AUTOSAR XML (schema 4-2-2)
package /STELLANTIS/EPT/ASWCs
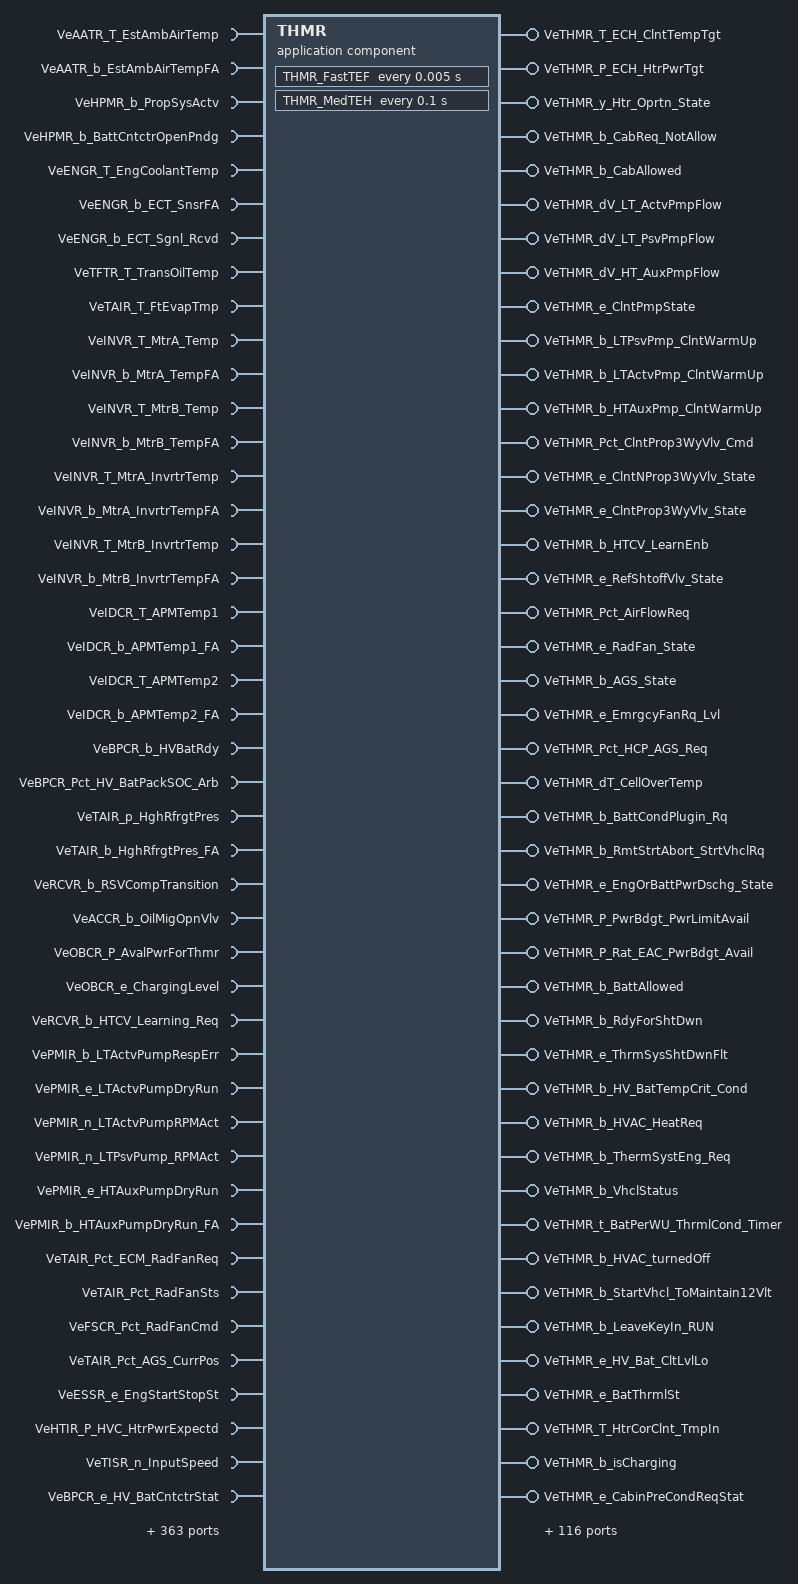
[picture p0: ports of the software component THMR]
  application sw component type THMR
    404 x require port:
      VeAATR_T_EstAmbAirTemp: nonqueued-receiver-com-spec{data-element=Value, init-value=0}, required-interface=VeAATR_T_EstAmbAirTemp
      VeAATR_b_EstAmbAirTempFA: nonqueued-receiver-com-spec{data-element=Value, init-value=0}, required-interface=VeAATR_b_EstAmbAirTempFA
      VeHPMR_b_PropSysActv: nonqueued-receiver-com-spec{data-element=Value, init-value=0}, required-interface=VeHPMR_b_PropSysActv
      VeHPMR_b_BattCntctrOpenPndg: nonqueued-receiver-com-spec{data-element=Value, init-value=0}, required-interface=VeHPMR_b_BattCntctrOpenPndg
      VeENGR_T_EngCoolantTemp: nonqueued-receiver-com-spec{data-element=Value, init-value=0}, required-interface=VeENGR_T_EngCoolantTemp
      VeENGR_b_ECT_SnsrFA: nonqueued-receiver-com-spec{data-element=Value, init-value=0}, required-interface=VeENGR_b_ECT_SnsrFA
      VeENGR_b_ECT_Sgnl_Rcvd: nonqueued-receiver-com-spec{data-element=Value, init-value=0}, required-interface=VeENGR_b_ECT_Sgnl_Rcvd
      VeTFTR_T_TransOilTemp: nonqueued-receiver-com-spec{data-element=Value, init-value=0}, required-interface=VeTFTR_T_TransOilTemp
      VeTAIR_T_FtEvapTmp: nonqueued-receiver-com-spec{data-element=Value, init-value=0}, required-interface=VeTAIR_T_FtEvapTmp
      VeINVR_T_MtrA_Temp: nonqueued-receiver-com-spec{data-element=Value, init-value=0}, required-interface=VeINVR_T_MtrA_Temp
      VeINVR_b_MtrA_TempFA: nonqueued-receiver-com-spec{data-element=Value, init-value=0}, required-interface=VeINVR_b_MtrA_TempFA
      VeINVR_T_MtrB_Temp: nonqueued-receiver-com-spec{data-element=Value, init-value=0}, required-interface=VeINVR_T_MtrB_Temp
      VeINVR_b_MtrB_TempFA: nonqueued-receiver-com-spec{data-element=Value, init-value=0}, required-interface=VeINVR_b_MtrB_TempFA
      VeINVR_T_MtrA_InvrtrTemp: nonqueued-receiver-com-spec{data-element=Value, init-value=0}, required-interface=VeINVR_T_MtrA_InvrtrTemp
      VeINVR_b_MtrA_InvrtrTempFA: nonqueued-receiver-com-spec{data-element=Value, init-value=0}, required-interface=VeINVR_b_MtrA_InvrtrTempFA
      VeINVR_T_MtrB_InvrtrTemp: nonqueued-receiver-com-spec{data-element=Value, init-value=0}, required-interface=VeINVR_T_MtrB_InvrtrTemp
      VeINVR_b_MtrB_InvrtrTempFA: nonqueued-receiver-com-spec{data-element=Value, init-value=0}, required-interface=VeINVR_b_MtrB_InvrtrTempFA
      VeIDCR_T_APMTemp1: nonqueued-receiver-com-spec{data-element=Value, init-value=0}, required-interface=VeIDCR_T_APMTemp1
      VeIDCR_b_APMTemp1_FA: nonqueued-receiver-com-spec{data-element=Value, init-value=0}, required-interface=VeIDCR_b_APMTemp1_FA
      VeIDCR_T_APMTemp2: nonqueued-receiver-com-spec{data-element=Value, init-value=0}, required-interface=VeIDCR_T_APMTemp2
      VeIDCR_b_APMTemp2_FA: nonqueued-receiver-com-spec{data-element=Value, init-value=0}, required-interface=VeIDCR_b_APMTemp2_FA
      VeBPCR_b_HVBatRdy: nonqueued-receiver-com-spec{data-element=Value, init-value=0}, required-interface=VeBPCR_b_HVBatRdy
      VeBPCR_Pct_HV_BatPackSOC_Arb: nonqueued-receiver-com-spec{data-element=Value, init-value=0}, required-interface=VeBPCR_Pct_HV_BatPackSOC_Arb
      VeTAIR_p_HghRfrgtPres: nonqueued-receiver-com-spec{data-element=Value, init-value=0}, required-interface=VeTAIR_p_HghRfrgtPres
      VeTAIR_b_HghRfrgtPres_FA: nonqueued-receiver-com-spec{data-element=Value, init-value=0}, required-interface=VeTAIR_b_HghRfrgtPres_FA
      VeRCVR_b_RSVCompTransition: nonqueued-receiver-com-spec{data-element=Value, init-value=0}, required-interface=VeRCVR_b_RSVCompTransition
      VeACCR_b_OilMigOpnVlv: nonqueued-receiver-com-spec{data-element=Value, init-value=0}, required-interface=VeACCR_b_OilMigOpnVlv
      VeOBCR_P_AvalPwrForThmr: nonqueued-receiver-com-spec{data-element=Value, init-value=0}, required-interface=VeOBCR_P_AvalPwrForThmr
      VeOBCR_e_ChargingLevel: nonqueued-receiver-com-spec{data-element=Value, init-value=CeOBCR_e_ChargingLvlDefault}, required-interface=VeOBCR_e_ChargingLevel
      VeRCVR_b_HTCV_Learning_Req: nonqueued-receiver-com-spec{data-element=Value, init-value=0}, required-interface=VeRCVR_b_HTCV_Learning_Req
      VePMIR_b_LTActvPumpRespErr: nonqueued-receiver-com-spec{data-element=Value, init-value=0}, required-interface=VePMIR_b_LTActvPumpRespErr
      VePMIR_e_LTActvPumpDryRun: nonqueued-receiver-com-spec{data-element=Value, init-value=CePMPR_e_FTSNA_False}, required-interface=VePMIR_e_LTActvPumpDryRun
      VePMIR_n_LTActvPumpRPMAct: nonqueued-receiver-com-spec{data-element=Value, init-value=0}, required-interface=VePMIR_n_LTActvPumpRPMAct
      VePMIR_n_LTPsvPump_RPMAct: nonqueued-receiver-com-spec{data-element=Value, init-value=0}, required-interface=VePMIR_n_LTPsvPump_RPMAct
      VePMIR_e_HTAuxPumpDryRun: nonqueued-receiver-com-spec{data-element=Value, init-value=CePMPR_e_FTSNA_False}, required-interface=VePMIR_e_HTAuxPumpDryRun
      VePMIR_b_HTAuxPumpDryRun_FA: nonqueued-receiver-com-spec{data-element=Value, init-value=0}, required-interface=VePMIR_b_HTAuxPumpDryRun_FA
      VeTAIR_Pct_ECM_RadFanReq: nonqueued-receiver-com-spec{data-element=Value, init-value=0}, required-interface=VeTAIR_Pct_ECM_RadFanReq
      VeTAIR_Pct_RadFanSts: nonqueued-receiver-com-spec{data-element=Value, init-value=0}, required-interface=VeTAIR_Pct_RadFanSts
      VeFSCR_Pct_RadFanCmd: nonqueued-receiver-com-spec{data-element=Value, init-value=0}, required-interface=VeFSCR_Pct_RadFanCmd
      VeTAIR_Pct_AGS_CurrPos: nonqueued-receiver-com-spec{data-element=Value, init-value=0}, required-interface=VeTAIR_Pct_AGS_CurrPos
      VeESSR_e_EngStartStopSt: nonqueued-receiver-com-spec{data-element=Value, init-value=CeESSR_e_EngOff}, required-interface=VeESSR_e_EngStartStopSt
      VeHTIR_P_HVC_HtrPwrExpectd: nonqueued-receiver-com-spec{data-element=Value, init-value=0}, required-interface=VeHTIR_P_HVC_HtrPwrExpectd
      VeTISR_n_InputSpeed: nonqueued-receiver-com-spec{data-element=Value, init-value=0}, required-interface=VeTISR_n_InputSpeed
      VeBPCR_e_HV_BatCntctrStat: nonqueued-receiver-com-spec{data-element=Value, init-value=CeHVTR_e_Open}, required-interface=VeBPCR_e_HV_BatCntctrStat
      VeTRGR_e_TransDirctnSt: nonqueued-receiver-com-spec{data-element=Value, init-value=CeTRGR_e_NoSelectionAvailable}, required-interface=VeTRGR_e_TransDirctnSt
      VeCSVR_v_VehSpd: nonqueued-receiver-com-spec{data-element=Value, init-value=0}, required-interface=VeCSVR_v_VehSpd
      VePLTR_b_DrvDrAjar: nonqueued-receiver-com-spec{data-element=Value, init-value=0}, required-interface=VePLTR_b_DrvDrAjar
      VeSSDR_e_KeySts: nonqueued-receiver-com-spec{data-element=Value, init-value=CeSSDR_e_KeyOff}, required-interface=VeSSDR_e_KeySts
      VeACCR_b_OverTempImminent: nonqueued-receiver-com-spec{data-element=Value, init-value=0}, required-interface=VeACCR_b_OverTempImminent
      VeTAIR_b_ACCompReq: nonqueued-receiver-com-spec{data-element=Value, init-value=0}, required-interface=VeTAIR_b_ACCompReq
      VeIMPR_b_HighVoltageRapidShtdwnCmnd: nonqueued-receiver-com-spec{data-element=Value, init-value=0}, required-interface=VeIMPR_b_HighVoltageRapidShtdwnCmnd
      VeENGR_b_EngSysLowFuel: nonqueued-receiver-com-spec{data-element=Value, init-value=0}, required-interface=VeENGR_b_EngSysLowFuel
      VeMSPR_n_MtrA_Spd: nonqueued-receiver-com-spec{data-element=Value, init-value=0}, required-interface=VeMSPR_n_MtrA_Spd
      VeMSPR_n_MtrB_Spd: nonqueued-receiver-com-spec{data-element=Value, init-value=0}, required-interface=VeMSPR_n_MtrB_Spd
      VeHTDR_M_MtrA_TorqCmnd: nonqueued-receiver-com-spec{data-element=Value, init-value=0}, required-interface=VeHTDR_M_MtrA_TorqCmnd
      VeMTIR_M_MtrA_TorqAchieved: nonqueued-receiver-com-spec{data-element=Value, init-value=0}, required-interface=VeMTIR_M_MtrA_TorqAchieved
      VeHTDR_M_MtrB_TorqCmnd: nonqueued-receiver-com-spec{data-element=Value, init-value=0}, required-interface=VeHTDR_M_MtrB_TorqCmnd
      VeMTIR_M_MtrB_TorqAchieved: nonqueued-receiver-com-spec{data-element=Value, init-value=0}, required-interface=VeMTIR_M_MtrB_TorqAchieved
      VeHTDR_P_MtrAElecPwrCalcTot: nonqueued-receiver-com-spec{data-element=Value, init-value=0}, required-interface=VeHTDR_P_MtrAElecPwrCalcTot
      VeHTDR_P_MtrBElecPwrCalcTot: nonqueued-receiver-com-spec{data-element=Value, init-value=0}, required-interface=VeHTDR_P_MtrBElecPwrCalcTot
      VeHTDR_r_AHH_StressFactor: nonqueued-receiver-com-spec{data-element=Value, init-value=0}, required-interface=VeHTDR_r_AHH_StressFactor
      VeBRKR_e_AHH_Ready_Status: nonqueued-receiver-com-spec{data-element=Value, init-value=CeBRKR_e_AHH_NotReady}, required-interface=VeBRKR_e_AHH_Ready_Status
      VeHTIR_T_HVC_HtrClntIn_Temp: nonqueued-receiver-com-spec{data-element=Value, init-value=0}, required-interface=VeHTIR_T_HVC_HtrClntIn_Temp
      VeTAIR_b_HT_CabVlvSts_FA: nonqueued-receiver-com-spec{data-element=Value, init-value=0}, required-interface=VeTAIR_b_HT_CabVlvSts_FA
      VeCPDR_b_HTAP_FunPer_FltDtct: nonqueued-receiver-com-spec{data-element=Value, init-value=0}, required-interface=VeCPDR_b_HTAP_FunPer_FltDtct
      VePMIR_b_LTPsvPumpTemp_FA: nonqueued-receiver-com-spec{data-element=Value, init-value=0}, required-interface=VePMIR_b_LTPsvPumpTemp_FA
      VeHTIR_e_HV_ElecClntHtr_Sts: nonqueued-receiver-com-spec{data-element=Value, init-value=CeHTIR_e_HtrSts_Off}, required-interface=VeHTIR_e_HV_ElecClntHtr_Sts
      VeINVR_T_MtrA_RotrTemp: nonqueued-receiver-com-spec{data-element=Value, init-value=0}, required-interface=VeINVR_T_MtrA_RotrTemp
      VeINVR_b_MtrA_RotrTemp_FA: nonqueued-receiver-com-spec{data-element=Value, init-value=0}, required-interface=VeINVR_b_MtrA_RotrTemp_FA
      VeINVR_T_MtrA_CtrlBoard_Temp: nonqueued-receiver-com-spec{data-element=Value, init-value=0}, required-interface=VeINVR_T_MtrA_CtrlBoard_Temp
      VeINVR_b_MtrA_CtrlBoard_Temp_FA: nonqueued-receiver-com-spec{data-element=Value, init-value=0}, required-interface=VeINVR_b_MtrA_CtrlBoard_Temp_FA
      VeINVR_T_MtrA_ClntIn_Temp: nonqueued-receiver-com-spec{data-element=Value, init-value=0}, required-interface=VeINVR_T_MtrA_ClntIn_Temp
      VeINVR_b_MtrA_ClntIn_Temp_FA: nonqueued-receiver-com-spec{data-element=Value, init-value=0}, required-interface=VeINVR_b_MtrA_ClntIn_Temp_FA
      VeINVR_T_MtrA_ClntOut_Temp: nonqueued-receiver-com-spec{data-element=Value, init-value=0}, required-interface=VeINVR_T_MtrA_ClntOut_Temp
      VeINVR_b_MtrA_ClntOut_Temp_FA: nonqueued-receiver-com-spec{data-element=Value, init-value=0}, required-interface=VeINVR_b_MtrA_ClntOut_Temp_FA
      VeINVR_T_MtrA_CapctrTemp: nonqueued-receiver-com-spec{data-element=Value, init-value=0}, required-interface=VeINVR_T_MtrA_CapctrTemp
      VeINVR_b_MtrA_CapctrTemp_FA: nonqueued-receiver-com-spec{data-element=Value, init-value=0}, required-interface=VeINVR_b_MtrA_CapctrTemp_FA
      VePMIR_Pct_ECM_LTPsvPumpRq: nonqueued-receiver-com-spec{data-element=Value, init-value=0}, required-interface=VePMIR_Pct_ECM_LTPsvPumpRq
      VePMIR_b_ECM_LTPsvPumpRq_FA: nonqueued-receiver-com-spec{data-element=Value, init-value=0}, required-interface=VePMIR_b_ECM_LTPsvPumpRq_FA
      VeENGR_T_InductionAirTemp: nonqueued-receiver-com-spec{data-element=Value, init-value=0}, required-interface=VeENGR_T_InductionAirTemp
      VeTPCR_t_BatPerWU_ThrmlCond_Timer: nonqueued-receiver-com-spec{data-element=Value, init-value=0}, required-interface=VeTPCR_t_BatPerWU_ThrmlCond_Timer
      VeTPCR_b_PeriodWup_Msg2: variation-point={short-label=vpVeTPCR_b_PeriodWup_Msg2, sw-syscond=1}, nonqueued-receiver-com-spec{data-element=Value, init-value=0}, required-interface=VeTPCR_b_PeriodWup_Msg2
      VeTPCR_e_ThrmPerWup_State: nonqueued-receiver-com-spec{data-element=Value, init-value=CeTPCR_e_NoWup_Set_ShortTim_RS_Denied}, required-interface=VeTPCR_e_ThrmPerWup_State
      VeTPCR_e_PerWup_BattEngCond_State: nonqueued-receiver-com-spec{data-element=Value, init-value=CeTPCR_e_NoneOfEngBatt_Cond}, required-interface=VeTPCR_e_PerWup_BattEngCond_State
      VeTPCR_dT_PerWpCond_EngTmpErr: nonqueued-receiver-com-spec{data-element=Value, init-value=0}, required-interface=VeTPCR_dT_PerWpCond_EngTmpErr
      VeTPCR_dT_PerWpCond_BatTmpErr: nonqueued-receiver-com-spec{data-element=Value, init-value=0}, required-interface=VeTPCR_dT_PerWpCond_BatTmpErr
      VeTPCR_e_CabinPreCondReqStat: nonqueued-receiver-com-spec{data-element=Value, init-value=CeTPCR_e_CabinPrec_Dflt}, required-interface=VeTPCR_e_CabinPreCondReqStat
      VeTPCR_b_RSA_BatCrit_Msg3: variation-point={short-label=vpVeTPCR_b_RSA_BatCrit_Msg3, sw-syscond=1}, nonqueued-receiver-com-spec{data-element=Value, init-value=0}, required-interface=VeTPCR_b_RSA_BatCrit_Msg3
      VeTPCR_b_HtrOrEAC_FltRawPrst: nonqueued-receiver-com-spec{data-element=Value, init-value=0}, required-interface=VeTPCR_b_HtrOrEAC_FltRawPrst
      VeTPCR_b_RdyForShtDwn: nonqueued-receiver-com-spec{data-element=Value, init-value=0}, required-interface=VeTPCR_b_RdyForShtDwn
      VeTRIR_T_HtrCorClnt_TmpIn: nonqueued-receiver-com-spec{data-element=Value, init-value=0}, required-interface=VeTRIR_T_HtrCorClnt_TmpIn
      VeTRIR_b_HtrCorClnt_TmpIn_FA: nonqueued-receiver-com-spec{data-element=Value, init-value=0}, required-interface=VeTRIR_b_HtrCorClnt_TmpIn_FA
      VeCTRR_b_HVAC_HeatReq: nonqueued-receiver-com-spec{data-element=Value, init-value=0}, required-interface=VeCTRR_b_HVAC_HeatReq
      VeCTRR_b_HardCabHeat_Req: nonqueued-receiver-com-spec{data-element=Value, init-value=0}, required-interface=VeCTRR_b_HardCabHeat_Req
      VeCTRR_b_CabPriorityHigh: nonqueued-receiver-com-spec{data-element=Value, init-value=0}, required-interface=VeCTRR_b_CabPriorityHigh
      VeBTRR_T_CellTempMaxUsed: nonqueued-receiver-com-spec{data-element=Value, init-value=0}, required-interface=VeBTRR_T_CellTempMaxUsed
      VeBTRR_T_CellTempMinUsed: nonqueued-receiver-com-spec{data-element=Value, init-value=0}, required-interface=VeBTRR_T_CellTempMinUsed
      VeBTRR_dT_CellTempDelta: nonqueued-receiver-com-spec{data-element=Value, init-value=0}, required-interface=VeBTRR_dT_CellTempDelta
      VeBTRR_b_HVBR_OvrdReq: variation-point={short-label=vpVeBTRR_b_HVBR_OvrdReq, sw-syscond=1}, nonqueued-receiver-com-spec{data-element=Value, init-value=0}, required-interface=VeBTRR_b_HVBR_OvrdReq
      VeBTRR_dT_CellOverTemp: nonqueued-receiver-com-spec{data-element=Value, init-value=0}, required-interface=VeBTRR_dT_CellOverTemp
      VeBTRR_dV_LT_ActPmpFlw: nonqueued-receiver-com-spec{data-element=Value, init-value=0}, required-interface=VeBTRR_dV_LT_ActPmpFlw
      VeBTRR_b_PerWup_BatToCond: nonqueued-receiver-com-spec{data-element=Value, init-value=0}, required-interface=VeBTRR_b_PerWup_BatToCond
      VeBTRR_b_HV_BatTempCrit_Cond: nonqueued-receiver-com-spec{data-element=Value, init-value=0}, required-interface=VeBTRR_b_HV_BatTempCrit_Cond
      VeBTRR_e_HV_BatTempCrit_CondState_New: nonqueued-receiver-com-spec{data-element=Value, init-value=CeBTRR_e_BatNotCrit}, required-interface=VeBTRR_e_HV_BatTempCrit_CondState_New
      VeBTRR_b_BattHeatReq: nonqueued-receiver-com-spec{data-element=Value, init-value=0}, required-interface=VeBTRR_b_BattHeatReq
      VeBTRR_b_isCharging: nonqueued-receiver-com-spec{data-element=Value, init-value=0}, required-interface=VeBTRR_b_isCharging
      VeBTRR_b_BattCondPlugin_Rq: variation-point={short-label=vpVeBTRR_b_BattCondPlugin_Rq, sw-syscond=1}, nonqueued-receiver-com-spec{data-element=Value, init-value=0}, required-interface=VeBTRR_b_BattCondPlugin_Rq
      VeBTRR_b_PlugdIn_Or_Chrg: nonqueued-receiver-com-spec{data-element=Value, init-value=0}, required-interface=VeBTRR_b_PlugdIn_Or_Chrg
      VeBTRR_b_BattCellBalancing: nonqueued-receiver-com-spec{data-element=Value, init-value=0}, required-interface=VeBTRR_b_BattCellBalancing
      VeBTRR_e_HV_BatTmpRng: nonqueued-receiver-com-spec{data-element=Value, init-value=CeBTRR_e_BatTmpDfltRng}, required-interface=VeBTRR_e_HV_BatTmpRng
      VeBTRR_b_Batt_CritOrMarg: nonqueued-receiver-com-spec{data-element=Value, init-value=0}, required-interface=VeBTRR_b_Batt_CritOrMarg
      VeBTRR_e_BatCondPriority: nonqueued-receiver-com-spec{data-element=Value, init-value=CeBTRR_e_BatCond_NoPriority}, required-interface=VeBTRR_e_BatCondPriority
      VeBTRR_b_VhclPlgdIn: nonqueued-receiver-com-spec{data-element=Value, init-value=0}, required-interface=VeBTRR_b_VhclPlgdIn
      VeBTRR_P_BatHeatPwr_NeedLimtd: nonqueued-receiver-com-spec{data-element=Value, init-value=0}, required-interface=VeBTRR_P_BatHeatPwr_NeedLimtd
      VeBRDR_e_HV_Bat_CltLvlLo: nonqueued-receiver-com-spec{data-element=Value, init-value=CeBRDR_e_BatCltLvlNotLo}, required-interface=VeBRDR_e_HV_Bat_CltLvlLo
      VeBTRR_T_BTISBTIS2_Max: nonqueued-receiver-com-spec{data-element=Value, init-value=0}, required-interface=VeBTRR_T_BTISBTIS2_Max
      VePMDR_e_KeyStatus: nonqueued-receiver-com-spec{data-element=Value, init-value=CePMDR_e_KeySt_Off}, required-interface=VePMDR_e_KeyStatus
      VePMPR_e_LTPsvPump_PstRnSt: nonqueued-receiver-com-spec{data-element=Value, init-value=CeTMIR_e_No_AftRunRequest}, required-interface=VePMPR_e_LTPsvPump_PstRnSt
      VeCTRR_b_TurnOffEng_CabComfAchvd: nonqueued-receiver-com-spec{data-element=Value, init-value=0}, required-interface=VeCTRR_b_TurnOffEng_CabComfAchvd
      VeCTRR_dT_HtrCorTmp_Err: nonqueued-receiver-com-spec{data-element=Value, init-value=0}, required-interface=VeCTRR_dT_HtrCorTmp_Err
      VePMIR_n_LTPsvPump2RPMAct: nonqueued-receiver-com-spec{data-element=Value, init-value=0}, required-interface=VePMIR_n_LTPsvPump2RPMAct
      VePMIR_b_LTPsvPump2Temp_FA: nonqueued-receiver-com-spec{data-element=Value, init-value=0}, required-interface=VePMIR_b_LTPsvPump2Temp_FA
      VePMPR_e_LTPsvPump2_PstRnSt: nonqueued-receiver-com-spec{data-element=Value, init-value=CeTMIR_e_No_AftRunRequest}, required-interface=VePMPR_e_LTPsvPump2_PstRnSt
      VePDTR_b_KeyRun_OV_BattCrit: nonqueued-receiver-com-spec{data-element=Value, init-value=0}, required-interface=VePDTR_b_KeyRun_OV_BattCrit
      VePDTR_e_EngOrBattPwrDschg_State: nonqueued-receiver-com-spec{data-element=Value, init-value=CePDTR_e_No_Dischrg}, required-interface=VePDTR_e_EngOrBattPwrDschg_State
      VePDTR_b_KeyRunCrnk_BattOV: nonqueued-receiver-com-spec{data-element=Value, init-value=0}, required-interface=VePDTR_b_KeyRunCrnk_BattOV
      VeHCDR_b_HVC_Heater_FltDtct: nonqueued-receiver-com-spec{data-element=Value, init-value=0}, required-interface=VeHCDR_b_HVC_Heater_FltDtct
      VeHCDR_b_HV_Heater{2..4}_FltDtct: nonqueued-receiver-com-spec{data-element=Value, init-value=0}, required-interface=VeHCDR_b_HV_Heater{2..4}_FltDtct
      VePMIR_b_LTActvPumpDryRun_FA: nonqueued-receiver-com-spec{data-element=Value, init-value=0}, required-interface=VePMIR_b_LTActvPumpDryRun_FA
      VeCPDR_b_LTAP_FunPer_FltDtct: nonqueued-receiver-com-spec{data-element=Value, init-value=0}, required-interface=VeCPDR_b_LTAP_FunPer_FltDtct
      VeTRIR_b_AHP_EnblReq: nonqueued-receiver-com-spec{data-element=Value, init-value=0}, required-interface=VeTRIR_b_AHP_EnblReq
      VeFSCR_b_HoodAjarBatCrit: nonqueued-receiver-com-spec{data-element=Value, init-value=0}, required-interface=VeFSCR_b_HoodAjarBatCrit
      VeAVTR_b_SDS_CoolingReq: nonqueued-receiver-com-spec{data-element=Value, init-value=0}, required-interface=VeAVTR_b_SDS_CoolingReq
      VeAVTR_e_EVA_ThrmlState: nonqueued-receiver-com-spec{data-element=Value, init-value=CeAVTR_e_NoEVACond}, required-interface=VeAVTR_e_EVA_ThrmlState
      VeFSCR_b_RadFan_FltDtct: nonqueued-receiver-com-spec{data-element=Value, init-value=0}, required-interface=VeFSCR_b_RadFan_FltDtct
      VeFSCR_b_HVFuncRejHdAjar: nonqueued-receiver-com-spec{data-element=Value, init-value=0}, required-interface=VeFSCR_b_HVFuncRejHdAjar
      VePMPR_b_LTPsvPump_Flt_Dtctd: nonqueued-receiver-com-spec{data-element=Value, init-value=0}, required-interface=VePMPR_b_LTPsvPump_Flt_Dtctd
      VePMPR_b_LTPsvPump2_Flt_Dtctd: nonqueued-receiver-com-spec{data-element=Value, init-value=0}, required-interface=VePMPR_b_LTPsvPump2_Flt_Dtctd
      VePMPR_b_LTActPump_Flt_Dtctd: nonqueued-receiver-com-spec{data-element=Value, init-value=0}, required-interface=VePMPR_b_LTActPump_Flt_Dtctd
      VePMPR_b_HTAuxPump_Flt_Dtctd: nonqueued-receiver-com-spec{data-element=Value, init-value=0}, required-interface=VePMPR_b_HTAuxPump_Flt_Dtctd
      VePMPR_n_PECP_RPM_Op_St: nonqueued-receiver-com-spec{data-element=Value, init-value=0}, required-interface=VePMPR_n_PECP_RPM_Op_St
      VePMPR_n_PECP2_RPM_Op_St: nonqueued-receiver-com-spec{data-element=Value, init-value=0}, required-interface=VePMPR_n_PECP2_RPM_Op_St
      VeHCDR_e_BatteryThermalFault: nonqueued-receiver-com-spec{data-element=Value, init-value=CeHCDR_e_BattThermalNoFault}, required-interface=VeHCDR_e_BatteryThermalFault
      VeHPMR_e_HybSysSt: nonqueued-receiver-com-spec{data-element=Value, init-value=CeHPMR_e_POWERUP}, required-interface=VeHPMR_e_HybSysSt
      VeBTRR_b_ThrmlBatCoolingFlt: nonqueued-receiver-com-spec{data-element=Value, init-value=0}, required-interface=VeBTRR_b_ThrmlBatCoolingFlt
      VeTPCR_t_SC_PrecTimer: nonqueued-receiver-com-spec{data-element=Value, init-value=0}, required-interface=VeTPCR_t_SC_PrecTimer
      VeTPCR_e_SC_WakeUp: nonqueued-receiver-com-spec{data-element=Value, init-value=CeTPCR_e_SC_NotAwake}, required-interface=VeTPCR_e_SC_WakeUp
      VeSRAR_b_ThmlLoadShdActv: nonqueued-receiver-com-spec{data-element=Value, init-value=0}, required-interface=VeSRAR_b_ThmlLoadShdActv
      VePLTR_t_RTC_CurrentTime: nonqueued-receiver-com-spec{data-element=Value, init-value=0}, required-interface=VePLTR_t_RTC_CurrentTime
      VePLTR_b_RTC_CurrentTimeFA: nonqueued-receiver-com-spec{data-element=Value, init-value=0}, required-interface=VePLTR_b_RTC_CurrentTimeFA
      VePLTR_t_RTC_SleepTime: nonqueued-receiver-com-spec{data-element=Value, init-value=0}, required-interface=VePLTR_t_RTC_SleepTime
      VeBPCR_e_BPCM_LIN_BusOff: nonqueued-receiver-com-spec{data-element=Value, init-value=CeBPCR_e_LIN_BusOff_Disabled}, required-interface=VeBPCR_e_BPCM_LIN_BusOff
      VeBPCR_b_BPCM_LIN_BusOff_FA: nonqueued-receiver-com-spec{data-element=Value, init-value=0}, required-interface=VeBPCR_b_BPCM_LIN_BusOff_FA
      VeBPCR_b_BPCM_LIN_BusOff_SgnlRcvd: nonqueued-receiver-com-spec{data-element=Value, init-value=0}, required-interface=VeBPCR_b_BPCM_LIN_BusOff_SgnlRcvd
      VeBPCR_e_BPCM_LOC_BCP: nonqueued-receiver-com-spec{data-element=Value, init-value=CeBPCR_e_LOC_BCP_False}, required-interface=VeBPCR_e_BPCM_LOC_BCP
      VeBPCR_b_BPCM_LOC_BCP_FA: nonqueued-receiver-com-spec{data-element=Value, init-value=0}, required-interface=VeBPCR_b_BPCM_LOC_BCP_FA
      VeBPCR_b_BPCM_LOC_BCP_SgnlRcvd: nonqueued-receiver-com-spec{data-element=Value, init-value=0}, required-interface=VeBPCR_b_BPCM_LOC_BCP_SgnlRcvd
      VePMPR_n_LT_ActvPmpCmd: nonqueued-receiver-com-spec{data-element=Value, init-value=0}, required-interface=VePMPR_n_LT_ActvPmpCmd
      VeTRIR_T_HV_BatClntTmpOut: nonqueued-receiver-com-spec{data-element=Value, init-value=0}, required-interface=VeTRIR_T_HV_BatClntTmpOut
      VeTPCR_b_CabPrecDny_BattCond: nonqueued-receiver-com-spec{data-element=Value, init-value=0}, required-interface=VeTPCR_b_CabPrecDny_BattCond
      VeBTRR_dT_CellUnderTemp: nonqueued-receiver-com-spec{data-element=Value, init-value=0}, required-interface=VeBTRR_dT_CellUnderTemp
      VeBTRR_b_HVBattPriority: variation-point={short-label=vpVeBTRR_b_HVBattPriority, sw-syscond=1}, nonqueued-receiver-com-spec{data-element=Value, init-value=0}, required-interface=VeBTRR_b_HVBattPriority
      VeTAIR_b_WinshldDfrst: nonqueued-receiver-com-spec{data-element=Value, init-value=0}, required-interface=VeTAIR_b_WinshldDfrst
      VeDFIR_b_Flashing_InProgress: nonqueued-receiver-com-spec{data-element=Value, init-value=0}, required-interface=VeDFIR_b_Flashing_InProgress
      VeHTIR_e_HV_ElecClntHtr2_Sts: nonqueued-receiver-com-spec{data-element=Value, init-value=CeHTIR_e_HtrSts_Off}, required-interface=VeHTIR_e_HV_ElecClntHtr2_Sts
      VeCTRR_P_ErrBasedHeatPwr: nonqueued-receiver-com-spec{data-element=Value, init-value=0}, required-interface=VeCTRR_P_ErrBasedHeatPwr
      VeDMDR_e_TurtleMdSts: nonqueued-receiver-com-spec{data-element=Value, init-value=CeDMDR_e_No_Turtle_Mode}, required-interface=VeDMDR_e_TurtleMdSts
      VeUBTR_T_EstUndrhoodTemp: nonqueued-receiver-com-spec{data-element=Value, init-value=0}, required-interface=VeUBTR_T_EstUndrhoodTemp
      VeTPCR_e_CabReqSt_Msgs: nonqueued-receiver-com-spec{data-element=Value, init-value=CeTPCR_e_CabinPrec_Dflt}, required-interface=VeTPCR_e_CabReqSt_Msgs
      VeBTRR_b_BattCoolFlts: variation-point={short-label=vpVeBTRR_b_BattCoolFlts, sw-syscond=1}, nonqueued-receiver-com-spec{data-element=Value, init-value=0}, required-interface=VeBTRR_b_BattCoolFlts
      VeTMIR_T_PsvPmpClnt_TmpIn: nonqueued-receiver-com-spec{data-element=Value, init-value=0}, required-interface=VeTMIR_T_PsvPmpClnt_TmpIn
      VeTMIR_b_PsvPmpClnt_TmpIn_FA: nonqueued-receiver-com-spec{data-element=Value, init-value=0}, required-interface=VeTMIR_b_PsvPmpClnt_TmpIn_FA
      VeTMIR_T_OnBrdChrg_ClntTmpIn: nonqueued-receiver-com-spec{data-element=Value, init-value=0}, required-interface=VeTMIR_T_OnBrdChrg_ClntTmpIn
      VeTMIR_b_OnBrdChrg_ClntTmpIn_FA: nonqueued-receiver-com-spec{data-element=Value, init-value=0}, required-interface=VeTMIR_b_OnBrdChrg_ClntTmpIn_FA
      VeTMIR_T_OBCMTemp1: nonqueued-receiver-com-spec{data-element=Value, init-value=0}, required-interface=VeTMIR_T_OBCMTemp1
      VeTMIR_b_OBCMTemp1_FA: nonqueued-receiver-com-spec{data-element=Value, init-value=0}, required-interface=VeTMIR_b_OBCMTemp1_FA
      VeTMIR_T_OBCMTemp2: nonqueued-receiver-com-spec{data-element=Value, init-value=0}, required-interface=VeTMIR_T_OBCMTemp2
      VeTMIR_b_OBCMTemp2_FA: nonqueued-receiver-com-spec{data-element=Value, init-value=0}, required-interface=VeTMIR_b_OBCMTemp2_FA
      VeTMIR_T_ElecClntHtr_TmpIn: nonqueued-receiver-com-spec{data-element=Value, init-value=0}, required-interface=VeTMIR_T_ElecClntHtr_TmpIn
      VeTMIR_b_ElecClntHtr_TmpIn_FA: nonqueued-receiver-com-spec{data-element=Value, init-value=0}, required-interface=VeTMIR_b_ElecClntHtr_TmpIn_FA
      VeTMIR_Pct_BSG_ECM_RadFanRq: nonqueued-receiver-com-spec{data-element=Value, init-value=0}, required-interface=VeTMIR_Pct_BSG_ECM_RadFanRq
      VeTMIR_Pct_BSG_PPU_AirFlwRq: nonqueued-receiver-com-spec{data-element=Value, init-value=0}, required-interface=VeTMIR_Pct_BSG_PPU_AirFlwRq
      VeTMIR_Pct_BSG_LTR_PmpSpdAct: nonqueued-receiver-com-spec{data-element=Value, init-value=0}, required-interface=VeTMIR_Pct_BSG_LTR_PmpSpdAct
      VeTMIR_e_ECM_LTP_FanAftRunRq: nonqueued-receiver-com-spec{data-element=Value, init-value=CeTMIR_e_No_AftRunRequest}, required-interface=VeTMIR_e_ECM_LTP_FanAftRunRq
      VeTMIR_b_ECM_FanAftRunRq_FA: nonqueued-receiver-com-spec{data-element=Value, init-value=0}, required-interface=VeTMIR_b_ECM_FanAftRunRq_FA
      VeTMIR_T_CntrlBrdTmp_Snsr1_AD: nonqueued-receiver-com-spec{data-element=Value, init-value=0}, required-interface=VeTMIR_T_CntrlBrdTmp_Snsr1_AD
      VeTMIR_b_CntrlBrdTmp_Snsr1_FA_AD: nonqueued-receiver-com-spec{data-element=Value, init-value=0}, required-interface=VeTMIR_b_CntrlBrdTmp_Snsr1_FA_AD
      VeTMIR_T_CntrlBrdTmp_Snsr2_AD: nonqueued-receiver-com-spec{data-element=Value, init-value=0}, required-interface=VeTMIR_T_CntrlBrdTmp_Snsr2_AD
      VeTMIR_b_CntrlBrdTmp_Snsr2_FA_AD: nonqueued-receiver-com-spec{data-element=Value, init-value=0}, required-interface=VeTMIR_b_CntrlBrdTmp_Snsr2_FA_AD
      VeTMIR_b_ECMDrvDoorAjar: nonqueued-receiver-com-spec{data-element=Value, init-value=0}, required-interface=VeTMIR_b_ECMDrvDoorAjar
      VeTMIR_y_OBCMTemp1_Dbg: nonqueued-receiver-com-spec{data-element=Value, init-value=0}, required-interface=VeTMIR_y_OBCMTemp1_Dbg
      VeTMIR_y_OBCMTemp2_Dbg: nonqueued-receiver-com-spec{data-element=Value, init-value=0}, required-interface=VeTMIR_y_OBCMTemp2_Dbg
      VeTMIR_Pct_TCU_Load_Index: nonqueued-receiver-com-spec{data-element=Value, init-value=0}, required-interface=VeTMIR_Pct_TCU_Load_Index
      VeTMIR_b_TCU_Load_Index_FA: nonqueued-receiver-com-spec{data-element=Value, init-value=0}, required-interface=VeTMIR_b_TCU_Load_Index_FA
      VeTMIR_T_OBCMTemp3_AD: nonqueued-receiver-com-spec{data-element=Value, init-value=0}, required-interface=VeTMIR_T_OBCMTemp3_AD
      VeTMIR_b_OBCMTemp3_FA_AD: nonqueued-receiver-com-spec{data-element=Value, init-value=0}, required-interface=VeTMIR_b_OBCMTemp3_FA_AD
      VeTMIR_T_OBCMTemp4_AD: nonqueued-receiver-com-spec{data-element=Value, init-value=0}, required-interface=VeTMIR_T_OBCMTemp4_AD
      VeTMIR_b_OBCMTemp4_FA_AD: nonqueued-receiver-com-spec{data-element=Value, init-value=0}, required-interface=VeTMIR_b_OBCMTemp4_FA_AD
      VePMTR_b_ThrmlSystRly_EnblCmnd: nonqueued-receiver-com-spec{data-element=Value, init-value=0}, required-interface=VePMTR_b_ThrmlSystRly_EnblCmnd
      VePMTR_e_ThrmlDevEnbl: nonqueued-receiver-com-spec{data-element=Value, init-value=CePMTR_e_DISBL_All_Thrml}, required-interface=VePMTR_e_ThrmlDevEnbl
      VePMTR_b_REM_BattHeatAction: nonqueued-receiver-com-spec{data-element=Value, init-value=0}, required-interface=VePMTR_b_REM_BattHeatAction
      VePMTR_b_REM_CabHeatAction: nonqueued-receiver-com-spec{data-element=Value, init-value=0}, required-interface=VePMTR_b_REM_CabHeatAction
      VePMTR_b_REM_BattCoolAction: nonqueued-receiver-com-spec{data-element=Value, init-value=0}, required-interface=VePMTR_b_REM_BattCoolAction
      VePMTR_b_REM_CabCoolAction: nonqueued-receiver-com-spec{data-element=Value, init-value=0}, required-interface=VePMTR_b_REM_CabCoolAction
      VePLTR_b_REMDisabled: nonqueued-receiver-com-spec{data-element=Value, init-value=0}, required-interface=VePLTR_b_REMDisabled
      VePLTR_e_ShippingMode: nonqueued-receiver-com-spec{data-element=Value, init-value=CePLTR_e_ShipingMode_CUST_MD}, required-interface=VePLTR_e_ShippingMode
      VeTAIR_Pct_AGS2_CurrPos: nonqueued-receiver-com-spec{data-element=Value, init-value=0}, required-interface=VeTAIR_Pct_AGS2_CurrPos
      VeTHDR_b_PPCTIS_OT_FltDtct: nonqueued-receiver-com-spec{data-element=Value, init-value=0}, required-interface=VeTHDR_b_PPCTIS_OT_FltDtct
      VeINVR_T_MtrB_RotrTemp: nonqueued-receiver-com-spec{data-element=Value, init-value=0}, required-interface=VeINVR_T_MtrB_RotrTemp
      VeINVR_b_MtrB_RotrTemp_FA: nonqueued-receiver-com-spec{data-element=Value, init-value=0}, required-interface=VeINVR_b_MtrB_RotrTemp_FA
      VeINVR_T_MtrB_CtrlBoard_Temp: nonqueued-receiver-com-spec{data-element=Value, init-value=0}, required-interface=VeINVR_T_MtrB_CtrlBoard_Temp
      VeINVR_b_MtrB_CtrlBoard_Temp_FA: nonqueued-receiver-com-spec{data-element=Value, init-value=0}, required-interface=VeINVR_b_MtrB_CtrlBoard_Temp_FA
      VeINVR_T_MtrB_ClntIn_Temp: nonqueued-receiver-com-spec{data-element=Value, init-value=0}, required-interface=VeINVR_T_MtrB_ClntIn_Temp
      VeINVR_b_MtrB_ClntIn_Temp_FA: nonqueued-receiver-com-spec{data-element=Value, init-value=0}, required-interface=VeINVR_b_MtrB_ClntIn_Temp_FA
      VeINVR_T_MtrB_ClntOut_Temp: nonqueued-receiver-com-spec{data-element=Value, init-value=0}, required-interface=VeINVR_T_MtrB_ClntOut_Temp
      VeINVR_b_MtrB_ClntOut_Temp_FA: nonqueued-receiver-com-spec{data-element=Value, init-value=0}, required-interface=VeINVR_b_MtrB_ClntOut_Temp_FA
      VeINVR_T_MtrB_CapctrTemp: nonqueued-receiver-com-spec{data-element=Value, init-value=0}, required-interface=VeINVR_T_MtrB_CapctrTemp
      VeINVR_b_MtrB_CapctrTemp_FA: nonqueued-receiver-com-spec{data-element=Value, init-value=0}, required-interface=VeINVR_b_MtrB_CapctrTemp_FA
      VeDMIR_e_DrvMdRaw: nonqueued-receiver-com-spec{data-element=Value, init-value=CeDMDR_e_NoDrvMd}, required-interface=VeDMIR_e_DrvMdRaw
      VeBTRR_b_KeyRun_OV_BattCrit: nonqueued-receiver-com-spec{data-element=Value, init-value=0}, required-interface=VeBTRR_b_KeyRun_OV_BattCrit
      VeTPDR_P_Rat_EAC_PwrBdgt_Avail: nonqueued-receiver-com-spec{data-element=Value, init-value=0}, required-interface=VeTPDR_P_Rat_EAC_PwrBdgt_Avail
      VeTPDR_P_CabinHeater_PwrBdgt_Avail: nonqueued-receiver-com-spec{data-element=Value, init-value=0}, required-interface=VeTPDR_P_CabinHeater_PwrBdgt_Avail
      VeTPDR_P_BattHeater_PwrBdgt_Avail: nonqueued-receiver-com-spec{data-element=Value, init-value=0}, required-interface=VeTPDR_P_BattHeater_PwrBdgt_Avail
      VeTRIR_T_HtrCorClnt_TmpOut: nonqueued-receiver-com-spec{data-element=Value, init-value=0}, required-interface=VeTRIR_T_HtrCorClnt_TmpOut
      VeCTRR_T_HtrCoreTmp_Tgt_Arb: nonqueued-receiver-com-spec{data-element=Value, init-value=0}, required-interface=VeCTRR_T_HtrCoreTmp_Tgt_Arb
      VeBTRR_b_Psv_BattHeatReq: nonqueued-receiver-com-spec{data-element=Value, init-value=0}, required-interface=VeBTRR_b_Psv_BattHeatReq
      VeTAIR_Pct_HTL_BypsVlv_ActlPstn: nonqueued-receiver-com-spec{data-element=Value, init-value=0}, required-interface=VeTAIR_Pct_HTL_BypsVlv_ActlPstn
      VeTAIR_Pct_LTR_BypsVlv_ActlPstn: nonqueued-receiver-com-spec{data-element=Value, init-value=0}, required-interface=VeTAIR_Pct_LTR_BypsVlv_ActlPstn
      VeTMIR_T_LTR_ClntTmpOut: nonqueued-receiver-com-spec{data-element=Value, init-value=0}, required-interface=VeTMIR_T_LTR_ClntTmpOut
      VeTRIR_b_HtrCorClnt_TmpOut_FA: nonqueued-receiver-com-spec{data-element=Value, init-value=0}, required-interface=VeTRIR_b_HtrCorClnt_TmpOut_FA
      VePMPR_dV_BattFlw: nonqueued-receiver-com-spec{data-element=Value, init-value=0}, required-interface=VePMPR_dV_BattFlw
      VeTPCR_b_KeyOffCabCond: nonqueued-receiver-com-spec{data-element=Value, init-value=0}, required-interface=VeTPCR_b_KeyOffCabCond
      VeHTIR_e_HV_ElecClntHtr4_Sts: nonqueued-receiver-com-spec{data-element=Value, init-value=CeHTIR_e_HtrSts_Off}, required-interface=VeHTIR_e_HV_ElecClntHtr4_Sts
      VeHTIR_P_HVC_Htr4PwrExpectd: nonqueued-receiver-com-spec{data-element=Value, init-value=0}, required-interface=VeHTIR_P_HVC_Htr4PwrExpectd
      VePMPR_dV_HtrFlw: nonqueued-receiver-com-spec{data-element=Value, init-value=0}, required-interface=VePMPR_dV_HtrFlw
      VePMPR_dV_LTRFlw: nonqueued-receiver-com-spec{data-element=Value, init-value=0}, required-interface=VePMPR_dV_LTRFlw
      VePMIR_n_HTAuxPumpRPMAct: nonqueued-receiver-com-spec{data-element=Value, init-value=0}, required-interface=VePMIR_n_HTAuxPumpRPMAct
      VeHTIR_T_HVC_HtrClntOut_Temp: nonqueued-receiver-com-spec{data-element=Value, init-value=0}, required-interface=VeHTIR_T_HVC_HtrClntOut_Temp
      VePMIR_T_HTAuxPumpTemp: nonqueued-receiver-com-spec{data-element=Value, init-value=0}, required-interface=VePMIR_T_HTAuxPumpTemp
      VePMIR_T_LTPsvPump2Temp: nonqueued-receiver-com-spec{data-element=Value, init-value=0}, required-interface=VePMIR_T_LTPsvPump2Temp
      VeTMIR_b_LTR_ClntTmpOut_FA: nonqueued-receiver-com-spec{data-element=Value, init-value=0}, required-interface=VeTMIR_b_LTR_ClntTmpOut_FA
      VeRCVR_e_CPV_Valve_Stuck_State: nonqueued-receiver-com-spec{data-element=Value, init-value=CeRCVR_e_Closed}, required-interface=VeRCVR_e_CPV_Valve_Stuck_State
      VeRCVR_e_LTR_Valve_Stuck_State: nonqueued-receiver-com-spec{data-element=Value, init-value=CeRCVR_e_Closed}, required-interface=VeRCVR_e_LTR_Valve_Stuck_State
      VeRCVR_e_HTL_Valve_Stuck_State: nonqueued-receiver-com-spec{data-element=Value, init-value=CeRCVR_e_Closed}, required-interface=VeRCVR_e_HTL_Valve_Stuck_State
      VeTPCR_e_ProactiveCondStat: nonqueued-receiver-com-spec{data-element=Value, init-value=CeTPCR_e_ProactiveCondOff}, required-interface=VeTPCR_e_ProactiveCondStat
      VeTPCR_e_ProactiveCondMode: nonqueued-receiver-com-spec{data-element=Value, init-value=CeTPCR_e_NoProactiveCond}, required-interface=VeTPCR_e_ProactiveCondMode
      VeBTRR_b_BattCoolReq: nonqueued-receiver-com-spec{data-element=Value, init-value=0}, required-interface=VeBTRR_b_BattCoolReq
      VeBTRR_b_Batt_PsvCoolReq: nonqueued-receiver-com-spec{data-element=Value, init-value=0}, required-interface=VeBTRR_b_Batt_PsvCoolReq
      VePDTR_b_OV_EPD_BattCool_Req: nonqueued-receiver-com-spec{data-element=Value, init-value=0}, required-interface=VePDTR_b_OV_EPD_BattCool_Req
      VePDTR_b_OV_EPD_BattHeat_Req: nonqueued-receiver-com-spec{data-element=Value, init-value=0}, required-interface=VePDTR_b_OV_EPD_BattHeat_Req
      VeCTRR_b_TrueCab_HeatReq: nonqueued-receiver-com-spec{data-element=Value, init-value=0}, required-interface=VeCTRR_b_TrueCab_HeatReq
      VeBTRR_b_BattCoolReq_CPV_RA: nonqueued-receiver-com-spec{data-element=Value, init-value=0}, required-interface=VeBTRR_b_BattCoolReq_CPV_RA
      VeCITR_e_FOTA_Install_Type: nonqueued-receiver-com-spec{data-element=Value, init-value=CeCITR_e_NoFOTA}, required-interface=VeCITR_e_FOTA_Install_Type
      VePLTR_b_DriverDetected: nonqueued-receiver-com-spec{data-element=Value, init-value=0}, required-interface=VePLTR_b_DriverDetected
      VeINVR_T_MtrC_Temp: nonqueued-receiver-com-spec{data-element=Value, init-value=0}, required-interface=VeINVR_T_MtrC_Temp
      VeINVR_b_MtrC_TempFA: nonqueued-receiver-com-spec{data-element=Value, init-value=0}, required-interface=VeINVR_b_MtrC_TempFA
      VeINVR_T_MtrC_InvrtrTemp: nonqueued-receiver-com-spec{data-element=Value, init-value=0}, required-interface=VeINVR_T_MtrC_InvrtrTemp
      VeINVR_b_MtrC_InvrtrTempFA: nonqueued-receiver-com-spec{data-element=Value, init-value=0}, required-interface=VeINVR_b_MtrC_InvrtrTempFA
      VeINVR_T_MtrC_RotrTemp: nonqueued-receiver-com-spec{data-element=Value, init-value=0}, required-interface=VeINVR_T_MtrC_RotrTemp
      VeINVR_b_MtrC_RotrTemp_FA: nonqueued-receiver-com-spec{data-element=Value, init-value=0}, required-interface=VeINVR_b_MtrC_RotrTemp_FA
      VeINVR_T_MtrC_CtrlBoard_Temp: nonqueued-receiver-com-spec{data-element=Value, init-value=0}, required-interface=VeINVR_T_MtrC_CtrlBoard_Temp
      VeINVR_b_MtrC_CtrlBoard_Temp_FA: nonqueued-receiver-com-spec{data-element=Value, init-value=0}, required-interface=VeINVR_b_MtrC_CtrlBoard_Temp_FA
      VePMIR_T_TransAuxPumpOilTemp: nonqueued-receiver-com-spec{data-element=Value, init-value=0}, required-interface=VePMIR_T_TransAuxPumpOilTemp
      VePMIR_b_TransAuxPumpOilTemp_FA: nonqueued-receiver-com-spec{data-element=Value, init-value=0}, required-interface=VePMIR_b_TransAuxPumpOilTemp_FA
      VePMIR_T_TransAuxPump2OilTemp: nonqueued-receiver-com-spec{data-element=Value, init-value=0}, required-interface=VePMIR_T_TransAuxPump2OilTemp
      VePMIR_b_TransAuxPump2OilTemp_FA: nonqueued-receiver-com-spec{data-element=Value, init-value=0}, required-interface=VePMIR_b_TransAuxPump2OilTemp_FA
      VeOBCR_I_ChrgCrntReqDelta: nonqueued-receiver-com-spec{data-element=Value, init-value=0}, required-interface=VeOBCR_I_ChrgCrntReqDelta
      VeBPCR_U_HV_BatVolt: nonqueued-receiver-com-spec{data-element=Value, init-value=0}, required-interface=VeBPCR_U_HV_BatVolt
      VeOBCR_e_PwrLevSet: nonqueued-receiver-com-spec{data-element=Value, init-value=CeOBCR_e_PwrLimReq_SNA}, required-interface=VeOBCR_e_PwrLevSet
      VeTRIR_e_HVACECOModeSts: nonqueued-receiver-com-spec{data-element=Value, init-value=CeTRIR_e_HVAC_ECO_OFF}, required-interface=VeTRIR_e_HVACECOModeSts
      VeMTIR_M_MtrC_TorqAchieved: nonqueued-receiver-com-spec{data-element=Value, init-value=0}, required-interface=VeMTIR_M_MtrC_TorqAchieved
      VeCTRR_b_RearHeaterReq: nonqueued-receiver-com-spec{data-element=Value, init-value=0}, required-interface=VeCTRR_b_RearHeaterReq
      VeCTRR_P_RearHeaterPwrReq: nonqueued-receiver-com-spec{data-element=Value, init-value=0}, required-interface=VeCTRR_P_RearHeaterPwrReq
      VeTPDR_P_RearHtr_PwrBdgt_Avail: nonqueued-receiver-com-spec{data-element=Value, init-value=0}, required-interface=VeTPDR_P_RearHtr_PwrBdgt_Avail
      VeTAIR_T_OEXV_OutTempSens: nonqueued-receiver-com-spec{data-element=Value, init-value=0}, required-interface=VeTAIR_T_OEXV_OutTempSens
      VeTAIR_n_CompSpdFdb: nonqueued-receiver-com-spec{data-element=Value, init-value=0}, required-interface=VeTAIR_n_CompSpdFdb
      VeGENR_b_HVDspt_Enbl: nonqueued-receiver-com-spec{data-element=Value, init-value=0}, required-interface=VeGENR_b_HVDspt_Enbl
      VeRCVR_p_eACSuctionPressure: nonqueued-receiver-com-spec{data-element=Value, init-value=0}, required-interface=VeRCVR_p_eACSuctionPressure
      VeACCR_b_eAC4CabInhibtd: nonqueued-receiver-com-spec{data-element=Value, init-value=0}, required-interface=VeACCR_b_eAC4CabInhibtd
      VeTAIR_T_FtEvapTmp_Tgt: nonqueued-receiver-com-spec{data-element=Value, init-value=0}, required-interface=VeTAIR_T_FtEvapTmp_Tgt
      VeTAIR_Pct_FrtBlwrCmd: nonqueued-receiver-com-spec{data-element=Value, init-value=0}, required-interface=VeTAIR_Pct_FrtBlwrCmd
      VeTAIR_P_AC_CompElecPwr: nonqueued-receiver-com-spec{data-element=Value, init-value=0}, required-interface=VeTAIR_P_AC_CompElecPwr
      VeTAIR_b_AC_CompElecPwr_FA: nonqueued-receiver-com-spec{data-element=Value, init-value=0}, required-interface=VeTAIR_b_AC_CompElecPwr_FA
      VeVTLR_e_DschrgSysSts: nonqueued-receiver-com-spec{data-element=Value, init-value=CeVTLR_e_DschrgInactv}, required-interface=VeVTLR_e_DschrgSysSts
      VeTRIR_e_ClimateInfo: nonqueued-receiver-com-spec{data-element=Value, init-value=CeTRIR_e_SPST_ON}, required-interface=VeTRIR_e_ClimateInfo
      VeTRIR_b_ClimateInfo_FA: nonqueued-receiver-com-spec{data-element=Value, init-value=0}, required-interface=VeTRIR_b_ClimateInfo_FA
      VeFSCR_b_AGS_CalSuccess: nonqueued-receiver-com-spec{data-element=Value, init-value=0}, required-interface=VeFSCR_b_AGS_CalSuccess
      VeFSCR_b_AGS2_CalSuccess: nonqueued-receiver-com-spec{data-element=Value, init-value=0}, required-interface=VeFSCR_b_AGS2_CalSuccess
      VeFCRR_b_FcCoolReq: nonqueued-receiver-com-spec{data-element=Value, init-value=0}, required-interface=VeFCRR_b_FcCoolReq
      VeFCRR_b_FcHeatReq: nonqueued-receiver-com-spec{data-element=Value, init-value=0}, required-interface=VeFCRR_b_FcHeatReq
      VeFCPR_P_FCPS_ActPwr: nonqueued-receiver-com-spec{data-element=Value, init-value=0}, required-interface=VeFCPR_P_FCPS_ActPwr
      VeFCRR_e_FcTempRange: nonqueued-receiver-com-spec{data-element=Value, init-value=CeFCRR_e_Nominal}, required-interface=VeFCRR_e_FcTempRange
      VeTRIR_Pct_AirHtrPwrTgt: nonqueued-receiver-com-spec{data-element=Value, init-value=0}, required-interface=VeTRIR_Pct_AirHtrPwrTgt
      VeTRIR_b_AirHtrPwrTgt_FA: nonqueued-receiver-com-spec{data-element=Value, init-value=0}, required-interface=VeTRIR_b_AirHtrPwrTgt_FA
      VeCTRR_b_AmbientChillCond: nonqueued-receiver-com-spec{data-element=Value, init-value=0}, required-interface=VeCTRR_b_AmbientChillCond
      VeCTRR_b_MinFlowCabHeatReq: nonqueued-receiver-com-spec{data-element=Value, init-value=0}, required-interface=VeCTRR_b_MinFlowCabHeatReq
      VeHTIR_T_Htr2CoreTemp: nonqueued-receiver-com-spec{data-element=Value, init-value=0}, required-interface=VeHTIR_T_Htr2CoreTemp
      VeDMAB_y_StatusByte_CoolOutTempSnsCkt: nonqueued-receiver-com-spec{data-element=Value, init-value=0}, required-interface=VeDMAB_y_StatusByte_CoolOutTempSnsCkt
      VeDMAB_y_StatusByte_HB_CT_SnsrPerf: nonqueued-receiver-com-spec{data-element=Value, init-value=0}, required-interface=VeDMAB_y_StatusByte_HB_CT_SnsrPerf
      VeDMAB_y_StatusByte_BattCoolPmpATempSnsrPerf: nonqueued-receiver-com-spec{data-element=Value, init-value=0}, required-interface=VeDMAB_y_StatusByte_BattCoolPmpATempSnsrPerf
      VeDMAB_y_StatusByte_BattCoolPmpPerf: nonqueued-receiver-com-spec{data-element=Value, init-value=0}, required-interface=VeDMAB_y_StatusByte_BattCoolPmpPerf
      VeDMAB_y_StatusByte_CoolPmpACtrlCktPerf: nonqueued-receiver-com-spec{data-element=Value, init-value=0}, required-interface=VeDMAB_y_StatusByte_CoolPmpACtrlCktPerf
      VeDMAB_y_StatusByte_LostCommCoolPmpA: nonqueued-receiver-com-spec{data-element=Value, init-value=0}, required-interface=VeDMAB_y_StatusByte_LostCommCoolPmpA
      VeDMAB_y_StatusByte_ECH_TempIn: nonqueued-receiver-com-spec{data-element=Value, init-value=0}, required-interface=VeDMAB_y_StatusByte_ECH_TempIn
      VeDMAB_y_StatusByte_ECH_TempOut: nonqueued-receiver-com-spec{data-element=Value, init-value=0}, required-interface=VeDMAB_y_StatusByte_ECH_TempOut
      VeDMAB_y_StatusByte_InvData_EAH: nonqueued-receiver-com-spec{data-element=Value, init-value=0}, required-interface=VeDMAB_y_StatusByte_InvData_EAH
      VeDMAB_y_StatusByte_InvData_ECH: nonqueued-receiver-com-spec{data-element=Value, init-value=0}, required-interface=VeDMAB_y_StatusByte_InvData_ECH
      VeDMAB_y_StatusByte_LIN1_BusOff: nonqueued-receiver-com-spec{data-element=Value, init-value=0}, required-interface=VeDMAB_y_StatusByte_LIN1_BusOff
      VeDMAB_y_StatusByte_LIN2_BusOff: nonqueued-receiver-com-spec{data-element=Value, init-value=0}, required-interface=VeDMAB_y_StatusByte_LIN2_BusOff
      VeDMAB_y_StatusByte_LostCommCoolHtrA: nonqueued-receiver-com-spec{data-element=Value, init-value=0}, required-interface=VeDMAB_y_StatusByte_LostCommCoolHtrA
      VeDMAB_y_StatusByte_CT3_SnsrCktHi: nonqueued-receiver-com-spec{data-element=Value, init-value=0}, required-interface=VeDMAB_y_StatusByte_CT3_SnsrCktHi
      VeDMAB_y_StatusByte_CT3_SnsrCktLo: nonqueued-receiver-com-spec{data-element=Value, init-value=0}, required-interface=VeDMAB_y_StatusByte_CT3_SnsrCktLo
      VeDMAB_y_StatusByte_CT3_SnsrPerf: nonqueued-receiver-com-spec{data-element=Value, init-value=0}, required-interface=VeDMAB_y_StatusByte_CT3_SnsrPerf
      VeDMAB_y_StatusByte_ECT_Snsr4CktHi: nonqueued-receiver-com-spec{data-element=Value, init-value=0}, required-interface=VeDMAB_y_StatusByte_ECT_Snsr4CktHi
      VeDMAB_y_StatusByte_ECT_Snsr4CktLo: nonqueued-receiver-com-spec{data-element=Value, init-value=0}, required-interface=VeDMAB_y_StatusByte_ECT_Snsr4CktLo
      VeDMAB_y_StatusByte_ECT_Snsr4CktPerf: nonqueued-receiver-com-spec{data-element=Value, init-value=0}, required-interface=VeDMAB_y_StatusByte_ECT_Snsr4CktPerf
      VeDMAB_y_StatusByte_CoolantVlvA_CktHi: nonqueued-receiver-com-spec{data-element=Value, init-value=0}, required-interface=VeDMAB_y_StatusByte_CoolantVlvA_CktHi
      VeDMAB_y_StatusByte_CoolantVlvA_CktLo: nonqueued-receiver-com-spec{data-element=Value, init-value=0}, required-interface=VeDMAB_y_StatusByte_CoolantVlvA_CktLo
      VeDMAB_y_StatusByte_CoolantVlvA_Ckt: nonqueued-receiver-com-spec{data-element=Value, init-value=0}, required-interface=VeDMAB_y_StatusByte_CoolantVlvA_Ckt
      VeDMAB_y_StatusByte_CoolantVlvA_Perf: nonqueued-receiver-com-spec{data-element=Value, init-value=0}, required-interface=VeDMAB_y_StatusByte_CoolantVlvA_Perf
      VeDMAB_y_StatusByte_CoolantVlvA_StkOpn: nonqueued-receiver-com-spec{data-element=Value, init-value=0}, required-interface=VeDMAB_y_StatusByte_CoolantVlvA_StkOpn
      VeDMAB_y_StatusByte_LostCommMtrElectCoolPmpA: nonqueued-receiver-com-spec{data-element=Value, init-value=0}, required-interface=VeDMAB_y_StatusByte_LostCommMtrElectCoolPmpA
      VeDMAB_y_StatusByte_MtrElect_CoolPumAOvrSpd: nonqueued-receiver-com-spec{data-element=Value, init-value=0}, required-interface=VeDMAB_y_StatusByte_MtrElect_CoolPumAOvrSpd
      VeDMAB_y_StatusByte_PwrElecPmpPerf: nonqueued-receiver-com-spec{data-element=Value, init-value=0}, required-interface=VeDMAB_y_StatusByte_PwrElecPmpPerf
      VeDMAB_y_StatusByte_LostCommMtrElectCoolPmpB: nonqueued-receiver-com-spec{data-element=Value, init-value=0}, required-interface=VeDMAB_y_StatusByte_LostCommMtrElectCoolPmpB
      VeDMAB_y_StatusByte_MtrElect_CooPumBOvrSpd: nonqueued-receiver-com-spec{data-element=Value, init-value=0}, required-interface=VeDMAB_y_StatusByte_MtrElect_CooPumBOvrSpd
      VeDMAB_y_StatusByte_MtrElect_CT2_SnsrBCktHi: nonqueued-receiver-com-spec{data-element=Value, init-value=0}, required-interface=VeDMAB_y_StatusByte_MtrElect_CT2_SnsrBCktHi
      VeDMAB_y_StatusByte_MtrElect_CT2_SnsrBCktLo: nonqueued-receiver-com-spec{data-element=Value, init-value=0}, required-interface=VeDMAB_y_StatusByte_MtrElect_CT2_SnsrBCktLo
      VeDMAB_y_StatusByte_MtrElect_CT_SnsrBPerf: nonqueued-receiver-com-spec{data-element=Value, init-value=0}, required-interface=VeDMAB_y_StatusByte_MtrElect_CT_SnsrBPerf
      VeDMAB_y_StatusByte_MtrElect_CoolPumBCtrlPerf: nonqueued-receiver-com-spec{data-element=Value, init-value=0}, required-interface=VeDMAB_y_StatusByte_MtrElect_CoolPumBCtrlPerf
      VeDMAB_y_StatusByte_HybEvBatPacCoolCtrlVlv2CtrlCktLo: nonqueued-receiver-com-spec{data-element=Value, init-value=0}, required-interface=VeDMAB_y_StatusByte_HybEvBatPacCoolCtrlVlv2CtrlCktLo
      VeDMAB_y_StatusByte_HybEvBatPacCoolCtrlVlvBPerfStkOff: nonqueued-receiver-com-spec{data-element=Value, init-value=0}, required-interface=VeDMAB_y_StatusByte_HybEvBatPacCoolCtrlVlvBPerfStkOff
      VeDMAB_y_StatusByte_CT_SnsrPerf: nonqueued-receiver-com-spec{data-element=Value, init-value=0}, required-interface=VeDMAB_y_StatusByte_CT_SnsrPerf
      VeDMAB_y_StatusByte_MtrElect_CT_SnsrPerf: nonqueued-receiver-com-spec{data-element=Value, init-value=0}, required-interface=VeDMAB_y_StatusByte_MtrElect_CT_SnsrPerf
      VeDMAB_y_StatusByte_MtrElect_CoolPmpATempSnsrPerf: nonqueued-receiver-com-spec{data-element=Value, init-value=0}, required-interface=VeDMAB_y_StatusByte_MtrElect_CoolPmpATempSnsrPerf
      VeDMAB_y_StatusByte_MtrElect_CoolPmpBTempSnsrPerf: nonqueued-receiver-com-spec{data-element=Value, init-value=0}, required-interface=VeDMAB_y_StatusByte_MtrElect_CoolPmpBTempSnsrPerf
      VeDMAB_y_StatusByte_BattCoolPmpHtrBTempSnsrPerf: nonqueued-receiver-com-spec{data-element=Value, init-value=0}, required-interface=VeDMAB_y_StatusByte_BattCoolPmpHtrBTempSnsrPerf
      VeDMAB_y_StatusByte_CoolantHeaterBPerf: nonqueued-receiver-com-spec{data-element=Value, init-value=0}, required-interface=VeDMAB_y_StatusByte_CoolantHeaterBPerf
      VeDMAB_y_StatusByte_LostCommHB_CooltHtr4: nonqueued-receiver-com-spec{data-element=Value, init-value=0}, required-interface=VeDMAB_y_StatusByte_LostCommHB_CooltHtr4
      VeDMAB_y_StatusByte_BattCoolPmpOveSpd: nonqueued-receiver-com-spec{data-element=Value, init-value=0}, required-interface=VeDMAB_y_StatusByte_BattCoolPmpOveSpd
      VeDMAB_y_StatusByte_CommBusOff: nonqueued-receiver-com-spec{data-element=Value, init-value=0}, required-interface=VeDMAB_y_StatusByte_CommBusOff
      VeDMAB_y_StatusByte_CommBus_B_Off: nonqueued-receiver-com-spec{data-element=Value, init-value=0}, required-interface=VeDMAB_y_StatusByte_CommBus_B_Off
      VeDMAB_y_StatusByte_HiSpdCANCommBus: nonqueued-receiver-com-spec{data-element=Value, init-value=0}, required-interface=VeDMAB_y_StatusByte_HiSpdCANCommBus
      VeDMAB_y_StatusByte_ThrmlRlyCtrlCkt: nonqueued-receiver-com-spec{data-element=Value, init-value=0}, required-interface=VeDMAB_y_StatusByte_ThrmlRlyCtrlCkt
      VeDMAB_y_StatusByte_LostCommHB_CoolPmp: nonqueued-receiver-com-spec{data-element=Value, init-value=0}, required-interface=VeDMAB_y_StatusByte_LostCommHB_CoolPmp
      VeDMAB_y_StatusByte_AC_RefrigPresSnsrAHi: nonqueued-receiver-com-spec{data-element=Value, init-value=0}, required-interface=VeDMAB_y_StatusByte_AC_RefrigPresSnsrAHi
      VeDMAB_y_StatusByte_AC_RefrigPresSnsrALo: nonqueued-receiver-com-spec{data-element=Value, init-value=0}, required-interface=VeDMAB_y_StatusByte_AC_RefrigPresSnsrALo
      VeDMAB_y_StatusByte_AC_RefrigPresSnsrAPerf: nonqueued-receiver-com-spec{data-element=Value, init-value=0}, required-interface=VeDMAB_y_StatusByte_AC_RefrigPresSnsrAPerf
      VeDMAB_y_StatusByte_BattCool: nonqueued-receiver-com-spec{data-element=Value, init-value=0}, required-interface=VeDMAB_y_StatusByte_BattCool
      VeDMAB_y_StatusByte_CoolCtrlVlv1CktHi: nonqueued-receiver-com-spec{data-element=Value, init-value=0}, required-interface=VeDMAB_y_StatusByte_CoolCtrlVlv1CktHi
      VeDMAB_y_StatusByte_EACPerf: nonqueued-receiver-com-spec{data-element=Value, init-value=0}, required-interface=VeDMAB_y_StatusByte_EACPerf
      VeDMAB_y_StatusByte_LostCommEAC: nonqueued-receiver-com-spec{data-element=Value, init-value=0}, required-interface=VeDMAB_y_StatusByte_LostCommEAC
      VeDMAB_y_StatusByte_LosCommBECM_A_CANC11: nonqueued-receiver-com-spec{data-element=Value, init-value=0}, required-interface=VeDMAB_y_StatusByte_LosCommBECM_A_CANC11
      VeDMAB_y_StatusByte_LosCommBECM_A: nonqueued-receiver-com-spec{data-element=Value, init-value=0}, required-interface=VeDMAB_y_StatusByte_LosCommBECM_A
      VeDMAB_y_StatusByte_AGS_A_Perf: nonqueued-receiver-com-spec{data-element=Value, init-value=0}, required-interface=VeDMAB_y_StatusByte_AGS_A_Perf
      VeDMAB_y_StatusByte_AGS_B_Perf: nonqueued-receiver-com-spec{data-element=Value, init-value=0}, required-interface=VeDMAB_y_StatusByte_AGS_B_Perf
      VeDMAB_y_StatusByte_LostComm_AGS_A: nonqueued-receiver-com-spec{data-element=Value, init-value=0}, required-interface=VeDMAB_y_StatusByte_LostComm_AGS_A
      VeDMAB_y_StatusByte_LostComm_AGS_B: nonqueued-receiver-com-spec{data-element=Value, init-value=0}, required-interface=VeDMAB_y_StatusByte_LostComm_AGS_B
      VeMSPR_n_MtrC_Spd: nonqueued-receiver-com-spec{data-element=Value, init-value=0}, required-interface=VeMSPR_n_MtrC_Spd
      VeHTDR_M_MtrC_TorqCmnd: nonqueued-receiver-com-spec{data-element=Value, init-value=0}, required-interface=VeHTDR_M_MtrC_TorqCmnd
      VeHTDR_P_MtrCElecPwrCalcTot: nonqueued-receiver-com-spec{data-element=Value, init-value=0}, required-interface=VeHTDR_P_MtrCElecPwrCalcTot
      VeHCCR_dV_LubFlowPump1: variation-point={short-label=vpVeHCCR_dV_LubFlowPump1, sw-syscond=1}, nonqueued-receiver-com-spec{data-element=Value, init-value=0}, required-interface=VeHCCR_dV_LubFlowPump1
      VeHCCR_dV_FlowLimiterPump1: variation-point={short-label=vpVeHCCR_dV_FlowLimiterPump1, sw-syscond=1}, nonqueued-receiver-com-spec{data-element=Value, init-value=0}, required-interface=VeHCCR_dV_FlowLimiterPump1
      VeHCCR_dV_LubFlowPump2: variation-point={short-label=vpVeHCCR_dV_LubFlowPump2, sw-syscond=1}, nonqueued-receiver-com-spec{data-element=Value, init-value=0}, required-interface=VeHCCR_dV_LubFlowPump2
      VeHCCR_dV_FlowLimiterPump2: variation-point={short-label=vpVeHCCR_dV_FlowLimiterPump2, sw-syscond=1}, nonqueued-receiver-com-spec{data-element=Value, init-value=0}, required-interface=VeHCCR_dV_FlowLimiterPump2
      VeINVR_T_BstCnvtrLwrIGBT_TmpFltd: nonqueued-receiver-com-spec{data-element=Value, init-value=0}, required-interface=VeINVR_T_BstCnvtrLwrIGBT_TmpFltd
      VeINVR_b_BstCnvtrLwrIGBT_TmpFltdFA: nonqueued-receiver-com-spec{data-element=Value, init-value=0}, required-interface=VeINVR_b_BstCnvtrLwrIGBT_TmpFltdFA
      VeINVR_T_BstCnvtrReactorTmp: nonqueued-receiver-com-spec{data-element=Value, init-value=0}, required-interface=VeINVR_T_BstCnvtrReactorTmp
      VeINVR_b_BstCnvtrReactorTmpFA: nonqueued-receiver-com-spec{data-element=Value, init-value=0}, required-interface=VeINVR_b_BstCnvtrReactorTmpFA
      VeINVR_T_BstCnvtrUpprIGBT_TmpFltd: nonqueued-receiver-com-spec{data-element=Value, init-value=0}, required-interface=VeINVR_T_BstCnvtrUpprIGBT_TmpFltd
      VeINVR_b_BstCnvtrUpprIGBT_TmpFltdFA: nonqueued-receiver-com-spec{data-element=Value, init-value=0}, required-interface=VeINVR_b_BstCnvtrUpprIGBT_TmpFltdFA
      VeTPCR_e_RacePrepState: nonqueued-receiver-com-spec{data-element=Value, init-value=CeTPCR_e_NotRacePrep}, required-interface=VeTPCR_e_RacePrepState
      VeFSCR_Pct_AGS1_MinAchvblPos: nonqueued-receiver-com-spec{data-element=Value, init-value=0}, required-interface=VeFSCR_Pct_AGS1_MinAchvblPos
      VeFSCR_Pct_AGS2_MinAchvblPos: nonqueued-receiver-com-spec{data-element=Value, init-value=0}, required-interface=VeFSCR_Pct_AGS2_MinAchvblPos
      VeCSVR_n_WhlSpdLHF: variation-point={short-label=vpVeCSVR_n_WhlSpdLHF, sw-syscond=1}, nonqueued-receiver-com-spec{data-element=Value, init-value=0}, required-interface=VeCSVR_n_WhlSpdLHF
      VeCSVR_n_WhlSpdLHR: variation-point={short-label=vpVeCSVR_n_WhlSpdLHR, sw-syscond=1}, nonqueued-receiver-com-spec{data-element=Value, init-value=0}, required-interface=VeCSVR_n_WhlSpdLHR
      VeCSVR_n_WhlSpdRHF: variation-point={short-label=vpVeCSVR_n_WhlSpdRHF, sw-syscond=1}, nonqueued-receiver-com-spec{data-element=Value, init-value=0}, required-interface=VeCSVR_n_WhlSpdRHF
      VeCSVR_n_WhlSpdRHR: variation-point={short-label=vpVeCSVR_n_WhlSpdRHR, sw-syscond=1}, nonqueued-receiver-com-spec{data-element=Value, init-value=0}, required-interface=VeCSVR_n_WhlSpdRHR
      VeCSVR_b_WhlSpdLHF_FA: variation-point={short-label=vpVeCSVR_b_WhlSpdLHF_FA, sw-syscond=1}, nonqueued-receiver-com-spec{data-element=Value, init-value=0}, required-interface=VeCSVR_b_WhlSpdLHF_FA
      VeCSVR_b_WhlSpdLHR_FA: variation-point={short-label=vpVeCSVR_b_WhlSpdLHR_FA, sw-syscond=1}, nonqueued-receiver-com-spec{data-element=Value, init-value=0}, required-interface=VeCSVR_b_WhlSpdLHR_FA
      VeCSVR_b_WhlSpdRHF_FA: variation-point={short-label=vpVeCSVR_b_WhlSpdRHF_FA, sw-syscond=1}, nonqueued-receiver-com-spec{data-element=Value, init-value=0}, required-interface=VeCSVR_b_WhlSpdRHF_FA
      VeCSVR_b_WhlSpdRHR_FA: variation-point={short-label=vpVeCSVR_b_WhlSpdRHR_FA, sw-syscond=1}, nonqueued-receiver-com-spec{data-element=Value, init-value=0}, required-interface=VeCSVR_b_WhlSpdRHR_FA
      VeTPCR_I_RacePrepCurrentLim: variation-point={short-label=vpVeTPCR_I_RacePrepCurrentLim, sw-syscond=1}, nonqueued-receiver-com-spec{data-element=Value, init-value=0}, required-interface=VeTPCR_I_RacePrepCurrentLim
      VeTRIR_T_HeatExCool_TmpOut: nonqueued-receiver-com-spec{data-element=Value, init-value=0}, required-interface=VeTRIR_T_HeatExCool_TmpOut
      VeHTIR_P_HVC_HtrPwrAct: nonqueued-receiver-com-spec{data-element=Value, init-value=0}, required-interface=VeHTIR_P_HVC_HtrPwrAct
      VePRXR_y_NumOfAGSUnits: nonqueued-receiver-com-spec{data-element=Value, init-value=0}, required-interface=VePRXR_y_NumOfAGSUnits
      VeFCRR_T_FcOutTempSetPoint: nonqueued-receiver-com-spec{data-element=Value, init-value=0}, required-interface=VeFCRR_T_FcOutTempSetPoint
      VeFCPR_T_FCPS_HTCoolOutTemp: nonqueued-receiver-com-spec{data-element=Value, init-value=0}, required-interface=VeFCPR_T_FCPS_HTCoolOutTemp
      VeFCPR_b_FCPS_HV_AfterRunSts: nonqueued-receiver-com-spec{data-element=Value, init-value=0}, required-interface=VeFCPR_b_FCPS_HV_AfterRunSts
      VeDMAB_y_StatusByte_RadCooTempSnsr3CktLo: nonqueued-receiver-com-spec{data-element=Value, init-value=0}, required-interface=VeDMAB_y_StatusByte_RadCooTempSnsr3CktLo
      VeDMAB_y_StatusByte_RadCooTempSnsr3CktHi: nonqueued-receiver-com-spec{data-element=Value, init-value=0}, required-interface=VeDMAB_y_StatusByte_RadCooTempSnsr3CktHi
      VeDMAB_y_StatusByte_RadCooTempSnsr3CktPerf: nonqueued-receiver-com-spec{data-element=Value, init-value=0}, required-interface=VeDMAB_y_StatusByte_RadCooTempSnsr3CktPerf
      VeTAIR_p_OEXV_OutPressSens: nonqueued-receiver-com-spec{data-element=Value, init-value=0}, required-interface=VeTAIR_p_OEXV_OutPressSens
      VeTAIR_b_OEXV_OutPressSens_FA: nonqueued-receiver-com-spec{data-element=Value, init-value=0}, required-interface=VeTAIR_b_OEXV_OutPressSens_FA
      VeDMAB_y_StatusByte_AC_RefrigTempSnsr5CktShotoGro: nonqueued-receiver-com-spec{data-element=Value, init-value=0}, required-interface=VeDMAB_y_StatusByte_AC_RefrigTempSnsr5CktShotoGro
      VeDMAB_y_StatusByte_AC_RefrigTempSnsr5CktShotoBat: nonqueued-receiver-com-spec{data-element=Value, init-value=0}, required-interface=VeDMAB_y_StatusByte_AC_RefrigTempSnsr5CktShotoBat
      VeDMAB_y_StatusByte_AC_RefrigTempSnsrDCkt: nonqueued-receiver-com-spec{data-element=Value, init-value=0}, required-interface=VeDMAB_y_StatusByte_AC_RefrigTempSnsrDCkt
      VeDMAB_y_StatusByte_AC_RefrigPresSnsrDCkt: nonqueued-receiver-com-spec{data-element=Value, init-value=0}, required-interface=VeDMAB_y_StatusByte_AC_RefrigPresSnsrDCkt
      VeDMAB_y_StatusByte_AC_RefrigTempSnsr5CktPerf: nonqueued-receiver-com-spec{data-element=Value, init-value=0}, required-interface=VeDMAB_y_StatusByte_AC_RefrigTempSnsr5CktPerf
      VeDMAB_y_StatusByte_AC_RefrigPresSnsrDCktPerf: nonqueued-receiver-com-spec{data-element=Value, init-value=0}, required-interface=VeDMAB_y_StatusByte_AC_RefrigPresSnsrDCktPerf
      VeDMAB_y_StatusByte_AC_RefrigTempSnsr4CktPerf: nonqueued-receiver-com-spec{data-element=Value, init-value=0}, required-interface=VeDMAB_y_StatusByte_AC_RefrigTempSnsr4CktPerf
      VeRCVR_e_HtrCoreBypVlv_Stuck_State: nonqueued-receiver-com-spec{data-element=Value, init-value=CeRCVR_e_Closed}, required-interface=VeRCVR_e_HtrCoreBypVlv_Stuck_State
    159 x provide port:
      VeTHMR_T_ECH_ClntTempTgt: nonqueued-sender-com-spec{data-element=Value, init-value=0}, provided-interface=VeTHMR_T_ECH_ClntTempTgt
      VeTHMR_P_ECH_HtrPwrTgt: nonqueued-sender-com-spec{data-element=Value, init-value=0}, provided-interface=VeTHMR_P_ECH_HtrPwrTgt
      VeTHMR_y_Htr_Oprtn_State: nonqueued-sender-com-spec{data-element=Value, init-value=0}, provided-interface=VeTHMR_y_Htr_Oprtn_State
      VeTHMR_b_CabReq_NotAllow: nonqueued-sender-com-spec{data-element=Value, init-value=0}, provided-interface=VeTHMR_b_CabReq_NotAllow
      VeTHMR_b_CabAllowed: nonqueued-sender-com-spec{data-element=Value, init-value=0}, provided-interface=VeTHMR_b_CabAllowed
      VeTHMR_dV_LT_ActvPmpFlow: nonqueued-sender-com-spec{data-element=Value, init-value=0}, provided-interface=VeTHMR_dV_LT_ActvPmpFlow
      VeTHMR_dV_LT_PsvPmpFlow: nonqueued-sender-com-spec{data-element=Value, init-value=0}, provided-interface=VeTHMR_dV_LT_PsvPmpFlow
      VeTHMR_dV_HT_AuxPmpFlow: nonqueued-sender-com-spec{data-element=Value, init-value=0}, provided-interface=VeTHMR_dV_HT_AuxPmpFlow
      VeTHMR_e_ClntPmpState: nonqueued-sender-com-spec{data-element=Value, init-value=CeTHMR_e_NoPump_On}, provided-interface=VeTHMR_e_ClntPmpState
      VeTHMR_b_LTPsvPmp_ClntWarmUp: nonqueued-sender-com-spec{data-element=Value, init-value=0}, provided-interface=VeTHMR_b_LTPsvPmp_ClntWarmUp
      VeTHMR_b_LTActvPmp_ClntWarmUp: nonqueued-sender-com-spec{data-element=Value, init-value=0}, provided-interface=VeTHMR_b_LTActvPmp_ClntWarmUp
      VeTHMR_b_HTAuxPmp_ClntWarmUp: nonqueued-sender-com-spec{data-element=Value, init-value=0}, provided-interface=VeTHMR_b_HTAuxPmp_ClntWarmUp
      VeTHMR_Pct_ClntProp3WyVlv_Cmd: nonqueued-sender-com-spec{data-element=Value, init-value=0}, provided-interface=VeTHMR_Pct_ClntProp3WyVlv_Cmd
      VeTHMR_e_ClntNProp3WyVlv_State: nonqueued-sender-com-spec{data-element=Value, init-value=CeTHMR_e_NoVlvPwrd}, provided-interface=VeTHMR_e_ClntNProp3WyVlv_State
      VeTHMR_e_ClntProp3WyVlv_State: nonqueued-sender-com-spec{data-element=Value, init-value=CeTHMR_e_NoVlvPwrd}, provided-interface=VeTHMR_e_ClntProp3WyVlv_State
      VeTHMR_b_HTCV_LearnEnb: nonqueued-sender-com-spec{data-element=Value, init-value=0}, provided-interface=VeTHMR_b_HTCV_LearnEnb
      VeTHMR_e_RefShtoffVlv_State: nonqueued-sender-com-spec{data-element=Value, init-value=CeTHMR_e_AllOpen}, provided-interface=VeTHMR_e_RefShtoffVlv_State
      VeTHMR_Pct_AirFlowReq: nonqueued-sender-com-spec{data-element=Value, init-value=0}, provided-interface=VeTHMR_Pct_AirFlowReq
      VeTHMR_e_RadFan_State: nonqueued-sender-com-spec{data-element=Value, init-value=CeFSCR_e_RadFan_OFF}, provided-interface=VeTHMR_e_RadFan_State
      VeTHMR_b_AGS_State: nonqueued-sender-com-spec{data-element=Value, init-value=0}, provided-interface=VeTHMR_b_AGS_State
      VeTHMR_e_EmrgcyFanRq_Lvl: nonqueued-sender-com-spec{data-element=Value, init-value=CeTHMR_e_No_EmrgcyFanRq}, provided-interface=VeTHMR_e_EmrgcyFanRq_Lvl
      VeTHMR_Pct_HCP_AGS_Req: nonqueued-sender-com-spec{data-element=Value, init-value=0}, provided-interface=VeTHMR_Pct_HCP_AGS_Req
      VeTHMR_dT_CellOverTemp: nonqueued-sender-com-spec{data-element=Value, init-value=0}, provided-interface=VeTHMR_dT_CellOverTemp
      VeTHMR_b_BattCondPlugin_Rq: nonqueued-sender-com-spec{data-element=Value, init-value=0}, provided-interface=VeTHMR_b_BattCondPlugin_Rq
      VeTHMR_b_RmtStrtAbort_StrtVhclRq: nonqueued-sender-com-spec{data-element=Value, init-value=0}, provided-interface=VeTHMR_b_RmtStrtAbort_StrtVhclRq
      VeTHMR_e_EngOrBattPwrDschg_State: nonqueued-sender-com-spec{data-element=Value, init-value=CePDTR_e_No_Dischrg}, provided-interface=VeTHMR_e_EngOrBattPwrDschg_State
      VeTHMR_P_PwrBdgt_PwrLimitAvail: nonqueued-sender-com-spec{data-element=Value, init-value=0}, provided-interface=VeTHMR_P_PwrBdgt_PwrLimitAvail
      VeTHMR_P_Rat_EAC_PwrBdgt_Avail: nonqueued-sender-com-spec{data-element=Value, init-value=0}, provided-interface=VeTHMR_P_Rat_EAC_PwrBdgt_Avail
      VeTHMR_b_BattAllowed: nonqueued-sender-com-spec{data-element=Value, init-value=0}, provided-interface=VeTHMR_b_BattAllowed
      VeTHMR_b_RdyForShtDwn: nonqueued-sender-com-spec{data-element=Value, init-value=0}, provided-interface=VeTHMR_b_RdyForShtDwn
      VeTHMR_e_ThrmSysShtDwnFlt: nonqueued-sender-com-spec{data-element=Value, init-value=CeSRAR_e_NoFlt}, provided-interface=VeTHMR_e_ThrmSysShtDwnFlt
      VeTHMR_b_HV_BatTempCrit_Cond: nonqueued-sender-com-spec{data-element=Value, init-value=0}, provided-interface=VeTHMR_b_HV_BatTempCrit_Cond
      VeTHMR_b_HVAC_HeatReq: nonqueued-sender-com-spec{data-element=Value, init-value=0}, provided-interface=VeTHMR_b_HVAC_HeatReq
      VeTHMR_b_ThermSystEng_Req: nonqueued-sender-com-spec{data-element=Value, init-value=0}, provided-interface=VeTHMR_b_ThermSystEng_Req
      VeTHMR_b_VhclStatus: nonqueued-sender-com-spec{data-element=Value, init-value=0}, provided-interface=VeTHMR_b_VhclStatus
      VeTHMR_t_BatPerWU_ThrmlCond_Timer: nonqueued-sender-com-spec{data-element=Value, init-value=0}, provided-interface=VeTHMR_t_BatPerWU_ThrmlCond_Timer
      VeTHMR_b_HVAC_turnedOff: nonqueued-sender-com-spec{data-element=Value, init-value=0}, provided-interface=VeTHMR_b_HVAC_turnedOff
      VeTHMR_b_StartVhcl_ToMaintain12Vlt: nonqueued-sender-com-spec{data-element=Value, init-value=0}, provided-interface=VeTHMR_b_StartVhcl_ToMaintain12Vlt
      VeTHMR_b_LeaveKeyIn_RUN: nonqueued-sender-com-spec{data-element=Value, init-value=0}, provided-interface=VeTHMR_b_LeaveKeyIn_RUN
      VeTHMR_e_HV_Bat_CltLvlLo: nonqueued-sender-com-spec{data-element=Value, init-value=CeBRDR_e_BatCltLvlNotLo}, provided-interface=VeTHMR_e_HV_Bat_CltLvlLo
      VeTHMR_e_BatThrmlSt: nonqueued-sender-com-spec{data-element=Value, init-value=CeTHMR_e_NoConditioning}, provided-interface=VeTHMR_e_BatThrmlSt
      VeTHMR_T_HtrCorClnt_TmpIn: nonqueued-sender-com-spec{data-element=Value, init-value=0}, provided-interface=VeTHMR_T_HtrCorClnt_TmpIn
      VeTHMR_b_isCharging: nonqueued-sender-com-spec{data-element=Value, init-value=0}, provided-interface=VeTHMR_b_isCharging
      VeTHMR_e_CabinPreCondReqStat: nonqueued-sender-com-spec{data-element=Value, init-value=0}, provided-interface=VeTHMR_e_CabinPreCondReqStat
      VeTHMR_e_AC_CompState: nonqueued-sender-com-spec{data-element=Value, init-value=CeTHMR_e_ACOff}, provided-interface=VeTHMR_e_AC_CompState
      VeTHMR_b_ActRemCompDecision: nonqueued-sender-com-spec{data-element=Value, init-value=0}, provided-interface=VeTHMR_b_ActRemCompDecision
      VeTHMR_e_Eng_Htr_HTSOV_Stat: nonqueued-sender-com-spec{data-element=Value, init-value=CeTHMR_e_NoStateSlctd}, provided-interface=VeTHMR_e_Eng_Htr_HTSOV_Stat
      VeTHMR_e_PPCTIS_OT: nonqueued-sender-com-spec{data-element=Value, init-value=CeTHMR_e_EmergencyLevel4}, provided-interface=VeTHMR_e_PPCTIS_OT
      VeTHMR_Pct_BSG_LTR_PmpFlwRq: nonqueued-sender-com-spec{data-element=Value, init-value=0}, provided-interface=VeTHMR_Pct_BSG_LTR_PmpFlwRq
      VeTHMR_dV_MGU_ClntPumpFlw: nonqueued-sender-com-spec{data-element=Value, init-value=0}, provided-interface=VeTHMR_dV_MGU_ClntPumpFlw
      VeTHMR_n_EngSpdInc_Req: nonqueued-sender-com-spec{data-element=Value, init-value=0}, provided-interface=VeTHMR_n_EngSpdInc_Req
      VeTHMR_dV_MtrA_CoolFlwCmd: nonqueued-sender-com-spec{data-element=Value, init-value=0}, provided-interface=VeTHMR_dV_MtrA_CoolFlwCmd
      VeTHMR_dV_MtrB_CoolFlwCmd: nonqueued-sender-com-spec{data-element=Value, init-value=0}, provided-interface=VeTHMR_dV_MtrB_CoolFlwCmd
      VeTHMR_b_HVBR_OvrdReq: nonqueued-sender-com-spec{data-element=Value, init-value=0}, provided-interface=VeTHMR_b_HVBR_OvrdReq
      VeTHMR_e_VehThermSt: nonqueued-sender-com-spec{data-element=Value, init-value=CeTHMR_e_TempAllowNormalDrive}, provided-interface=VeTHMR_e_VehThermSt
      VeTHMR_T_MinBattAllow: nonqueued-sender-com-spec{data-element=Value, init-value=0}, provided-interface=VeTHMR_T_MinBattAllow
      VeTHMR_T_MaxBattAllow: nonqueued-sender-com-spec{data-element=Value, init-value=0}, provided-interface=VeTHMR_T_MaxBattAllow
      VeTHMR_b_HtrCorClnt_Tmp_InFA: nonqueued-sender-com-spec{data-element=Value, init-value=0}, provided-interface=VeTHMR_b_HtrCorClnt_Tmp_InFA
      VeTHMR_b_HV_BatRdyLocal_True: nonqueued-sender-com-spec{data-element=Value, init-value=0}, provided-interface=VeTHMR_b_HV_BatRdyLocal_True
      VeTHMR_b_HVBR_UsgEnb: nonqueued-sender-com-spec{data-element=Value, init-value=0}, provided-interface=VeTHMR_b_HVBR_UsgEnb
      VeTHMR_b_RS_N_Or_NrmlPerWp: nonqueued-sender-com-spec{data-element=Value, init-value=0}, provided-interface=VeTHMR_b_RS_N_Or_NrmlPerWp
      VeTHMR_e_HTCL_Heat_Distrib: nonqueued-sender-com-spec{data-element=Value, init-value=CeTHMR_e_NoHeating}, provided-interface=VeTHMR_e_HTCL_Heat_Distrib
      VeTHMR_b_HCP_LTP_FanAftRun_Rq: nonqueued-sender-com-spec{data-element=Value, init-value=0}, provided-interface=VeTHMR_b_HCP_LTP_FanAftRun_Rq
      VeTHMR_e_HCP_LTP_FanAftRun_Rq: nonqueued-sender-com-spec{data-element=Value, init-value=CeTMIR_e_No_AftRunRequest}, provided-interface=VeTHMR_e_HCP_LTP_FanAftRun_Rq
      VeTHMR_dV_LT_PsvPmp2Flow: nonqueued-sender-com-spec{data-element=Value, init-value=0}, provided-interface=VeTHMR_dV_LT_PsvPmp2Flow
      VeTHMR_b_LTPsvPmp2_ClntWarmUp: nonqueued-sender-com-spec{data-element=Value, init-value=0}, provided-interface=VeTHMR_b_LTPsvPmp2_ClntWarmUp
      VeTHMR_b_BattOVFailure: nonqueued-sender-com-spec{data-element=Value, init-value=0}, provided-interface=VeTHMR_b_BattOVFailure
      VeTHMR_T_Htr2ClntTempTgt: nonqueued-sender-com-spec{data-element=Value, init-value=0}, provided-interface=VeTHMR_T_Htr2ClntTempTgt
      VeTHMR_P_Htr2PwrTgt: nonqueued-sender-com-spec{data-element=Value, init-value=0}, provided-interface=VeTHMR_P_Htr2PwrTgt
      VeTHMR_T_Htr3ClntTempTgt: nonqueued-sender-com-spec{data-element=Value, init-value=0}, provided-interface=VeTHMR_T_Htr3ClntTempTgt
      VeTHMR_P_Htr3PwrTgt: nonqueued-sender-com-spec{data-element=Value, init-value=0}, provided-interface=VeTHMR_P_Htr3PwrTgt
      VeTHMR_T_Htr4ClntTempTgt: nonqueued-sender-com-spec{data-element=Value, init-value=0}, provided-interface=VeTHMR_T_Htr4ClntTempTgt
      VeTHMR_P_Htr4PwrTgt: nonqueued-sender-com-spec{data-element=Value, init-value=0}, provided-interface=VeTHMR_P_Htr4PwrTgt
      VeTHMR_y_Htr_Slctn_State: nonqueued-sender-com-spec{data-element=Value, init-value=0}, provided-interface=VeTHMR_y_Htr_Slctn_State
      VeTHMR_b_AftrRunFanRqst: nonqueued-sender-com-spec{data-element=Value, init-value=0}, provided-interface=VeTHMR_b_AftrRunFanRqst
      VeTHMR_b_DisblFunc_Msg_10: nonqueued-sender-com-spec{data-element=Value, init-value=0}, provided-interface=VeTHMR_b_DisblFunc_Msg_10
      VeTHMR_y_ClntPump_Slctd_State: nonqueued-sender-com-spec{data-element=Value, init-value=0}, provided-interface=VeTHMR_y_ClntPump_Slctd_State
      VeTHMR_y_ClntPump_Oprtng_State: nonqueued-sender-com-spec{data-element=Value, init-value=0}, provided-interface=VeTHMR_y_ClntPump_Oprtng_State
      VeTHMR_dV_LTR_Flw_Tgt: nonqueued-sender-com-spec{data-element=Value, init-value=0}, provided-interface=VeTHMR_dV_LTR_Flw_Tgt
      VeTHMR_T_MaxBattAllowPsv: nonqueued-sender-com-spec{data-element=Value, init-value=0}, provided-interface=VeTHMR_T_MaxBattAllowPsv
      VeTHMR_Pct_LINPrpVlv_Cmd: nonqueued-sender-com-spec{data-element=Value, init-value=0}, provided-interface=VeTHMR_Pct_LINPrpVlv_Cmd
      VeTHMR_b_LINPrpVlv_CalibReq: nonqueued-sender-com-spec{data-element=Value, init-value=0}, provided-interface=VeTHMR_b_LINPrpVlv_CalibReq
      VeTHMR_e_HVAC_PerfModeFlg: nonqueued-sender-com-spec{data-element=Value, init-value=CeTHMR_e_NormalMode}, provided-interface=VeTHMR_e_HVAC_PerfModeFlg
      VeTHMR_b_ThermalHybAltMode_Rq: nonqueued-sender-com-spec{data-element=Value, init-value=0}, provided-interface=VeTHMR_b_ThermalHybAltMode_Rq
      VeTHMR_b_KeyXstnOFF: nonqueued-sender-com-spec{data-element=Value, init-value=0}, provided-interface=VeTHMR_b_KeyXstnOFF
      VeTHMR_t_SC_PrecTimer: nonqueued-sender-com-spec{data-element=Value, init-value=0}, provided-interface=VeTHMR_t_SC_PrecTimer
      VeTHMR_e_SC_WkUp: nonqueued-sender-com-spec{data-element=Value, init-value=CeTPCR_e_SC_NotAwake}, provided-interface=VeTHMR_e_SC_WkUp
      VeTHMR_e_CabPrecondReqSt: nonqueued-sender-com-spec{data-element=Value, init-value=CeTPCR_e_CabinPrec_Dflt}, provided-interface=VeTHMR_e_CabPrecondReqSt
      VeTHMR_b_LTAP_ExpctdOff: nonqueued-sender-com-spec{data-element=Value, init-value=0}, provided-interface=VeTHMR_b_LTAP_ExpctdOff
      VeTHMR_b_DrvDrAjar: nonqueued-sender-com-spec{data-element=Value, init-value=0}, provided-interface=VeTHMR_b_DrvDrAjar
      VeTHMR_b_CabPrecDny_BattCond: nonqueued-sender-com-spec{data-element=Value, init-value=0}, provided-interface=VeTHMR_b_CabPrecDny_BattCond
      VeTHMR_r_BattCabPriority_Ratio: nonqueued-sender-com-spec{data-element=Value, init-value=0}, provided-interface=VeTHMR_r_BattCabPriority_Ratio
      VeTHMR_b_LINPrpVlv_SvReq: nonqueued-sender-com-spec{data-element=Value, init-value=0}, provided-interface=VeTHMR_b_LINPrpVlv_SvReq
      VeTHMR_b_HTCV_RAEnbl_BattTmpHi: nonqueued-sender-com-spec{data-element=Value, init-value=0}, provided-interface=VeTHMR_b_HTCV_RAEnbl_BattTmpHi
      VeTHMR_e_CabinPreCondReqMsg: nonqueued-sender-com-spec{data-element=Value, init-value=0}, provided-interface=VeTHMR_e_CabinPreCondReqMsg
      VeTHMR_b_CabPrecond: nonqueued-sender-com-spec{data-element=Value, init-value=0}, provided-interface=VeTHMR_b_CabPrecond
      VeTHMR_b_PerWup: nonqueued-sender-com-spec{data-element=Value, init-value=0}, provided-interface=VeTHMR_b_PerWup
      VeTHMR_b_LatcdImpct: nonqueued-sender-com-spec{data-element=Value, init-value=0}, provided-interface=VeTHMR_b_LatcdImpct
      VeTHMR_b_SC_WkUpFlg: nonqueued-sender-com-spec{data-element=Value, init-value=0}, provided-interface=VeTHMR_b_SC_WkUpFlg
      VeTHMR_T_MinBattAllowPsv: nonqueued-sender-com-spec{data-element=Value, init-value=0}, provided-interface=VeTHMR_T_MinBattAllowPsv
      VeTHMR_b_PerWup_EngtoCond: nonqueued-sender-com-spec{data-element=Value, init-value=0}, provided-interface=VeTHMR_b_PerWup_EngtoCond
      VeTHMR_b_BattSharedHeaterAllowed: nonqueued-sender-com-spec{data-element=Value, init-value=0}, provided-interface=VeTHMR_b_BattSharedHeaterAllowed
      VeTHMR_P_PerWup_EngHeatNeed: nonqueued-sender-com-spec{data-element=Value, init-value=0}, provided-interface=VeTHMR_P_PerWup_EngHeatNeed
      VeTHMR_P_EDU_Heat_Cabin_Available: nonqueued-sender-com-spec{data-element=Value, init-value=0}, provided-interface=VeTHMR_P_EDU_Heat_Cabin_Available
      VeTHMR_P_EDU_Heat_Battery_Available: nonqueued-sender-com-spec{data-element=Value, init-value=0}, provided-interface=VeTHMR_P_EDU_Heat_Battery_Available
      VeTHMR_P_EnginePwr_Available: nonqueued-sender-com-spec{data-element=Value, init-value=0}, provided-interface=VeTHMR_P_EnginePwr_Available
      VeTHMR_e_CabThermalMode: nonqueued-sender-com-spec{data-element=Value, init-value=CeTHMR_e_Cab_NoConditioning}, provided-interface=VeTHMR_e_CabThermalMode
      VeTHMR_e_CabHeatThermalState: nonqueued-sender-com-spec{data-element=Value, init-value=CeTHMR_e_NoCabinHeating}, provided-interface=VeTHMR_e_CabHeatThermalState
      VeTHMR_e_CabCoolThermalState: nonqueued-sender-com-spec{data-element=Value, init-value=CeTHMR_e_NoCabinCooling}, provided-interface=VeTHMR_e_CabCoolThermalState
      VeTHMR_e_LTCLRadVlvState: nonqueued-sender-com-spec{data-element=Value, init-value=CeTHMR_e_Balancing_LTCLVlvSt}, provided-interface=VeTHMR_e_LTCLRadVlvState
      VeTHMR_e_LTCLThrmlMode: nonqueued-sender-com-spec{data-element=Value, init-value=CeTHMR_e_LTCLBalancing}, provided-interface=VeTHMR_e_LTCLThrmlMode
      VeTHMR_Pct_HTL_BypsVlv_Cmd: nonqueued-sender-com-spec{data-element=Value, init-value=0}, provided-interface=VeTHMR_Pct_HTL_BypsVlv_Cmd
      VeTHMR_Pct_LTL_Vlv_Cmd: nonqueued-sender-com-spec{data-element=Value, init-value=0}, provided-interface=VeTHMR_Pct_LTL_Vlv_Cmd
      VeTHMR_n_HTLPumpMBCReq: nonqueued-sender-com-spec{data-element=Value, init-value=0}, provided-interface=VeTHMR_n_HTLPumpMBCReq
      VeTHMR_n_LTLPECP1MBC: nonqueued-sender-com-spec{data-element=Value, init-value=0}, provided-interface=VeTHMR_n_LTLPECP1MBC
      VeTHMR_n_LTLPECP2MBC: nonqueued-sender-com-spec{data-element=Value, init-value=0}, provided-interface=VeTHMR_n_LTLPECP2MBC
      VeTHMR_y_PumpEnbl: nonqueued-sender-com-spec{data-element=Value, init-value=0}, provided-interface=VeTHMR_y_PumpEnbl
      VeTHMR_T_AHPInletTempArb: nonqueued-sender-com-spec{data-element=Value, init-value=0}, provided-interface=VeTHMR_T_AHPInletTempArb
      VeTHMR_T_PPCTIS_Arb: nonqueued-sender-com-spec{data-element=Value, init-value=0}, provided-interface=VeTHMR_T_PPCTIS_Arb
      VeTHMR_P_WCondCabHeat_Avail: nonqueued-sender-com-spec{data-element=Value, init-value=0}, provided-interface=VeTHMR_P_WCondCabHeat_Avail
      VeTHMR_e_EOP_A_EmrgCoolState: nonqueued-sender-com-spec{data-element=Value, init-value=CeTHMR_e_OilPumpEmrgCool_OFF}, provided-interface=VeTHMR_e_EOP_A_EmrgCoolState
      VeTHMR_e_EOP_B_EmrgCoolState: nonqueued-sender-com-spec{data-element=Value, init-value=CeTHMR_e_OilPumpEmrgCool_OFF}, provided-interface=VeTHMR_e_EOP_B_EmrgCoolState
      VeTHMR_r_HvHrnMtrAPowerLimit: nonqueued-sender-com-spec{data-element=Value, init-value=0}, provided-interface=VeTHMR_r_HvHrnMtrAPowerLimit
      VeTHMR_b_HvHrnMtrAPowerLimit: nonqueued-sender-com-spec{data-element=Value, init-value=0}, provided-interface=VeTHMR_b_HvHrnMtrAPowerLimit
      VeTHMR_r_HvHrnMtrBPowerLimit: nonqueued-sender-com-spec{data-element=Value, init-value=0}, provided-interface=VeTHMR_r_HvHrnMtrBPowerLimit
      VeTHMR_b_HvHrnMtrBPowerLimit: nonqueued-sender-com-spec{data-element=Value, init-value=0}, provided-interface=VeTHMR_b_HvHrnMtrBPowerLimit
      VeTHMR_r_HvHrnMtrCPowerLimit: nonqueued-sender-com-spec{data-element=Value, init-value=0}, provided-interface=VeTHMR_r_HvHrnMtrCPowerLimit
      VeTHMR_b_HvHrnMtrCPowerLimit: nonqueued-sender-com-spec{data-element=Value, init-value=0}, provided-interface=VeTHMR_b_HvHrnMtrCPowerLimit
      VeTHMR_b_DeiceActv: nonqueued-sender-com-spec{data-element=Value, init-value=0}, provided-interface=VeTHMR_b_DeiceActv
      VeTHMR_e_CabHeatThermalMode: nonqueued-sender-com-spec{data-element=Value, init-value=CeTHMR_e_NoActvHeat}, provided-interface=VeTHMR_e_CabHeatThermalMode
      VeTHMR_i_ModeIndex: nonqueued-sender-com-spec{data-element=Value, init-value=0}, provided-interface=VeTHMR_i_ModeIndex
      VeTHMR_n_BTLPumpMBCReq: nonqueued-sender-com-spec{data-element=Value, init-value=0}, provided-interface=VeTHMR_n_BTLPumpMBCReq
      VeTHMR_T_BattClntMinTgt: nonqueued-sender-com-spec{data-element=Value, init-value=0}, provided-interface=VeTHMR_T_BattClntMinTgt
      VeTHMR_Pct_AGS_PosReq: nonqueued-sender-com-spec{data-element=Value, init-value=0}, provided-interface=VeTHMR_Pct_AGS_PosReq
      VeTHMR_Pct_AGS2_PosReq: nonqueued-sender-com-spec{data-element=Value, init-value=0}, provided-interface=VeTHMR_Pct_AGS2_PosReq
      VeTHMR_b_FC_CondAllwd: nonqueued-sender-com-spec{data-element=Value, init-value=0}, provided-interface=VeTHMR_b_FC_CondAllwd
      VeTHMR_e_FCThrmlState: nonqueued-sender-com-spec{data-element=Value, init-value=CeTHMR_e_FCCondOff}, provided-interface=VeTHMR_e_FCThrmlState
      VeTHMR_P_CabHeatPwrNeed: nonqueued-sender-com-spec{data-element=Value, init-value=0}, provided-interface=VeTHMR_P_CabHeatPwrNeed
      VeTHMR_b_FCHeatAllwd: nonqueued-sender-com-spec{data-element=Value, init-value=0}, provided-interface=VeTHMR_b_FCHeatAllwd
      VeTHMR_dV_Branch_{1..3}_Flw: nonqueued-sender-com-spec{data-element=Value, init-value=0}, provided-interface=VeTHMR_dV_Branch_{1..3}_Flw
      VeTHMR_dV_FCL_ClntFlowTgt: variation-point={short-label=vpVeTHMR_dV_FCL_ClntFlowTgt, sw-syscond=1}, nonqueued-sender-com-spec{data-element=Value, init-value=0}, provided-interface=VeTHMR_dV_FCL_ClntFlowTgt
      VeTHMR_Pct_FC_Vlv_Cmd: variation-point={short-label=vpVeTHMR_Pct_FC_Vlv_Cmd, sw-syscond=1}, nonqueued-sender-com-spec{data-element=Value, init-value=0}, provided-interface=VeTHMR_Pct_FC_Vlv_Cmd
      VeTHMR_b_AAD_RetrctReq: nonqueued-sender-com-spec{data-element=Value, init-value=0}, provided-interface=VeTHMR_b_AAD_RetrctReq
      VeTHMR_b_REDMHeatEstm_SNAflag: nonqueued-sender-com-spec{data-element=Value, init-value=0}, provided-interface=VeTHMR_b_REDMHeatEstm_SNAflag
      VeTHMR_b_FEDMHeatEstm_SNAflag: nonqueued-sender-com-spec{data-element=Value, init-value=0}, provided-interface=VeTHMR_b_FEDMHeatEstm_SNAflag
      VeTHMR_T_LTCLTgt_BattActvPsvHeating: nonqueued-sender-com-spec{data-element=Value, init-value=0}, provided-interface=VeTHMR_T_LTCLTgt_BattActvPsvHeating
      VeTHMR_I_ChargeCurrentLim: nonqueued-sender-com-spec{data-element=Value, init-value=0}, provided-interface=VeTHMR_I_ChargeCurrentLim
      VeTHMR_Pct_HtrCoreBypssVlv: nonqueued-sender-com-spec{data-element=Value, init-value=0}, provided-interface=VeTHMR_Pct_HtrCoreBypssVlv
      VeTHMR_Pct_FCCP_Req: nonqueued-sender-com-spec{data-element=Value, init-value=0}, provided-interface=VeTHMR_Pct_FCCP_Req
      VeTHMR_Pct_FCHTRRadFanReq: nonqueued-sender-com-spec{data-element=Value, init-value=0}, provided-interface=VeTHMR_Pct_FCHTRRadFanReq
      VeTHMR_P_FCPSThrmlPwr_MaxAllwd: nonqueued-sender-com-spec{data-element=Value, init-value=0}, provided-interface=VeTHMR_P_FCPSThrmlPwr_MaxAllwd
      VeTHMR_Pct_LTRSolitaryAGS_PosReq: nonqueued-sender-com-spec{data-element=Value, init-value=0}, provided-interface=VeTHMR_Pct_LTRSolitaryAGS_PosReq
      VeTHMR_Pct_HTRSolitaryAGS_PosReq: nonqueued-sender-com-spec{data-element=Value, init-value=0}, provided-interface=VeTHMR_Pct_HTRSolitaryAGS_PosReq
      VeTHMR_Pct_BTRSolitaryAGS_PosReq: nonqueued-sender-com-spec{data-element=Value, init-value=0}, provided-interface=VeTHMR_Pct_BTRSolitaryAGS_PosReq
      VeTHMR_Pct_LTR_AirFlowReq: nonqueued-sender-com-spec{data-element=Value, init-value=0}, provided-interface=VeTHMR_Pct_LTR_AirFlowReq
      VeTHMR_Pct_HTR_AirFlowReq: nonqueued-sender-com-spec{data-element=Value, init-value=0}, provided-interface=VeTHMR_Pct_HTR_AirFlowReq
      VeTHMR_Pct_BTR_AirFlowReq: nonqueued-sender-com-spec{data-element=Value, init-value=0}, provided-interface=VeTHMR_Pct_BTR_AirFlowReq
    require port NeTMIR_e_HCP_LTP_FanAftRun_Rq_Rx: nv-require-com-spec{init-value=CeTMIR_e_No_AftRunRequest, variable=NeTMIR_e_HCP_LTP_FanAftRun_Rq}, required-interface=NeTMIR_e_HCP_LTP_FanAftRun_Rq
    require port NeTHMR_t_PumpRunTmr_Rx: nv-require-com-spec{init-value=0, variable=NeTHMR_t_PumpRunTmr}, required-interface=NeTHMR_t_PumpRunTmr
    require port NeTHMR_t_PumpStrtTimeT1_Rx: nv-require-com-spec{init-value=0, variable=NeTHMR_t_PumpStrtTimeT1}, required-interface=NeTHMR_t_PumpStrtTimeT1
    provide port NeTMIR_e_HCP_LTP_FanAftRun_Rq: nv-provide-com-spec{ram-block-init-value=CeTMIR_e_No_AftRunRequest, variable=NeTMIR_e_HCP_LTP_FanAftRun_Rq}, provided-interface=NeTMIR_e_HCP_LTP_FanAftRun_Rq
    provide port NeTHMR_t_PumpRunTmr: nv-provide-com-spec{ram-block-init-value=0, variable=NeTHMR_t_PumpRunTmr}, provided-interface=NeTHMR_t_PumpRunTmr
    provide port NeTHMR_t_PumpStrtTimeT1: nv-provide-com-spec{ram-block-init-value=0, variable=NeTHMR_t_PumpStrtTimeT1}, provided-interface=NeTHMR_t_PumpStrtTimeT1
    require port KeTHMR_e_TurtleMd_Dial: parameter-require-com-spec{init-value=CeDMDR_e_No_Turtle_Mode, parameter=KeTHMR_e_TurtleMd_Dial}, required-interface=KeTHMR_e_TurtleMd_Dial
    require port KeTHMR_b_TurtleMd_SelDial: parameter-require-com-spec{init-value=KeTHMR_b_TurtleMd_SelDial_KeTHMR_b_TurtleMd_SelDial:0, parameter=KeTHMR_b_TurtleMd_SelDial}, required-interface=KeTHMR_b_TurtleMd_SelDial
    behavior IB_THMR: data-type-mapping=msADTtoIDTMapping, handle-termination-and-restart=NO-SUPPORT, included-data-type-set=data-type=[TeTHMR_e_AfterRunSM_State, TeTHMR_e_HtrState, TeTHMR_e_PumpOpState]
      timing event Event_FastTEF: start-on-event=THMR_FastTEF, period=0.005
      timing event Event_MedTEH: start-on-event=THMR_MedTEH, period=0.1
      init event Event_THMR_ac_Init: start-on-event=THMR_ac_Init
      init event Event_PwrOn: start-on-event=THMR_PwrOn
      init event Event_PwrOff: start-on-event=THMR_PwrOff
      explicit-inter-runnable-variables:
        4 x data, all with category=VALUE, sw-calibration-access=READ-ONLY, init-value=0:
          OutAirTemp_Est_AftDial_write_IRV: type=Float
          PropSysActv_THMR_AftDial_write_IRV: type=Boolean
          OutAirTemp_EstV_AftDial_write_IRV: type=Boolean
          BattCntctrOpenPndg_AD_write_IRV: type=Boolean
      5 x runnable:
        THMR_ac_Init
          data-send-points:
            28 x access:
              OUT_VeTHMR_e_ClntPmpState_Value: accessed-variable=VeTHMR_e_ClntPmpState.Value
              OUT_VeTHMR_e_ClntNProp3WyVlv_State_Value: accessed-variable=VeTHMR_e_ClntNProp3WyVlv_State.Value
              OUT_VeTHMR_e_ClntProp3WyVlv_State_Value: accessed-variable=VeTHMR_e_ClntProp3WyVlv_State.Value
              OUT_VeTHMR_e_RefShtoffVlv_State_Value: accessed-variable=VeTHMR_e_RefShtoffVlv_State.Value
              OUT_VeTHMR_e_RadFan_State_Value: accessed-variable=VeTHMR_e_RadFan_State.Value
              OUT_VeTHMR_e_EmrgcyFanRq_Lvl_Value: accessed-variable=VeTHMR_e_EmrgcyFanRq_Lvl.Value
              OUT_VeTHMR_e_EngOrBattPwrDschg_State_Value: accessed-variable=VeTHMR_e_EngOrBattPwrDschg_State.Value
              OUT_VeTHMR_e_ThrmSysShtDwnFlt_Value: accessed-variable=VeTHMR_e_ThrmSysShtDwnFlt.Value
              OUT_VeTHMR_e_HV_Bat_CltLvlLo_Value: accessed-variable=VeTHMR_e_HV_Bat_CltLvlLo.Value
              OUT_VeTHMR_e_BatThrmlSt_Value: accessed-variable=VeTHMR_e_BatThrmlSt.Value
              OUT_VeTHMR_e_AC_CompState_Value: accessed-variable=VeTHMR_e_AC_CompState.Value
              OUT_VeTHMR_e_Eng_Htr_HTSOV_Stat_Value: accessed-variable=VeTHMR_e_Eng_Htr_HTSOV_Stat.Value
              OUT_VeTHMR_e_PPCTIS_OT_Value: accessed-variable=VeTHMR_e_PPCTIS_OT.Value
              OUT_VeTHMR_e_VehThermSt_Value: accessed-variable=VeTHMR_e_VehThermSt.Value
              OUT_VeTHMR_e_HTCL_Heat_Distrib_Value: accessed-variable=VeTHMR_e_HTCL_Heat_Distrib.Value
              OUT_VeTHMR_e_HCP_LTP_FanAftRun_Rq_Value: accessed-variable=VeTHMR_e_HCP_LTP_FanAftRun_Rq.Value
              OUT_VeTHMR_e_HVAC_PerfModeFlg_Value: accessed-variable=VeTHMR_e_HVAC_PerfModeFlg.Value
              OUT_VeTHMR_e_SC_WkUp_Value: accessed-variable=VeTHMR_e_SC_WkUp.Value
              OUT_VeTHMR_e_CabPrecondReqSt_Value: accessed-variable=VeTHMR_e_CabPrecondReqSt.Value
              OUT_VeTHMR_e_CabThermalMode_Value: accessed-variable=VeTHMR_e_CabThermalMode.Value
              OUT_VeTHMR_e_CabHeatThermalState_Value: accessed-variable=VeTHMR_e_CabHeatThermalState.Value
              OUT_VeTHMR_e_CabCoolThermalState_Value: accessed-variable=VeTHMR_e_CabCoolThermalState.Value
              OUT_VeTHMR_e_LTCLRadVlvState_Value: accessed-variable=VeTHMR_e_LTCLRadVlvState.Value
              OUT_VeTHMR_e_LTCLThrmlMode_Value: accessed-variable=VeTHMR_e_LTCLThrmlMode.Value
              OUT_VeTHMR_e_EOP_A_EmrgCoolState_Value: accessed-variable=VeTHMR_e_EOP_A_EmrgCoolState.Value
              OUT_VeTHMR_e_EOP_B_EmrgCoolState_Value: accessed-variable=VeTHMR_e_EOP_B_EmrgCoolState.Value
              OUT_VeTHMR_e_CabHeatThermalMode_Value: accessed-variable=VeTHMR_e_CabHeatThermalMode.Value
              OUT_VeTHMR_e_FCThrmlState_Value: accessed-variable=VeTHMR_e_FCThrmlState.Value
        THMR_PwrOn
          data-receive-point-by-arguments:
            access IN_NeTHMR_t_PumpRunTmr_Rx_NeTHMR_t_PumpRunTmr: accessed-variable=NeTHMR_t_PumpRunTmr_Rx.NeTHMR_t_PumpRunTmr
            access IN_NeTHMR_t_PumpStrtTimeT1_Rx_NeTHMR_t_PumpStrtTimeT1: accessed-variable=NeTHMR_t_PumpStrtTimeT1_Rx.NeTHMR_t_PumpStrtTimeT1
            access IN_NeTMIR_e_HCP_LTP_FanAftRun_Rq_Rx_NeTMIR_e_HCP_LTP_FanAftRun_Rq: accessed-variable=NeTMIR_e_HCP_LTP_FanAftRun_Rq_Rx.NeTMIR_e_HCP_LTP_FanAftRun_Rq
          data-send-points:
            159 x access:
              OUT_VeTHMR_e_HCP_LTP_FanAftRun_Rq_Value: accessed-variable=VeTHMR_e_HCP_LTP_FanAftRun_Rq.Value
              OUT_VeTHMR_dV_FCL_ClntFlowTgt_Value: accessed-variable=VeTHMR_dV_FCL_ClntFlowTgt.Value, variation-point={short-label=vpOUT_VeTHMR_dV_FCL_ClntFlowTgt_Value, sw-syscond=1}
              OUT_VeTHMR_Pct_FC_Vlv_Cmd_Value: accessed-variable=VeTHMR_Pct_FC_Vlv_Cmd.Value, variation-point={short-label=vpOUT_VeTHMR_Pct_FC_Vlv_Cmd_Value, sw-syscond=1}
              OUT_VeTHMR_T_ECH_ClntTempTgt_Value: accessed-variable=VeTHMR_T_ECH_ClntTempTgt.Value
              OUT_VeTHMR_P_ECH_HtrPwrTgt_Value: accessed-variable=VeTHMR_P_ECH_HtrPwrTgt.Value
              OUT_VeTHMR_y_Htr_Oprtn_State_Value: accessed-variable=VeTHMR_y_Htr_Oprtn_State.Value
              OUT_VeTHMR_b_CabReq_NotAllow_Value: accessed-variable=VeTHMR_b_CabReq_NotAllow.Value
              OUT_VeTHMR_b_CabAllowed_Value: accessed-variable=VeTHMR_b_CabAllowed.Value
              OUT_VeTHMR_dV_LT_ActvPmpFlow_Value: accessed-variable=VeTHMR_dV_LT_ActvPmpFlow.Value
              OUT_VeTHMR_dV_LT_PsvPmpFlow_Value: accessed-variable=VeTHMR_dV_LT_PsvPmpFlow.Value
              OUT_VeTHMR_dV_HT_AuxPmpFlow_Value: accessed-variable=VeTHMR_dV_HT_AuxPmpFlow.Value
              OUT_VeTHMR_e_ClntPmpState_Value: accessed-variable=VeTHMR_e_ClntPmpState.Value
              OUT_VeTHMR_b_LTPsvPmp_ClntWarmUp_Value: accessed-variable=VeTHMR_b_LTPsvPmp_ClntWarmUp.Value
              OUT_VeTHMR_b_LTActvPmp_ClntWarmUp_Value: accessed-variable=VeTHMR_b_LTActvPmp_ClntWarmUp.Value
              OUT_VeTHMR_b_HTAuxPmp_ClntWarmUp_Value: accessed-variable=VeTHMR_b_HTAuxPmp_ClntWarmUp.Value
              OUT_VeTHMR_Pct_ClntProp3WyVlv_Cmd_Value: accessed-variable=VeTHMR_Pct_ClntProp3WyVlv_Cmd.Value
              OUT_VeTHMR_e_ClntNProp3WyVlv_State_Value: accessed-variable=VeTHMR_e_ClntNProp3WyVlv_State.Value
              OUT_VeTHMR_e_ClntProp3WyVlv_State_Value: accessed-variable=VeTHMR_e_ClntProp3WyVlv_State.Value
              OUT_VeTHMR_b_HTCV_LearnEnb_Value: accessed-variable=VeTHMR_b_HTCV_LearnEnb.Value
              OUT_VeTHMR_e_RefShtoffVlv_State_Value: accessed-variable=VeTHMR_e_RefShtoffVlv_State.Value
              OUT_VeTHMR_Pct_AirFlowReq_Value: accessed-variable=VeTHMR_Pct_AirFlowReq.Value
              OUT_VeTHMR_e_RadFan_State_Value: accessed-variable=VeTHMR_e_RadFan_State.Value
              OUT_VeTHMR_b_AGS_State_Value: accessed-variable=VeTHMR_b_AGS_State.Value
              OUT_VeTHMR_e_EmrgcyFanRq_Lvl_Value: accessed-variable=VeTHMR_e_EmrgcyFanRq_Lvl.Value
              OUT_VeTHMR_Pct_HCP_AGS_Req_Value: accessed-variable=VeTHMR_Pct_HCP_AGS_Req.Value
              OUT_VeTHMR_dT_CellOverTemp_Value: accessed-variable=VeTHMR_dT_CellOverTemp.Value
              OUT_VeTHMR_b_BattCondPlugin_Rq_Value: accessed-variable=VeTHMR_b_BattCondPlugin_Rq.Value
              OUT_VeTHMR_b_RmtStrtAbort_StrtVhclRq_Value: accessed-variable=VeTHMR_b_RmtStrtAbort_StrtVhclRq.Value
              OUT_VeTHMR_e_EngOrBattPwrDschg_State_Value: accessed-variable=VeTHMR_e_EngOrBattPwrDschg_State.Value
              OUT_VeTHMR_P_PwrBdgt_PwrLimitAvail_Value: accessed-variable=VeTHMR_P_PwrBdgt_PwrLimitAvail.Value
              OUT_VeTHMR_P_Rat_EAC_PwrBdgt_Avail_Value: accessed-variable=VeTHMR_P_Rat_EAC_PwrBdgt_Avail.Value
              OUT_VeTHMR_b_BattAllowed_Value: accessed-variable=VeTHMR_b_BattAllowed.Value
              OUT_VeTHMR_b_RdyForShtDwn_Value: accessed-variable=VeTHMR_b_RdyForShtDwn.Value
              OUT_VeTHMR_e_ThrmSysShtDwnFlt_Value: accessed-variable=VeTHMR_e_ThrmSysShtDwnFlt.Value
              OUT_VeTHMR_b_HV_BatTempCrit_Cond_Value: accessed-variable=VeTHMR_b_HV_BatTempCrit_Cond.Value
              OUT_VeTHMR_b_HVAC_HeatReq_Value: accessed-variable=VeTHMR_b_HVAC_HeatReq.Value
              OUT_VeTHMR_b_ThermSystEng_Req_Value: accessed-variable=VeTHMR_b_ThermSystEng_Req.Value
              OUT_VeTHMR_b_VhclStatus_Value: accessed-variable=VeTHMR_b_VhclStatus.Value
              OUT_VeTHMR_t_BatPerWU_ThrmlCond_Timer_Value: accessed-variable=VeTHMR_t_BatPerWU_ThrmlCond_Timer.Value
              OUT_VeTHMR_b_HVAC_turnedOff_Value: accessed-variable=VeTHMR_b_HVAC_turnedOff.Value
              OUT_VeTHMR_b_StartVhcl_ToMaintain12Vlt_Value: accessed-variable=VeTHMR_b_StartVhcl_ToMaintain12Vlt.Value
              OUT_VeTHMR_b_LeaveKeyIn_RUN_Value: accessed-variable=VeTHMR_b_LeaveKeyIn_RUN.Value
              OUT_VeTHMR_e_HV_Bat_CltLvlLo_Value: accessed-variable=VeTHMR_e_HV_Bat_CltLvlLo.Value
              OUT_VeTHMR_e_BatThrmlSt_Value: accessed-variable=VeTHMR_e_BatThrmlSt.Value
              OUT_VeTHMR_T_HtrCorClnt_TmpIn_Value: accessed-variable=VeTHMR_T_HtrCorClnt_TmpIn.Value
              OUT_VeTHMR_b_isCharging_Value: accessed-variable=VeTHMR_b_isCharging.Value
              OUT_VeTHMR_e_CabinPreCondReqStat_Value: accessed-variable=VeTHMR_e_CabinPreCondReqStat.Value
              OUT_VeTHMR_e_AC_CompState_Value: accessed-variable=VeTHMR_e_AC_CompState.Value
              OUT_VeTHMR_b_ActRemCompDecision_Value: accessed-variable=VeTHMR_b_ActRemCompDecision.Value
              OUT_VeTHMR_e_Eng_Htr_HTSOV_Stat_Value: accessed-variable=VeTHMR_e_Eng_Htr_HTSOV_Stat.Value
              OUT_VeTHMR_e_PPCTIS_OT_Value: accessed-variable=VeTHMR_e_PPCTIS_OT.Value
              OUT_VeTHMR_Pct_BSG_LTR_PmpFlwRq_Value: accessed-variable=VeTHMR_Pct_BSG_LTR_PmpFlwRq.Value
              OUT_VeTHMR_dV_MGU_ClntPumpFlw_Value: accessed-variable=VeTHMR_dV_MGU_ClntPumpFlw.Value
              OUT_VeTHMR_n_EngSpdInc_Req_Value: accessed-variable=VeTHMR_n_EngSpdInc_Req.Value
              OUT_VeTHMR_dV_MtrA_CoolFlwCmd_Value: accessed-variable=VeTHMR_dV_MtrA_CoolFlwCmd.Value
              OUT_VeTHMR_dV_MtrB_CoolFlwCmd_Value: accessed-variable=VeTHMR_dV_MtrB_CoolFlwCmd.Value
              OUT_VeTHMR_b_HVBR_OvrdReq_Value: accessed-variable=VeTHMR_b_HVBR_OvrdReq.Value
              OUT_VeTHMR_e_VehThermSt_Value: accessed-variable=VeTHMR_e_VehThermSt.Value
              OUT_VeTHMR_T_MinBattAllow_Value: accessed-variable=VeTHMR_T_MinBattAllow.Value
              OUT_VeTHMR_T_MaxBattAllow_Value: accessed-variable=VeTHMR_T_MaxBattAllow.Value
              OUT_VeTHMR_b_HtrCorClnt_Tmp_InFA_Value: accessed-variable=VeTHMR_b_HtrCorClnt_Tmp_InFA.Value
              OUT_VeTHMR_b_HV_BatRdyLocal_True_Value: accessed-variable=VeTHMR_b_HV_BatRdyLocal_True.Value
              OUT_VeTHMR_b_HVBR_UsgEnb_Value: accessed-variable=VeTHMR_b_HVBR_UsgEnb.Value
              OUT_VeTHMR_b_RS_N_Or_NrmlPerWp_Value: accessed-variable=VeTHMR_b_RS_N_Or_NrmlPerWp.Value
              OUT_VeTHMR_e_HTCL_Heat_Distrib_Value: accessed-variable=VeTHMR_e_HTCL_Heat_Distrib.Value
              OUT_VeTHMR_b_HCP_LTP_FanAftRun_Rq_Value: accessed-variable=VeTHMR_b_HCP_LTP_FanAftRun_Rq.Value
              OUT_VeTHMR_dV_LT_PsvPmp2Flow_Value: accessed-variable=VeTHMR_dV_LT_PsvPmp2Flow.Value
              OUT_VeTHMR_b_LTPsvPmp2_ClntWarmUp_Value: accessed-variable=VeTHMR_b_LTPsvPmp2_ClntWarmUp.Value
              OUT_VeTHMR_b_BattOVFailure_Value: accessed-variable=VeTHMR_b_BattOVFailure.Value
              OUT_VeTHMR_T_Htr2ClntTempTgt_Value: accessed-variable=VeTHMR_T_Htr2ClntTempTgt.Value
              OUT_VeTHMR_P_Htr2PwrTgt_Value: accessed-variable=VeTHMR_P_Htr2PwrTgt.Value
              OUT_VeTHMR_T_Htr3ClntTempTgt_Value: accessed-variable=VeTHMR_T_Htr3ClntTempTgt.Value
              OUT_VeTHMR_P_Htr3PwrTgt_Value: accessed-variable=VeTHMR_P_Htr3PwrTgt.Value
              OUT_VeTHMR_T_Htr4ClntTempTgt_Value: accessed-variable=VeTHMR_T_Htr4ClntTempTgt.Value
              OUT_VeTHMR_P_Htr4PwrTgt_Value: accessed-variable=VeTHMR_P_Htr4PwrTgt.Value
              OUT_VeTHMR_y_Htr_Slctn_State_Value: accessed-variable=VeTHMR_y_Htr_Slctn_State.Value
              OUT_VeTHMR_b_AftrRunFanRqst_Value: accessed-variable=VeTHMR_b_AftrRunFanRqst.Value
              OUT_VeTHMR_b_DisblFunc_Msg_10_Value: accessed-variable=VeTHMR_b_DisblFunc_Msg_10.Value
              OUT_VeTHMR_y_ClntPump_Slctd_State_Value: accessed-variable=VeTHMR_y_ClntPump_Slctd_State.Value
              OUT_VeTHMR_y_ClntPump_Oprtng_State_Value: accessed-variable=VeTHMR_y_ClntPump_Oprtng_State.Value
              OUT_VeTHMR_dV_Branch_1_Flw_Value: accessed-variable=VeTHMR_dV_Branch_1_Flw.Value
              OUT_VeTHMR_dV_Branch_2_Flw_Value: accessed-variable=VeTHMR_dV_Branch_2_Flw.Value
              OUT_VeTHMR_dV_LTR_Flw_Tgt_Value: accessed-variable=VeTHMR_dV_LTR_Flw_Tgt.Value
              OUT_VeTHMR_T_MaxBattAllowPsv_Value: accessed-variable=VeTHMR_T_MaxBattAllowPsv.Value
              OUT_VeTHMR_Pct_LINPrpVlv_Cmd_Value: accessed-variable=VeTHMR_Pct_LINPrpVlv_Cmd.Value
              OUT_VeTHMR_b_LINPrpVlv_CalibReq_Value: accessed-variable=VeTHMR_b_LINPrpVlv_CalibReq.Value
              OUT_VeTHMR_e_HVAC_PerfModeFlg_Value: accessed-variable=VeTHMR_e_HVAC_PerfModeFlg.Value
              OUT_VeTHMR_b_ThermalHybAltMode_Rq_Value: accessed-variable=VeTHMR_b_ThermalHybAltMode_Rq.Value
              OUT_VeTHMR_b_KeyXstnOFF_Value: accessed-variable=VeTHMR_b_KeyXstnOFF.Value
              OUT_VeTHMR_t_SC_PrecTimer_Value: accessed-variable=VeTHMR_t_SC_PrecTimer.Value
              OUT_VeTHMR_e_SC_WkUp_Value: accessed-variable=VeTHMR_e_SC_WkUp.Value
              OUT_VeTHMR_e_CabPrecondReqSt_Value: accessed-variable=VeTHMR_e_CabPrecondReqSt.Value
              OUT_VeTHMR_b_LTAP_ExpctdOff_Value: accessed-variable=VeTHMR_b_LTAP_ExpctdOff.Value
              OUT_VeTHMR_b_DrvDrAjar_Value: accessed-variable=VeTHMR_b_DrvDrAjar.Value
              OUT_VeTHMR_b_CabPrecDny_BattCond_Value: accessed-variable=VeTHMR_b_CabPrecDny_BattCond.Value
              OUT_VeTHMR_r_BattCabPriority_Ratio_Value: accessed-variable=VeTHMR_r_BattCabPriority_Ratio.Value
              OUT_VeTHMR_b_LINPrpVlv_SvReq_Value: accessed-variable=VeTHMR_b_LINPrpVlv_SvReq.Value
              OUT_VeTHMR_b_HTCV_RAEnbl_BattTmpHi_Value: accessed-variable=VeTHMR_b_HTCV_RAEnbl_BattTmpHi.Value
              OUT_VeTHMR_e_CabinPreCondReqMsg_Value: accessed-variable=VeTHMR_e_CabinPreCondReqMsg.Value
              OUT_VeTHMR_b_CabPrecond_Value: accessed-variable=VeTHMR_b_CabPrecond.Value
              OUT_VeTHMR_b_PerWup_Value: accessed-variable=VeTHMR_b_PerWup.Value
              OUT_VeTHMR_b_LatcdImpct_Value: accessed-variable=VeTHMR_b_LatcdImpct.Value
              OUT_VeTHMR_b_SC_WkUpFlg_Value: accessed-variable=VeTHMR_b_SC_WkUpFlg.Value
              OUT_VeTHMR_T_MinBattAllowPsv_Value: accessed-variable=VeTHMR_T_MinBattAllowPsv.Value
              OUT_VeTHMR_b_PerWup_EngtoCond_Value: accessed-variable=VeTHMR_b_PerWup_EngtoCond.Value
              OUT_VeTHMR_b_BattSharedHeaterAllowed_Value: accessed-variable=VeTHMR_b_BattSharedHeaterAllowed.Value
              OUT_VeTHMR_P_PerWup_EngHeatNeed_Value: accessed-variable=VeTHMR_P_PerWup_EngHeatNeed.Value
              OUT_VeTHMR_P_EDU_Heat_Cabin_Available_Value: accessed-variable=VeTHMR_P_EDU_Heat_Cabin_Available.Value
              OUT_VeTHMR_P_EDU_Heat_Battery_Available_Value: accessed-variable=VeTHMR_P_EDU_Heat_Battery_Available.Value
              OUT_VeTHMR_P_EnginePwr_Available_Value: accessed-variable=VeTHMR_P_EnginePwr_Available.Value
              OUT_VeTHMR_e_CabThermalMode_Value: accessed-variable=VeTHMR_e_CabThermalMode.Value
              OUT_VeTHMR_e_CabHeatThermalState_Value: accessed-variable=VeTHMR_e_CabHeatThermalState.Value
              OUT_VeTHMR_e_CabCoolThermalState_Value: accessed-variable=VeTHMR_e_CabCoolThermalState.Value
              OUT_VeTHMR_e_LTCLRadVlvState_Value: accessed-variable=VeTHMR_e_LTCLRadVlvState.Value
              OUT_VeTHMR_e_LTCLThrmlMode_Value: accessed-variable=VeTHMR_e_LTCLThrmlMode.Value
              OUT_VeTHMR_Pct_HTL_BypsVlv_Cmd_Value: accessed-variable=VeTHMR_Pct_HTL_BypsVlv_Cmd.Value
              OUT_VeTHMR_Pct_LTL_Vlv_Cmd_Value: accessed-variable=VeTHMR_Pct_LTL_Vlv_Cmd.Value
              OUT_VeTHMR_n_HTLPumpMBCReq_Value: accessed-variable=VeTHMR_n_HTLPumpMBCReq.Value
              OUT_VeTHMR_n_LTLPECP1MBC_Value: accessed-variable=VeTHMR_n_LTLPECP1MBC.Value
              OUT_VeTHMR_n_LTLPECP2MBC_Value: accessed-variable=VeTHMR_n_LTLPECP2MBC.Value
              OUT_VeTHMR_y_PumpEnbl_Value: accessed-variable=VeTHMR_y_PumpEnbl.Value
              OUT_VeTHMR_T_AHPInletTempArb_Value: accessed-variable=VeTHMR_T_AHPInletTempArb.Value
              OUT_VeTHMR_T_PPCTIS_Arb_Value: accessed-variable=VeTHMR_T_PPCTIS_Arb.Value
              OUT_VeTHMR_P_WCondCabHeat_Avail_Value: accessed-variable=VeTHMR_P_WCondCabHeat_Avail.Value
              OUT_VeTHMR_dV_Branch_3_Flw_Value: accessed-variable=VeTHMR_dV_Branch_3_Flw.Value
              OUT_VeTHMR_e_EOP_A_EmrgCoolState_Value: accessed-variable=VeTHMR_e_EOP_A_EmrgCoolState.Value
              OUT_VeTHMR_e_EOP_B_EmrgCoolState_Value: accessed-variable=VeTHMR_e_EOP_B_EmrgCoolState.Value
              OUT_VeTHMR_r_HvHrnMtrAPowerLimit_Value: accessed-variable=VeTHMR_r_HvHrnMtrAPowerLimit.Value
              OUT_VeTHMR_b_HvHrnMtrAPowerLimit_Value: accessed-variable=VeTHMR_b_HvHrnMtrAPowerLimit.Value
              OUT_VeTHMR_r_HvHrnMtrBPowerLimit_Value: accessed-variable=VeTHMR_r_HvHrnMtrBPowerLimit.Value
              OUT_VeTHMR_b_HvHrnMtrBPowerLimit_Value: accessed-variable=VeTHMR_b_HvHrnMtrBPowerLimit.Value
              OUT_VeTHMR_r_HvHrnMtrCPowerLimit_Value: accessed-variable=VeTHMR_r_HvHrnMtrCPowerLimit.Value
              OUT_VeTHMR_b_HvHrnMtrCPowerLimit_Value: accessed-variable=VeTHMR_b_HvHrnMtrCPowerLimit.Value
              OUT_VeTHMR_b_DeiceActv_Value: accessed-variable=VeTHMR_b_DeiceActv.Value
              OUT_VeTHMR_e_CabHeatThermalMode_Value: accessed-variable=VeTHMR_e_CabHeatThermalMode.Value
              OUT_VeTHMR_i_ModeIndex_Value: accessed-variable=VeTHMR_i_ModeIndex.Value
              OUT_VeTHMR_n_BTLPumpMBCReq_Value: accessed-variable=VeTHMR_n_BTLPumpMBCReq.Value
              OUT_VeTHMR_T_BattClntMinTgt_Value: accessed-variable=VeTHMR_T_BattClntMinTgt.Value
              OUT_VeTHMR_Pct_AGS_PosReq_Value: accessed-variable=VeTHMR_Pct_AGS_PosReq.Value
              OUT_VeTHMR_Pct_AGS2_PosReq_Value: accessed-variable=VeTHMR_Pct_AGS2_PosReq.Value
              OUT_VeTHMR_b_FC_CondAllwd_Value: accessed-variable=VeTHMR_b_FC_CondAllwd.Value
              OUT_VeTHMR_e_FCThrmlState_Value: accessed-variable=VeTHMR_e_FCThrmlState.Value
              OUT_VeTHMR_P_CabHeatPwrNeed_Value: accessed-variable=VeTHMR_P_CabHeatPwrNeed.Value
              OUT_VeTHMR_b_FCHeatAllwd_Value: accessed-variable=VeTHMR_b_FCHeatAllwd.Value
              OUT_VeTHMR_b_AAD_RetrctReq_Value: accessed-variable=VeTHMR_b_AAD_RetrctReq.Value
              OUT_VeTHMR_b_REDMHeatEstm_SNAflag_Value: accessed-variable=VeTHMR_b_REDMHeatEstm_SNAflag.Value
              OUT_VeTHMR_b_FEDMHeatEstm_SNAflag_Value: accessed-variable=VeTHMR_b_FEDMHeatEstm_SNAflag.Value
              OUT_VeTHMR_T_LTCLTgt_BattActvPsvHeating_Value: accessed-variable=VeTHMR_T_LTCLTgt_BattActvPsvHeating.Value
              OUT_VeTHMR_I_ChargeCurrentLim_Value: accessed-variable=VeTHMR_I_ChargeCurrentLim.Value
              OUT_VeTHMR_Pct_HtrCoreBypssVlv_Value: accessed-variable=VeTHMR_Pct_HtrCoreBypssVlv.Value
              OUT_VeTHMR_Pct_FCCP_Req_Value: accessed-variable=VeTHMR_Pct_FCCP_Req.Value
              OUT_VeTHMR_Pct_FCHTRRadFanReq_Value: accessed-variable=VeTHMR_Pct_FCHTRRadFanReq.Value
              OUT_VeTHMR_P_FCPSThrmlPwr_MaxAllwd_Value: accessed-variable=VeTHMR_P_FCPSThrmlPwr_MaxAllwd.Value
              OUT_VeTHMR_Pct_LTRSolitaryAGS_PosReq_Value: accessed-variable=VeTHMR_Pct_LTRSolitaryAGS_PosReq.Value
              OUT_VeTHMR_Pct_HTRSolitaryAGS_PosReq_Value: accessed-variable=VeTHMR_Pct_HTRSolitaryAGS_PosReq.Value
              OUT_VeTHMR_Pct_BTRSolitaryAGS_PosReq_Value: accessed-variable=VeTHMR_Pct_BTRSolitaryAGS_PosReq.Value
              OUT_VeTHMR_Pct_LTR_AirFlowReq_Value: accessed-variable=VeTHMR_Pct_LTR_AirFlowReq.Value
              OUT_VeTHMR_Pct_HTR_AirFlowReq_Value: accessed-variable=VeTHMR_Pct_HTR_AirFlowReq.Value
              OUT_VeTHMR_Pct_BTR_AirFlowReq_Value: accessed-variable=VeTHMR_Pct_BTR_AirFlowReq.Value
          written-local-variables:
            4 x access:
              WV_BattCntctrOpenPndg_AD_write_IRV: accessed-variable=BattCntctrOpenPndg_AD_write_IRV
              WV_OutAirTemp_EstV_AftDial_write_IRV: accessed-variable=OutAirTemp_EstV_AftDial_write_IRV
              WV_OutAirTemp_Est_AftDial_write_IRV: accessed-variable=OutAirTemp_Est_AftDial_write_IRV
              WV_PropSysActv_THMR_AftDial_write_IRV: accessed-variable=PropSysActv_THMR_AftDial_write_IRV
        THMR_FastTEF
          data-receive-point-by-arguments:
            5 x access:
              IN_VeAATR_T_EstAmbAirTemp_Value: accessed-variable=VeAATR_T_EstAmbAirTemp.Value
              IN_VeAATR_b_EstAmbAirTempFA_Value: accessed-variable=VeAATR_b_EstAmbAirTempFA.Value
              IN_VeBTRR_b_HVBR_OvrdReq_Value: accessed-variable=VeBTRR_b_HVBR_OvrdReq.Value, variation-point={short-label=vpIN_VeBTRR_b_HVBR_OvrdReq_Value, sw-syscond=1}
              IN_VeHPMR_b_BattCntctrOpenPndg_Value: accessed-variable=VeHPMR_b_BattCntctrOpenPndg.Value
              IN_VeHPMR_b_PropSysActv_Value: accessed-variable=VeHPMR_b_PropSysActv.Value
          data-send-points:
            access OUT_VeTHMR_b_HVBR_OvrdReq_Value: accessed-variable=VeTHMR_b_HVBR_OvrdReq.Value
          written-local-variables:
            4 x access:
              WV_BattCntctrOpenPndg_AD_write_IRV: accessed-variable=BattCntctrOpenPndg_AD_write_IRV
              WV_OutAirTemp_EstV_AftDial_write_IRV: accessed-variable=OutAirTemp_EstV_AftDial_write_IRV
              WV_OutAirTemp_Est_AftDial_write_IRV: accessed-variable=OutAirTemp_Est_AftDial_write_IRV
              WV_PropSysActv_THMR_AftDial_write_IRV: accessed-variable=PropSysActv_THMR_AftDial_write_IRV
        THMR_MedTEH
          data-receive-point-by-arguments:
            396 x access:
              IN_VeACCR_b_OilMigOpnVlv_Value: accessed-variable=VeACCR_b_OilMigOpnVlv.Value
              IN_VeACCR_b_OverTempImminent_Value: accessed-variable=VeACCR_b_OverTempImminent.Value
              IN_VeACCR_b_eAC4CabInhibtd_Value: accessed-variable=VeACCR_b_eAC4CabInhibtd.Value
              IN_VeAVTR_b_SDS_CoolingReq_Value: accessed-variable=VeAVTR_b_SDS_CoolingReq.Value
              IN_VeAVTR_e_EVA_ThrmlState_Value: accessed-variable=VeAVTR_e_EVA_ThrmlState.Value
              IN_VeBPCR_Pct_HV_BatPackSOC_Arb_Value: accessed-variable=VeBPCR_Pct_HV_BatPackSOC_Arb.Value
              IN_VeBPCR_U_HV_BatVolt_Value: accessed-variable=VeBPCR_U_HV_BatVolt.Value
              IN_VeBPCR_b_BPCM_LIN_BusOff_FA_Value: accessed-variable=VeBPCR_b_BPCM_LIN_BusOff_FA.Value
              IN_VeBPCR_b_BPCM_LIN_BusOff_SgnlRcvd_Value: accessed-variable=VeBPCR_b_BPCM_LIN_BusOff_SgnlRcvd.Value
              IN_VeBPCR_b_BPCM_LOC_BCP_FA_Value: accessed-variable=VeBPCR_b_BPCM_LOC_BCP_FA.Value
              IN_VeBPCR_b_BPCM_LOC_BCP_SgnlRcvd_Value: accessed-variable=VeBPCR_b_BPCM_LOC_BCP_SgnlRcvd.Value
              IN_VeBPCR_b_HVBatRdy_Value: accessed-variable=VeBPCR_b_HVBatRdy.Value
              IN_VeBPCR_e_BPCM_LIN_BusOff_Value: accessed-variable=VeBPCR_e_BPCM_LIN_BusOff.Value
              IN_VeBPCR_e_BPCM_LOC_BCP_Value: accessed-variable=VeBPCR_e_BPCM_LOC_BCP.Value
              IN_VeBPCR_e_HV_BatCntctrStat_Value: accessed-variable=VeBPCR_e_HV_BatCntctrStat.Value
              IN_VeBRDR_e_HV_Bat_CltLvlLo_Value: accessed-variable=VeBRDR_e_HV_Bat_CltLvlLo.Value
              IN_VeBRKR_e_AHH_Ready_Status_Value: accessed-variable=VeBRKR_e_AHH_Ready_Status.Value
              IN_VeBTRR_P_BatHeatPwr_NeedLimtd_Value: accessed-variable=VeBTRR_P_BatHeatPwr_NeedLimtd.Value
              IN_VeBTRR_T_BTISBTIS2_Max_Value: accessed-variable=VeBTRR_T_BTISBTIS2_Max.Value
              IN_VeBTRR_T_CellTempMaxUsed_Value: accessed-variable=VeBTRR_T_CellTempMaxUsed.Value
              IN_VeBTRR_T_CellTempMinUsed_Value: accessed-variable=VeBTRR_T_CellTempMinUsed.Value
              IN_VeBTRR_b_BattCellBalancing_Value: accessed-variable=VeBTRR_b_BattCellBalancing.Value
              IN_VeBTRR_b_BattCondPlugin_Rq_Value: accessed-variable=VeBTRR_b_BattCondPlugin_Rq.Value, variation-point={short-label=vpIN_VeBTRR_b_BattCondPlugin_Rq_Value, sw-syscond=1}
              IN_VeBTRR_b_BattCoolFlts_Value: accessed-variable=VeBTRR_b_BattCoolFlts.Value, variation-point={short-label=vpIN_VeBTRR_b_BattCoolFlts_Value, sw-syscond=1}
              IN_VeBTRR_b_BattCoolReq_Value: accessed-variable=VeBTRR_b_BattCoolReq.Value
              IN_VeBTRR_b_BattCoolReq_CPV_RA_Value: accessed-variable=VeBTRR_b_BattCoolReq_CPV_RA.Value
              IN_VeBTRR_b_BattHeatReq_Value: accessed-variable=VeBTRR_b_BattHeatReq.Value
              IN_VeBTRR_b_Batt_CritOrMarg_Value: accessed-variable=VeBTRR_b_Batt_CritOrMarg.Value
              IN_VeBTRR_b_Batt_PsvCoolReq_Value: accessed-variable=VeBTRR_b_Batt_PsvCoolReq.Value
              IN_VeBTRR_b_HVBattPriority_Value: accessed-variable=VeBTRR_b_HVBattPriority.Value, variation-point={short-label=vpIN_VeBTRR_b_HVBattPriority_Value, sw-syscond=1}
              IN_VeBTRR_b_HV_BatTempCrit_Cond_Value: accessed-variable=VeBTRR_b_HV_BatTempCrit_Cond.Value
              IN_VeBTRR_b_KeyRun_OV_BattCrit_Value: accessed-variable=VeBTRR_b_KeyRun_OV_BattCrit.Value
              IN_VeBTRR_b_PerWup_BatToCond_Value: accessed-variable=VeBTRR_b_PerWup_BatToCond.Value
              IN_VeBTRR_b_PlugdIn_Or_Chrg_Value: accessed-variable=VeBTRR_b_PlugdIn_Or_Chrg.Value
              IN_VeBTRR_b_Psv_BattHeatReq_Value: accessed-variable=VeBTRR_b_Psv_BattHeatReq.Value
              IN_VeBTRR_b_ThrmlBatCoolingFlt_Value: accessed-variable=VeBTRR_b_ThrmlBatCoolingFlt.Value
              IN_VeBTRR_b_VhclPlgdIn_Value: accessed-variable=VeBTRR_b_VhclPlgdIn.Value
              IN_VeBTRR_b_isCharging_Value: accessed-variable=VeBTRR_b_isCharging.Value
              IN_VeBTRR_dT_CellOverTemp_Value: accessed-variable=VeBTRR_dT_CellOverTemp.Value
              IN_VeBTRR_dT_CellTempDelta_Value: accessed-variable=VeBTRR_dT_CellTempDelta.Value
              IN_VeBTRR_dT_CellUnderTemp_Value: accessed-variable=VeBTRR_dT_CellUnderTemp.Value
              IN_VeBTRR_dV_LT_ActPmpFlw_Value: accessed-variable=VeBTRR_dV_LT_ActPmpFlw.Value
              IN_VeBTRR_e_HV_BatTempCrit_CondState_New_Value: accessed-variable=VeBTRR_e_HV_BatTempCrit_CondState_New.Value
              IN_VeCITR_e_FOTA_Install_Type_Value: accessed-variable=VeCITR_e_FOTA_Install_Type.Value
              IN_VeCPDR_b_HTAP_FunPer_FltDtct_Value: accessed-variable=VeCPDR_b_HTAP_FunPer_FltDtct.Value
              IN_VeCPDR_b_LTAP_FunPer_FltDtct_Value: accessed-variable=VeCPDR_b_LTAP_FunPer_FltDtct.Value
              IN_VeCSVR_b_WhlSpdLHF_FA_Value: accessed-variable=VeCSVR_b_WhlSpdLHF_FA.Value, variation-point={short-label=vpIN_VeCSVR_b_WhlSpdLHF_FA_Value, sw-syscond=1}
              IN_VeCSVR_b_WhlSpdLHR_FA_Value: accessed-variable=VeCSVR_b_WhlSpdLHR_FA.Value, variation-point={short-label=vpIN_VeCSVR_b_WhlSpdLHR_FA_Value, sw-syscond=1}
              IN_VeCSVR_b_WhlSpdRHF_FA_Value: accessed-variable=VeCSVR_b_WhlSpdRHF_FA.Value, variation-point={short-label=vpIN_VeCSVR_b_WhlSpdRHF_FA_Value, sw-syscond=1}
              IN_VeCSVR_b_WhlSpdRHR_FA_Value: accessed-variable=VeCSVR_b_WhlSpdRHR_FA.Value, variation-point={short-label=vpIN_VeCSVR_b_WhlSpdRHR_FA_Value, sw-syscond=1}
              IN_VeCSVR_n_WhlSpdLHF_Value: accessed-variable=VeCSVR_n_WhlSpdLHF.Value, variation-point={short-label=vpIN_VeCSVR_n_WhlSpdLHF_Value, sw-syscond=1}
              IN_VeCSVR_n_WhlSpdLHR_Value: accessed-variable=VeCSVR_n_WhlSpdLHR.Value, variation-point={short-label=vpIN_VeCSVR_n_WhlSpdLHR_Value, sw-syscond=1}
              IN_VeCSVR_n_WhlSpdRHF_Value: accessed-variable=VeCSVR_n_WhlSpdRHF.Value, variation-point={short-label=vpIN_VeCSVR_n_WhlSpdRHF_Value, sw-syscond=1}
              IN_VeCSVR_n_WhlSpdRHR_Value: accessed-variable=VeCSVR_n_WhlSpdRHR.Value, variation-point={short-label=vpIN_VeCSVR_n_WhlSpdRHR_Value, sw-syscond=1}
              IN_VeCSVR_v_VehSpd_Value: accessed-variable=VeCSVR_v_VehSpd.Value
              IN_VeCTRR_P_ErrBasedHeatPwr_Value: accessed-variable=VeCTRR_P_ErrBasedHeatPwr.Value
              IN_VeCTRR_P_RearHeaterPwrReq_Value: accessed-variable=VeCTRR_P_RearHeaterPwrReq.Value
              IN_VeCTRR_T_HtrCoreTmp_Tgt_Arb_Value: accessed-variable=VeCTRR_T_HtrCoreTmp_Tgt_Arb.Value
              IN_VeCTRR_b_AmbientChillCond_Value: accessed-variable=VeCTRR_b_AmbientChillCond.Value
              IN_VeCTRR_b_CabPriorityHigh_Value: accessed-variable=VeCTRR_b_CabPriorityHigh.Value
              IN_VeCTRR_b_HVAC_HeatReq_Value: accessed-variable=VeCTRR_b_HVAC_HeatReq.Value
              IN_VeCTRR_b_HardCabHeat_Req_Value: accessed-variable=VeCTRR_b_HardCabHeat_Req.Value
              IN_VeCTRR_b_MinFlowCabHeatReq_Value: accessed-variable=VeCTRR_b_MinFlowCabHeatReq.Value
              IN_VeCTRR_b_RearHeaterReq_Value: accessed-variable=VeCTRR_b_RearHeaterReq.Value
              IN_VeCTRR_b_TrueCab_HeatReq_Value: accessed-variable=VeCTRR_b_TrueCab_HeatReq.Value
              IN_VeCTRR_b_TurnOffEng_CabComfAchvd_Value: accessed-variable=VeCTRR_b_TurnOffEng_CabComfAchvd.Value
              IN_VeCTRR_dT_HtrCorTmp_Err_Value: accessed-variable=VeCTRR_dT_HtrCorTmp_Err.Value
              IN_VeDFIR_b_Flashing_InProgress_Value: accessed-variable=VeDFIR_b_Flashing_InProgress.Value
              IN_VeDMAB_y_StatusByte_AC_RefrigPresSnsrAHi_Value: accessed-variable=VeDMAB_y_StatusByte_AC_RefrigPresSnsrAHi.Value
              IN_VeDMAB_y_StatusByte_AC_RefrigPresSnsrALo_Value: accessed-variable=VeDMAB_y_StatusByte_AC_RefrigPresSnsrALo.Value
              IN_VeDMAB_y_StatusByte_AC_RefrigPresSnsrAPerf_Value: accessed-variable=VeDMAB_y_StatusByte_AC_RefrigPresSnsrAPerf.Value
              IN_VeDMAB_y_StatusByte_AC_RefrigPresSnsrDCkt_Value: accessed-variable=VeDMAB_y_StatusByte_AC_RefrigPresSnsrDCkt.Value
              IN_VeDMAB_y_StatusByte_AC_RefrigPresSnsrDCktPerf_Value: accessed-variable=VeDMAB_y_StatusByte_AC_RefrigPresSnsrDCktPerf.Value
              IN_VeDMAB_y_StatusByte_AC_RefrigTempSnsr4CktPerf_Value: accessed-variable=VeDMAB_y_StatusByte_AC_RefrigTempSnsr4CktPerf.Value
              IN_VeDMAB_y_StatusByte_AC_RefrigTempSnsr5CktPerf_Value: accessed-variable=VeDMAB_y_StatusByte_AC_RefrigTempSnsr5CktPerf.Value
              IN_VeDMAB_y_StatusByte_AC_RefrigTempSnsr5CktShotoBat_Value: accessed-variable=VeDMAB_y_StatusByte_AC_RefrigTempSnsr5CktShotoBat.Value
              IN_VeDMAB_y_StatusByte_AC_RefrigTempSnsr5CktShotoGro_Value: accessed-variable=VeDMAB_y_StatusByte_AC_RefrigTempSnsr5CktShotoGro.Value
              IN_VeDMAB_y_StatusByte_AC_RefrigTempSnsrDCkt_Value: accessed-variable=VeDMAB_y_StatusByte_AC_RefrigTempSnsrDCkt.Value
              IN_VeDMAB_y_StatusByte_AGS_A_Perf_Value: accessed-variable=VeDMAB_y_StatusByte_AGS_A_Perf.Value
              IN_VeDMAB_y_StatusByte_AGS_B_Perf_Value: accessed-variable=VeDMAB_y_StatusByte_AGS_B_Perf.Value
              IN_VeDMAB_y_StatusByte_BattCool_Value: accessed-variable=VeDMAB_y_StatusByte_BattCool.Value
              IN_VeDMAB_y_StatusByte_BattCoolPmpATempSnsrPerf_Value: accessed-variable=VeDMAB_y_StatusByte_BattCoolPmpATempSnsrPerf.Value
              IN_VeDMAB_y_StatusByte_BattCoolPmpHtrBTempSnsrPerf_Value: accessed-variable=VeDMAB_y_StatusByte_BattCoolPmpHtrBTempSnsrPerf.Value
              IN_VeDMAB_y_StatusByte_BattCoolPmpOveSpd_Value: accessed-variable=VeDMAB_y_StatusByte_BattCoolPmpOveSpd.Value
              IN_VeDMAB_y_StatusByte_BattCoolPmpPerf_Value: accessed-variable=VeDMAB_y_StatusByte_BattCoolPmpPerf.Value
              IN_VeDMAB_y_StatusByte_CT3_SnsrCktHi_Value: accessed-variable=VeDMAB_y_StatusByte_CT3_SnsrCktHi.Value
              IN_VeDMAB_y_StatusByte_CT3_SnsrCktLo_Value: accessed-variable=VeDMAB_y_StatusByte_CT3_SnsrCktLo.Value
              IN_VeDMAB_y_StatusByte_CT3_SnsrPerf_Value: accessed-variable=VeDMAB_y_StatusByte_CT3_SnsrPerf.Value
              IN_VeDMAB_y_StatusByte_CT_SnsrPerf_Value: accessed-variable=VeDMAB_y_StatusByte_CT_SnsrPerf.Value
              IN_VeDMAB_y_StatusByte_CommBusOff_Value: accessed-variable=VeDMAB_y_StatusByte_CommBusOff.Value
              IN_VeDMAB_y_StatusByte_CommBus_B_Off_Value: accessed-variable=VeDMAB_y_StatusByte_CommBus_B_Off.Value
              IN_VeDMAB_y_StatusByte_CoolCtrlVlv1CktHi_Value: accessed-variable=VeDMAB_y_StatusByte_CoolCtrlVlv1CktHi.Value
              IN_VeDMAB_y_StatusByte_CoolOutTempSnsCkt_Value: accessed-variable=VeDMAB_y_StatusByte_CoolOutTempSnsCkt.Value
              IN_VeDMAB_y_StatusByte_CoolPmpACtrlCktPerf_Value: accessed-variable=VeDMAB_y_StatusByte_CoolPmpACtrlCktPerf.Value
              IN_VeDMAB_y_StatusByte_CoolantHeaterBPerf_Value: accessed-variable=VeDMAB_y_StatusByte_CoolantHeaterBPerf.Value
              IN_VeDMAB_y_StatusByte_CoolantVlvA_Ckt_Value: accessed-variable=VeDMAB_y_StatusByte_CoolantVlvA_Ckt.Value
              IN_VeDMAB_y_StatusByte_CoolantVlvA_CktHi_Value: accessed-variable=VeDMAB_y_StatusByte_CoolantVlvA_CktHi.Value
              IN_VeDMAB_y_StatusByte_CoolantVlvA_CktLo_Value: accessed-variable=VeDMAB_y_StatusByte_CoolantVlvA_CktLo.Value
              IN_VeDMAB_y_StatusByte_CoolantVlvA_Perf_Value: accessed-variable=VeDMAB_y_StatusByte_CoolantVlvA_Perf.Value
              IN_VeDMAB_y_StatusByte_CoolantVlvA_StkOpn_Value: accessed-variable=VeDMAB_y_StatusByte_CoolantVlvA_StkOpn.Value
              IN_VeDMAB_y_StatusByte_EACPerf_Value: accessed-variable=VeDMAB_y_StatusByte_EACPerf.Value
              IN_VeDMAB_y_StatusByte_ECH_TempIn_Value: accessed-variable=VeDMAB_y_StatusByte_ECH_TempIn.Value
              IN_VeDMAB_y_StatusByte_ECH_TempOut_Value: accessed-variable=VeDMAB_y_StatusByte_ECH_TempOut.Value
              IN_VeDMAB_y_StatusByte_ECT_Snsr4CktHi_Value: accessed-variable=VeDMAB_y_StatusByte_ECT_Snsr4CktHi.Value
              IN_VeDMAB_y_StatusByte_ECT_Snsr4CktLo_Value: accessed-variable=VeDMAB_y_StatusByte_ECT_Snsr4CktLo.Value
              IN_VeDMAB_y_StatusByte_ECT_Snsr4CktPerf_Value: accessed-variable=VeDMAB_y_StatusByte_ECT_Snsr4CktPerf.Value
              IN_VeDMAB_y_StatusByte_HB_CT_SnsrPerf_Value: accessed-variable=VeDMAB_y_StatusByte_HB_CT_SnsrPerf.Value
              IN_VeDMAB_y_StatusByte_HiSpdCANCommBus_Value: accessed-variable=VeDMAB_y_StatusByte_HiSpdCANCommBus.Value
              IN_VeDMAB_y_StatusByte_HybEvBatPacCoolCtrlVlv2CtrlCktLo_Value: accessed-variable=VeDMAB_y_StatusByte_HybEvBatPacCoolCtrlVlv2CtrlCktLo.Value
              IN_VeDMAB_y_StatusByte_HybEvBatPacCoolCtrlVlvBPerfStkOff_Value: accessed-variable=VeDMAB_y_StatusByte_HybEvBatPacCoolCtrlVlvBPerfStkOff.Value
              IN_VeDMAB_y_StatusByte_InvData_EAH_Value: accessed-variable=VeDMAB_y_StatusByte_InvData_EAH.Value
              IN_VeDMAB_y_StatusByte_InvData_ECH_Value: accessed-variable=VeDMAB_y_StatusByte_InvData_ECH.Value
              IN_VeDMAB_y_StatusByte_LIN1_BusOff_Value: accessed-variable=VeDMAB_y_StatusByte_LIN1_BusOff.Value
              IN_VeDMAB_y_StatusByte_LIN2_BusOff_Value: accessed-variable=VeDMAB_y_StatusByte_LIN2_BusOff.Value
              IN_VeDMAB_y_StatusByte_LosCommBECM_A_Value: accessed-variable=VeDMAB_y_StatusByte_LosCommBECM_A.Value
              IN_VeDMAB_y_StatusByte_LosCommBECM_A_CANC11_Value: accessed-variable=VeDMAB_y_StatusByte_LosCommBECM_A_CANC11.Value
              IN_VeDMAB_y_StatusByte_LostCommCoolHtrA_Value: accessed-variable=VeDMAB_y_StatusByte_LostCommCoolHtrA.Value
              IN_VeDMAB_y_StatusByte_LostCommCoolPmpA_Value: accessed-variable=VeDMAB_y_StatusByte_LostCommCoolPmpA.Value
              IN_VeDMAB_y_StatusByte_LostCommEAC_Value: accessed-variable=VeDMAB_y_StatusByte_LostCommEAC.Value
              IN_VeDMAB_y_StatusByte_LostCommHB_CoolPmp_Value: accessed-variable=VeDMAB_y_StatusByte_LostCommHB_CoolPmp.Value
              IN_VeDMAB_y_StatusByte_LostCommHB_CooltHtr4_Value: accessed-variable=VeDMAB_y_StatusByte_LostCommHB_CooltHtr4.Value
              IN_VeDMAB_y_StatusByte_LostCommMtrElectCoolPmpA_Value: accessed-variable=VeDMAB_y_StatusByte_LostCommMtrElectCoolPmpA.Value
              IN_VeDMAB_y_StatusByte_LostCommMtrElectCoolPmpB_Value: accessed-variable=VeDMAB_y_StatusByte_LostCommMtrElectCoolPmpB.Value
              IN_VeDMAB_y_StatusByte_LostComm_AGS_A_Value: accessed-variable=VeDMAB_y_StatusByte_LostComm_AGS_A.Value
              IN_VeDMAB_y_StatusByte_LostComm_AGS_B_Value: accessed-variable=VeDMAB_y_StatusByte_LostComm_AGS_B.Value
              IN_VeDMAB_y_StatusByte_MtrElect_CT2_SnsrBCktHi_Value: accessed-variable=VeDMAB_y_StatusByte_MtrElect_CT2_SnsrBCktHi.Value
              IN_VeDMAB_y_StatusByte_MtrElect_CT2_SnsrBCktLo_Value: accessed-variable=VeDMAB_y_StatusByte_MtrElect_CT2_SnsrBCktLo.Value
              IN_VeDMAB_y_StatusByte_MtrElect_CT_SnsrBPerf_Value: accessed-variable=VeDMAB_y_StatusByte_MtrElect_CT_SnsrBPerf.Value
              IN_VeDMAB_y_StatusByte_MtrElect_CT_SnsrPerf_Value: accessed-variable=VeDMAB_y_StatusByte_MtrElect_CT_SnsrPerf.Value
              IN_VeDMAB_y_StatusByte_MtrElect_CooPumBOvrSpd_Value: accessed-variable=VeDMAB_y_StatusByte_MtrElect_CooPumBOvrSpd.Value
              IN_VeDMAB_y_StatusByte_MtrElect_CoolPmpATempSnsrPerf_Value: accessed-variable=VeDMAB_y_StatusByte_MtrElect_CoolPmpATempSnsrPerf.Value
              IN_VeDMAB_y_StatusByte_MtrElect_CoolPmpBTempSnsrPerf_Value: accessed-variable=VeDMAB_y_StatusByte_MtrElect_CoolPmpBTempSnsrPerf.Value
              IN_VeDMAB_y_StatusByte_MtrElect_CoolPumAOvrSpd_Value: accessed-variable=VeDMAB_y_StatusByte_MtrElect_CoolPumAOvrSpd.Value
              IN_VeDMAB_y_StatusByte_MtrElect_CoolPumBCtrlPerf_Value: accessed-variable=VeDMAB_y_StatusByte_MtrElect_CoolPumBCtrlPerf.Value
              IN_VeDMAB_y_StatusByte_PwrElecPmpPerf_Value: accessed-variable=VeDMAB_y_StatusByte_PwrElecPmpPerf.Value
              IN_VeDMAB_y_StatusByte_RadCooTempSnsr3CktHi_Value: accessed-variable=VeDMAB_y_StatusByte_RadCooTempSnsr3CktHi.Value
              IN_VeDMAB_y_StatusByte_RadCooTempSnsr3CktLo_Value: accessed-variable=VeDMAB_y_StatusByte_RadCooTempSnsr3CktLo.Value
              IN_VeDMAB_y_StatusByte_RadCooTempSnsr3CktPerf_Value: accessed-variable=VeDMAB_y_StatusByte_RadCooTempSnsr3CktPerf.Value
              IN_VeDMAB_y_StatusByte_ThrmlRlyCtrlCkt_Value: accessed-variable=VeDMAB_y_StatusByte_ThrmlRlyCtrlCkt.Value
              IN_VeDMDR_e_TurtleMdSts_Value: accessed-variable=VeDMDR_e_TurtleMdSts.Value
              IN_VeDMIR_e_DrvMdRaw_Value: accessed-variable=VeDMIR_e_DrvMdRaw.Value
              IN_VeENGR_T_EngCoolantTemp_Value: accessed-variable=VeENGR_T_EngCoolantTemp.Value
              IN_VeENGR_T_InductionAirTemp_Value: accessed-variable=VeENGR_T_InductionAirTemp.Value
              IN_VeENGR_b_ECT_Sgnl_Rcvd_Value: accessed-variable=VeENGR_b_ECT_Sgnl_Rcvd.Value
              IN_VeENGR_b_ECT_SnsrFA_Value: accessed-variable=VeENGR_b_ECT_SnsrFA.Value
              IN_VeENGR_b_EngSysLowFuel_Value: accessed-variable=VeENGR_b_EngSysLowFuel.Value
              IN_VeESSR_e_EngStartStopSt_Value: accessed-variable=VeESSR_e_EngStartStopSt.Value
              IN_VeFCPR_P_FCPS_ActPwr_Value: accessed-variable=VeFCPR_P_FCPS_ActPwr.Value
              IN_VeFCPR_T_FCPS_HTCoolOutTemp_Value: accessed-variable=VeFCPR_T_FCPS_HTCoolOutTemp.Value
              IN_VeFCPR_b_FCPS_HV_AfterRunSts_Value: accessed-variable=VeFCPR_b_FCPS_HV_AfterRunSts.Value
              IN_VeFCRR_T_FcOutTempSetPoint_Value: accessed-variable=VeFCRR_T_FcOutTempSetPoint.Value
              IN_VeFCRR_b_FcCoolReq_Value: accessed-variable=VeFCRR_b_FcCoolReq.Value
              IN_VeFCRR_b_FcHeatReq_Value: accessed-variable=VeFCRR_b_FcHeatReq.Value
              IN_VeFCRR_e_FcTempRange_Value: accessed-variable=VeFCRR_e_FcTempRange.Value
              IN_VeFSCR_Pct_AGS1_MinAchvblPos_Value: accessed-variable=VeFSCR_Pct_AGS1_MinAchvblPos.Value
              IN_VeFSCR_Pct_AGS2_MinAchvblPos_Value: accessed-variable=VeFSCR_Pct_AGS2_MinAchvblPos.Value
              IN_VeFSCR_Pct_RadFanCmd_Value: accessed-variable=VeFSCR_Pct_RadFanCmd.Value
              IN_VeFSCR_b_AGS2_CalSuccess_Value: accessed-variable=VeFSCR_b_AGS2_CalSuccess.Value
              IN_VeFSCR_b_AGS_CalSuccess_Value: accessed-variable=VeFSCR_b_AGS_CalSuccess.Value
              IN_VeFSCR_b_HVFuncRejHdAjar_Value: accessed-variable=VeFSCR_b_HVFuncRejHdAjar.Value
              IN_VeFSCR_b_HoodAjarBatCrit_Value: accessed-variable=VeFSCR_b_HoodAjarBatCrit.Value
              IN_VeFSCR_b_RadFan_FltDtct_Value: accessed-variable=VeFSCR_b_RadFan_FltDtct.Value
              IN_VeGENR_b_HVDspt_Enbl_Value: accessed-variable=VeGENR_b_HVDspt_Enbl.Value
              IN_VeHCCR_dV_FlowLimiterPump1_Value: accessed-variable=VeHCCR_dV_FlowLimiterPump1.Value, variation-point={short-label=vpIN_VeHCCR_dV_FlowLimiterPump1_Value, sw-syscond=1}
              IN_VeHCCR_dV_FlowLimiterPump2_Value: accessed-variable=VeHCCR_dV_FlowLimiterPump2.Value, variation-point={short-label=vpIN_VeHCCR_dV_FlowLimiterPump2_Value, sw-syscond=1}
              IN_VeHCCR_dV_LubFlowPump1_Value: accessed-variable=VeHCCR_dV_LubFlowPump1.Value, variation-point={short-label=vpIN_VeHCCR_dV_LubFlowPump1_Value, sw-syscond=1}
              IN_VeHCCR_dV_LubFlowPump2_Value: accessed-variable=VeHCCR_dV_LubFlowPump2.Value, variation-point={short-label=vpIN_VeHCCR_dV_LubFlowPump2_Value, sw-syscond=1}
              IN_VeHCDR_b_HVC_Heater_FltDtct_Value: accessed-variable=VeHCDR_b_HVC_Heater_FltDtct.Value
              IN_VeHCDR_b_HV_Heater{2..4}_FltDtct_Value: accessed-variable=VeHCDR_b_HV_Heater{2..4}_FltDtct.Value
              IN_VeHCDR_e_BatteryThermalFault_Value: accessed-variable=VeHCDR_e_BatteryThermalFault.Value
              IN_VeHPMR_b_PropSysActv_Value: accessed-variable=VeHPMR_b_PropSysActv.Value
              IN_VeHPMR_e_HybSysSt_Value: accessed-variable=VeHPMR_e_HybSysSt.Value
              IN_VeHTDR_M_MtrA_TorqCmnd_Value: accessed-variable=VeHTDR_M_MtrA_TorqCmnd.Value
              IN_VeHTDR_M_MtrB_TorqCmnd_Value: accessed-variable=VeHTDR_M_MtrB_TorqCmnd.Value
              IN_VeHTDR_M_MtrC_TorqCmnd_Value: accessed-variable=VeHTDR_M_MtrC_TorqCmnd.Value
              IN_VeHTDR_P_MtrAElecPwrCalcTot_Value: accessed-variable=VeHTDR_P_MtrAElecPwrCalcTot.Value
              IN_VeHTDR_P_MtrBElecPwrCalcTot_Value: accessed-variable=VeHTDR_P_MtrBElecPwrCalcTot.Value
              IN_VeHTDR_P_MtrCElecPwrCalcTot_Value: accessed-variable=VeHTDR_P_MtrCElecPwrCalcTot.Value
              IN_VeHTDR_r_AHH_StressFactor_Value: accessed-variable=VeHTDR_r_AHH_StressFactor.Value
              IN_VeHTIR_P_HVC_Htr4PwrExpectd_Value: accessed-variable=VeHTIR_P_HVC_Htr4PwrExpectd.Value
              IN_VeHTIR_P_HVC_HtrPwrAct_Value: accessed-variable=VeHTIR_P_HVC_HtrPwrAct.Value
              IN_VeHTIR_P_HVC_HtrPwrExpectd_Value: accessed-variable=VeHTIR_P_HVC_HtrPwrExpectd.Value
              IN_VeHTIR_T_HVC_HtrClntIn_Temp_Value: accessed-variable=VeHTIR_T_HVC_HtrClntIn_Temp.Value
              IN_VeHTIR_T_HVC_HtrClntOut_Temp_Value: accessed-variable=VeHTIR_T_HVC_HtrClntOut_Temp.Value
              IN_VeHTIR_T_Htr2CoreTemp_Value: accessed-variable=VeHTIR_T_Htr2CoreTemp.Value
              IN_VeHTIR_e_HV_ElecClntHtr2_Sts_Value: accessed-variable=VeHTIR_e_HV_ElecClntHtr2_Sts.Value
              IN_VeHTIR_e_HV_ElecClntHtr4_Sts_Value: accessed-variable=VeHTIR_e_HV_ElecClntHtr4_Sts.Value
              IN_VeHTIR_e_HV_ElecClntHtr_Sts_Value: accessed-variable=VeHTIR_e_HV_ElecClntHtr_Sts.Value
              IN_VeIDCR_T_APMTemp1_Value: accessed-variable=VeIDCR_T_APMTemp1.Value
              IN_VeIDCR_T_APMTemp2_Value: accessed-variable=VeIDCR_T_APMTemp2.Value
              IN_VeIDCR_b_APMTemp1_FA_Value: accessed-variable=VeIDCR_b_APMTemp1_FA.Value
              IN_VeIDCR_b_APMTemp2_FA_Value: accessed-variable=VeIDCR_b_APMTemp2_FA.Value
              IN_VeIMPR_b_HighVoltageRapidShtdwnCmnd_Value: accessed-variable=VeIMPR_b_HighVoltageRapidShtdwnCmnd.Value
              IN_VeINVR_T_BstCnvtrLwrIGBT_TmpFltd_Value: accessed-variable=VeINVR_T_BstCnvtrLwrIGBT_TmpFltd.Value
              IN_VeINVR_T_BstCnvtrReactorTmp_Value: accessed-variable=VeINVR_T_BstCnvtrReactorTmp.Value
              IN_VeINVR_T_BstCnvtrUpprIGBT_TmpFltd_Value: accessed-variable=VeINVR_T_BstCnvtrUpprIGBT_TmpFltd.Value
              IN_VeINVR_T_MtrA_CapctrTemp_Value: accessed-variable=VeINVR_T_MtrA_CapctrTemp.Value
              IN_VeINVR_T_MtrA_ClntIn_Temp_Value: accessed-variable=VeINVR_T_MtrA_ClntIn_Temp.Value
              IN_VeINVR_T_MtrA_ClntOut_Temp_Value: accessed-variable=VeINVR_T_MtrA_ClntOut_Temp.Value
              IN_VeINVR_T_MtrA_CtrlBoard_Temp_Value: accessed-variable=VeINVR_T_MtrA_CtrlBoard_Temp.Value
              IN_VeINVR_T_MtrA_InvrtrTemp_Value: accessed-variable=VeINVR_T_MtrA_InvrtrTemp.Value
              IN_VeINVR_T_MtrA_RotrTemp_Value: accessed-variable=VeINVR_T_MtrA_RotrTemp.Value
              IN_VeINVR_T_MtrA_Temp_Value: accessed-variable=VeINVR_T_MtrA_Temp.Value
              IN_VeINVR_T_MtrB_CapctrTemp_Value: accessed-variable=VeINVR_T_MtrB_CapctrTemp.Value
              IN_VeINVR_T_MtrB_ClntIn_Temp_Value: accessed-variable=VeINVR_T_MtrB_ClntIn_Temp.Value
              IN_VeINVR_T_MtrB_ClntOut_Temp_Value: accessed-variable=VeINVR_T_MtrB_ClntOut_Temp.Value
              IN_VeINVR_T_MtrB_CtrlBoard_Temp_Value: accessed-variable=VeINVR_T_MtrB_CtrlBoard_Temp.Value
              IN_VeINVR_T_MtrB_InvrtrTemp_Value: accessed-variable=VeINVR_T_MtrB_InvrtrTemp.Value
              IN_VeINVR_T_MtrB_RotrTemp_Value: accessed-variable=VeINVR_T_MtrB_RotrTemp.Value
              IN_VeINVR_T_MtrB_Temp_Value: accessed-variable=VeINVR_T_MtrB_Temp.Value
              IN_VeINVR_T_MtrC_CtrlBoard_Temp_Value: accessed-variable=VeINVR_T_MtrC_CtrlBoard_Temp.Value
              IN_VeINVR_T_MtrC_InvrtrTemp_Value: accessed-variable=VeINVR_T_MtrC_InvrtrTemp.Value
              IN_VeINVR_T_MtrC_RotrTemp_Value: accessed-variable=VeINVR_T_MtrC_RotrTemp.Value
              IN_VeINVR_T_MtrC_Temp_Value: accessed-variable=VeINVR_T_MtrC_Temp.Value
              IN_VeINVR_b_BstCnvtrLwrIGBT_TmpFltdFA_Value: accessed-variable=VeINVR_b_BstCnvtrLwrIGBT_TmpFltdFA.Value
              IN_VeINVR_b_BstCnvtrReactorTmpFA_Value: accessed-variable=VeINVR_b_BstCnvtrReactorTmpFA.Value
              IN_VeINVR_b_BstCnvtrUpprIGBT_TmpFltdFA_Value: accessed-variable=VeINVR_b_BstCnvtrUpprIGBT_TmpFltdFA.Value
              IN_VeINVR_b_MtrA_CapctrTemp_FA_Value: accessed-variable=VeINVR_b_MtrA_CapctrTemp_FA.Value
              IN_VeINVR_b_MtrA_ClntIn_Temp_FA_Value: accessed-variable=VeINVR_b_MtrA_ClntIn_Temp_FA.Value
              IN_VeINVR_b_MtrA_ClntOut_Temp_FA_Value: accessed-variable=VeINVR_b_MtrA_ClntOut_Temp_FA.Value
              IN_VeINVR_b_MtrA_CtrlBoard_Temp_FA_Value: accessed-variable=VeINVR_b_MtrA_CtrlBoard_Temp_FA.Value
              IN_VeINVR_b_MtrA_InvrtrTempFA_Value: accessed-variable=VeINVR_b_MtrA_InvrtrTempFA.Value
              IN_VeINVR_b_MtrA_RotrTemp_FA_Value: accessed-variable=VeINVR_b_MtrA_RotrTemp_FA.Value
              IN_VeINVR_b_MtrA_TempFA_Value: accessed-variable=VeINVR_b_MtrA_TempFA.Value
              IN_VeINVR_b_MtrB_CapctrTemp_FA_Value: accessed-variable=VeINVR_b_MtrB_CapctrTemp_FA.Value
              IN_VeINVR_b_MtrB_ClntIn_Temp_FA_Value: accessed-variable=VeINVR_b_MtrB_ClntIn_Temp_FA.Value
              IN_VeINVR_b_MtrB_ClntOut_Temp_FA_Value: accessed-variable=VeINVR_b_MtrB_ClntOut_Temp_FA.Value
              IN_VeINVR_b_MtrB_CtrlBoard_Temp_FA_Value: accessed-variable=VeINVR_b_MtrB_CtrlBoard_Temp_FA.Value
              IN_VeINVR_b_MtrB_InvrtrTempFA_Value: accessed-variable=VeINVR_b_MtrB_InvrtrTempFA.Value
              IN_VeINVR_b_MtrB_RotrTemp_FA_Value: accessed-variable=VeINVR_b_MtrB_RotrTemp_FA.Value
              IN_VeINVR_b_MtrB_TempFA_Value: accessed-variable=VeINVR_b_MtrB_TempFA.Value
              IN_VeINVR_b_MtrC_CtrlBoard_Temp_FA_Value: accessed-variable=VeINVR_b_MtrC_CtrlBoard_Temp_FA.Value
              IN_VeINVR_b_MtrC_InvrtrTempFA_Value: accessed-variable=VeINVR_b_MtrC_InvrtrTempFA.Value
              IN_VeINVR_b_MtrC_RotrTemp_FA_Value: accessed-variable=VeINVR_b_MtrC_RotrTemp_FA.Value
              IN_VeINVR_b_MtrC_TempFA_Value: accessed-variable=VeINVR_b_MtrC_TempFA.Value
              IN_VeMSPR_n_MtrA_Spd_Value: accessed-variable=VeMSPR_n_MtrA_Spd.Value
              IN_VeMSPR_n_MtrB_Spd_Value: accessed-variable=VeMSPR_n_MtrB_Spd.Value
              IN_VeMSPR_n_MtrC_Spd_Value: accessed-variable=VeMSPR_n_MtrC_Spd.Value
              IN_VeMTIR_M_MtrA_TorqAchieved_Value: accessed-variable=VeMTIR_M_MtrA_TorqAchieved.Value
              IN_VeMTIR_M_MtrB_TorqAchieved_Value: accessed-variable=VeMTIR_M_MtrB_TorqAchieved.Value
              IN_VeMTIR_M_MtrC_TorqAchieved_Value: accessed-variable=VeMTIR_M_MtrC_TorqAchieved.Value
              IN_VeOBCR_I_ChrgCrntReqDelta_Value: accessed-variable=VeOBCR_I_ChrgCrntReqDelta.Value
              IN_VeOBCR_P_AvalPwrForThmr_Value: accessed-variable=VeOBCR_P_AvalPwrForThmr.Value
              IN_VeOBCR_e_ChargingLevel_Value: accessed-variable=VeOBCR_e_ChargingLevel.Value
              IN_VeOBCR_e_PwrLevSet_Value: accessed-variable=VeOBCR_e_PwrLevSet.Value
              IN_VePDTR_b_KeyRunCrnk_BattOV_Value: accessed-variable=VePDTR_b_KeyRunCrnk_BattOV.Value
              IN_VePDTR_b_KeyRun_OV_BattCrit_Value: accessed-variable=VePDTR_b_KeyRun_OV_BattCrit.Value
              IN_VePDTR_b_OV_EPD_BattCool_Req_Value: accessed-variable=VePDTR_b_OV_EPD_BattCool_Req.Value
              IN_VePDTR_b_OV_EPD_BattHeat_Req_Value: accessed-variable=VePDTR_b_OV_EPD_BattHeat_Req.Value
              IN_VePDTR_e_EngOrBattPwrDschg_State_Value: accessed-variable=VePDTR_e_EngOrBattPwrDschg_State.Value
              IN_VePLTR_b_DriverDetected_Value: accessed-variable=VePLTR_b_DriverDetected.Value
              IN_VePLTR_b_DrvDrAjar_Value: accessed-variable=VePLTR_b_DrvDrAjar.Value
              IN_VePLTR_b_REMDisabled_Value: accessed-variable=VePLTR_b_REMDisabled.Value
              IN_VePLTR_e_ShippingMode_Value: accessed-variable=VePLTR_e_ShippingMode.Value
              IN_VePLTR_t_RTC_CurrentTime_Value: accessed-variable=VePLTR_t_RTC_CurrentTime.Value
              IN_VePMDR_e_KeyStatus_Value: accessed-variable=VePMDR_e_KeyStatus.Value
              IN_VePMIR_Pct_ECM_LTPsvPumpRq_Value: accessed-variable=VePMIR_Pct_ECM_LTPsvPumpRq.Value
              IN_VePMIR_T_HTAuxPumpTemp_Value: accessed-variable=VePMIR_T_HTAuxPumpTemp.Value
              IN_VePMIR_T_LTPsvPump2Temp_Value: accessed-variable=VePMIR_T_LTPsvPump2Temp.Value
              IN_VePMIR_T_TransAuxPump2OilTemp_Value: accessed-variable=VePMIR_T_TransAuxPump2OilTemp.Value
              IN_VePMIR_T_TransAuxPumpOilTemp_Value: accessed-variable=VePMIR_T_TransAuxPumpOilTemp.Value
              IN_VePMIR_b_ECM_LTPsvPumpRq_FA_Value: accessed-variable=VePMIR_b_ECM_LTPsvPumpRq_FA.Value
              IN_VePMIR_b_HTAuxPumpDryRun_FA_Value: accessed-variable=VePMIR_b_HTAuxPumpDryRun_FA.Value
              IN_VePMIR_b_LTActvPumpDryRun_FA_Value: accessed-variable=VePMIR_b_LTActvPumpDryRun_FA.Value
              IN_VePMIR_b_LTActvPumpRespErr_Value: accessed-variable=VePMIR_b_LTActvPumpRespErr.Value
              IN_VePMIR_b_LTPsvPump2Temp_FA_Value: accessed-variable=VePMIR_b_LTPsvPump2Temp_FA.Value
              IN_VePMIR_b_LTPsvPumpTemp_FA_Value: accessed-variable=VePMIR_b_LTPsvPumpTemp_FA.Value
              IN_VePMIR_b_TransAuxPump2OilTemp_FA_Value: accessed-variable=VePMIR_b_TransAuxPump2OilTemp_FA.Value
              IN_VePMIR_b_TransAuxPumpOilTemp_FA_Value: accessed-variable=VePMIR_b_TransAuxPumpOilTemp_FA.Value
              IN_VePMIR_e_HTAuxPumpDryRun_Value: accessed-variable=VePMIR_e_HTAuxPumpDryRun.Value
              IN_VePMIR_e_LTActvPumpDryRun_Value: accessed-variable=VePMIR_e_LTActvPumpDryRun.Value
              IN_VePMIR_n_HTAuxPumpRPMAct_Value: accessed-variable=VePMIR_n_HTAuxPumpRPMAct.Value
              IN_VePMIR_n_LTActvPumpRPMAct_Value: accessed-variable=VePMIR_n_LTActvPumpRPMAct.Value
              IN_VePMIR_n_LTPsvPump2RPMAct_Value: accessed-variable=VePMIR_n_LTPsvPump2RPMAct.Value
              IN_VePMIR_n_LTPsvPump_RPMAct_Value: accessed-variable=VePMIR_n_LTPsvPump_RPMAct.Value
              IN_VePMPR_b_HTAuxPump_Flt_Dtctd_Value: accessed-variable=VePMPR_b_HTAuxPump_Flt_Dtctd.Value
              IN_VePMPR_b_LTActPump_Flt_Dtctd_Value: accessed-variable=VePMPR_b_LTActPump_Flt_Dtctd.Value
              IN_VePMPR_b_LTPsvPump2_Flt_Dtctd_Value: accessed-variable=VePMPR_b_LTPsvPump2_Flt_Dtctd.Value
              IN_VePMPR_b_LTPsvPump_Flt_Dtctd_Value: accessed-variable=VePMPR_b_LTPsvPump_Flt_Dtctd.Value
              IN_VePMPR_dV_BattFlw_Value: accessed-variable=VePMPR_dV_BattFlw.Value
              IN_VePMPR_dV_HtrFlw_Value: accessed-variable=VePMPR_dV_HtrFlw.Value
              IN_VePMPR_dV_LTRFlw_Value: accessed-variable=VePMPR_dV_LTRFlw.Value
              IN_VePMPR_e_LTPsvPump2_PstRnSt_Value: accessed-variable=VePMPR_e_LTPsvPump2_PstRnSt.Value
              IN_VePMPR_e_LTPsvPump_PstRnSt_Value: accessed-variable=VePMPR_e_LTPsvPump_PstRnSt.Value
              IN_VePMPR_n_LT_ActvPmpCmd_Value: accessed-variable=VePMPR_n_LT_ActvPmpCmd.Value
              IN_VePMPR_n_PECP2_RPM_Op_St_Value: accessed-variable=VePMPR_n_PECP2_RPM_Op_St.Value
              IN_VePMPR_n_PECP_RPM_Op_St_Value: accessed-variable=VePMPR_n_PECP_RPM_Op_St.Value
              IN_VePMTR_b_REM_BattCoolAction_Value: accessed-variable=VePMTR_b_REM_BattCoolAction.Value
              IN_VePMTR_b_REM_BattHeatAction_Value: accessed-variable=VePMTR_b_REM_BattHeatAction.Value
              IN_VePMTR_b_REM_CabCoolAction_Value: accessed-variable=VePMTR_b_REM_CabCoolAction.Value
              IN_VePMTR_b_REM_CabHeatAction_Value: accessed-variable=VePMTR_b_REM_CabHeatAction.Value
              IN_VePMTR_b_ThrmlSystRly_EnblCmnd_Value: accessed-variable=VePMTR_b_ThrmlSystRly_EnblCmnd.Value
              IN_VePMTR_e_ThrmlDevEnbl_Value: accessed-variable=VePMTR_e_ThrmlDevEnbl.Value
              IN_VePRXR_y_NumOfAGSUnits_Value: accessed-variable=VePRXR_y_NumOfAGSUnits.Value
              IN_VeRCVR_b_HTCV_Learning_Req_Value: accessed-variable=VeRCVR_b_HTCV_Learning_Req.Value
              IN_VeRCVR_b_RSVCompTransition_Value: accessed-variable=VeRCVR_b_RSVCompTransition.Value
              IN_VeRCVR_e_CPV_Valve_Stuck_State_Value: accessed-variable=VeRCVR_e_CPV_Valve_Stuck_State.Value
              IN_VeRCVR_e_HTL_Valve_Stuck_State_Value: accessed-variable=VeRCVR_e_HTL_Valve_Stuck_State.Value
              IN_VeRCVR_e_HtrCoreBypVlv_Stuck_State_Value: accessed-variable=VeRCVR_e_HtrCoreBypVlv_Stuck_State.Value
              IN_VeRCVR_e_LTR_Valve_Stuck_State_Value: accessed-variable=VeRCVR_e_LTR_Valve_Stuck_State.Value
              IN_VeRCVR_p_eACSuctionPressure_Value: accessed-variable=VeRCVR_p_eACSuctionPressure.Value
              IN_VeSRAR_b_ThmlLoadShdActv_Value: accessed-variable=VeSRAR_b_ThmlLoadShdActv.Value
              IN_VeSSDR_e_KeySts_Value: accessed-variable=VeSSDR_e_KeySts.Value
              IN_VeTAIR_P_AC_CompElecPwr_Value: accessed-variable=VeTAIR_P_AC_CompElecPwr.Value
              IN_VeTAIR_Pct_AGS2_CurrPos_Value: accessed-variable=VeTAIR_Pct_AGS2_CurrPos.Value
              IN_VeTAIR_Pct_AGS_CurrPos_Value: accessed-variable=VeTAIR_Pct_AGS_CurrPos.Value
              IN_VeTAIR_Pct_ECM_RadFanReq_Value: accessed-variable=VeTAIR_Pct_ECM_RadFanReq.Value
              IN_VeTAIR_Pct_FrtBlwrCmd_Value: accessed-variable=VeTAIR_Pct_FrtBlwrCmd.Value
              IN_VeTAIR_Pct_HTL_BypsVlv_ActlPstn_Value: accessed-variable=VeTAIR_Pct_HTL_BypsVlv_ActlPstn.Value
              IN_VeTAIR_Pct_LTR_BypsVlv_ActlPstn_Value: accessed-variable=VeTAIR_Pct_LTR_BypsVlv_ActlPstn.Value
              IN_VeTAIR_Pct_RadFanSts_Value: accessed-variable=VeTAIR_Pct_RadFanSts.Value
              IN_VeTAIR_T_FtEvapTmp_Value: accessed-variable=VeTAIR_T_FtEvapTmp.Value
              IN_VeTAIR_T_FtEvapTmp_Tgt_Value: accessed-variable=VeTAIR_T_FtEvapTmp_Tgt.Value
              IN_VeTAIR_T_OEXV_OutTempSens_Value: accessed-variable=VeTAIR_T_OEXV_OutTempSens.Value
              IN_VeTAIR_b_ACCompReq_Value: accessed-variable=VeTAIR_b_ACCompReq.Value
              IN_VeTAIR_b_AC_CompElecPwr_FA_Value: accessed-variable=VeTAIR_b_AC_CompElecPwr_FA.Value
              IN_VeTAIR_b_HT_CabVlvSts_FA_Value: accessed-variable=VeTAIR_b_HT_CabVlvSts_FA.Value
              IN_VeTAIR_b_HghRfrgtPres_FA_Value: accessed-variable=VeTAIR_b_HghRfrgtPres_FA.Value
              IN_VeTAIR_b_OEXV_OutPressSens_FA_Value: accessed-variable=VeTAIR_b_OEXV_OutPressSens_FA.Value
              IN_VeTAIR_b_WinshldDfrst_Value: accessed-variable=VeTAIR_b_WinshldDfrst.Value
              IN_VeTAIR_n_CompSpdFdb_Value: accessed-variable=VeTAIR_n_CompSpdFdb.Value
              IN_VeTAIR_p_HghRfrgtPres_Value: accessed-variable=VeTAIR_p_HghRfrgtPres.Value
              IN_VeTAIR_p_OEXV_OutPressSens_Value: accessed-variable=VeTAIR_p_OEXV_OutPressSens.Value
              IN_VeTFTR_T_TransOilTemp_Value: accessed-variable=VeTFTR_T_TransOilTemp.Value
              IN_VeTHDR_b_PPCTIS_OT_FltDtct_Value: accessed-variable=VeTHDR_b_PPCTIS_OT_FltDtct.Value
              IN_VeTISR_n_InputSpeed_Value: accessed-variable=VeTISR_n_InputSpeed.Value
              IN_VeTMIR_Pct_BSG_ECM_RadFanRq_Value: accessed-variable=VeTMIR_Pct_BSG_ECM_RadFanRq.Value
              IN_VeTMIR_Pct_BSG_LTR_PmpSpdAct_Value: accessed-variable=VeTMIR_Pct_BSG_LTR_PmpSpdAct.Value
              IN_VeTMIR_Pct_BSG_PPU_AirFlwRq_Value: accessed-variable=VeTMIR_Pct_BSG_PPU_AirFlwRq.Value
              IN_VeTMIR_Pct_TCU_Load_Index_Value: accessed-variable=VeTMIR_Pct_TCU_Load_Index.Value
              IN_VeTMIR_T_CntrlBrdTmp_Snsr1_AD_Value: accessed-variable=VeTMIR_T_CntrlBrdTmp_Snsr1_AD.Value
              IN_VeTMIR_T_CntrlBrdTmp_Snsr2_AD_Value: accessed-variable=VeTMIR_T_CntrlBrdTmp_Snsr2_AD.Value
              IN_VeTMIR_T_ElecClntHtr_TmpIn_Value: accessed-variable=VeTMIR_T_ElecClntHtr_TmpIn.Value
              IN_VeTMIR_T_LTR_ClntTmpOut_Value: accessed-variable=VeTMIR_T_LTR_ClntTmpOut.Value
              IN_VeTMIR_T_OBCMTemp1_Value: accessed-variable=VeTMIR_T_OBCMTemp1.Value
              IN_VeTMIR_T_OBCMTemp2_Value: accessed-variable=VeTMIR_T_OBCMTemp2.Value
              IN_VeTMIR_T_OBCMTemp3_AD_Value: accessed-variable=VeTMIR_T_OBCMTemp3_AD.Value
              IN_VeTMIR_T_OBCMTemp4_AD_Value: accessed-variable=VeTMIR_T_OBCMTemp4_AD.Value
              IN_VeTMIR_T_OnBrdChrg_ClntTmpIn_Value: accessed-variable=VeTMIR_T_OnBrdChrg_ClntTmpIn.Value
              IN_VeTMIR_T_PsvPmpClnt_TmpIn_Value: accessed-variable=VeTMIR_T_PsvPmpClnt_TmpIn.Value
              IN_VeTMIR_b_CntrlBrdTmp_Snsr1_FA_AD_Value: accessed-variable=VeTMIR_b_CntrlBrdTmp_Snsr1_FA_AD.Value
              IN_VeTMIR_b_CntrlBrdTmp_Snsr2_FA_AD_Value: accessed-variable=VeTMIR_b_CntrlBrdTmp_Snsr2_FA_AD.Value
              IN_VeTMIR_b_ECMDrvDoorAjar_Value: accessed-variable=VeTMIR_b_ECMDrvDoorAjar.Value
              IN_VeTMIR_b_ECM_FanAftRunRq_FA_Value: accessed-variable=VeTMIR_b_ECM_FanAftRunRq_FA.Value
              IN_VeTMIR_b_ElecClntHtr_TmpIn_FA_Value: accessed-variable=VeTMIR_b_ElecClntHtr_TmpIn_FA.Value
              IN_VeTMIR_b_LTR_ClntTmpOut_FA_Value: accessed-variable=VeTMIR_b_LTR_ClntTmpOut_FA.Value
              IN_VeTMIR_b_OBCMTemp1_FA_Value: accessed-variable=VeTMIR_b_OBCMTemp1_FA.Value
              IN_VeTMIR_b_OBCMTemp2_FA_Value: accessed-variable=VeTMIR_b_OBCMTemp2_FA.Value
              IN_VeTMIR_b_OBCMTemp3_FA_AD_Value: accessed-variable=VeTMIR_b_OBCMTemp3_FA_AD.Value
              IN_VeTMIR_b_OBCMTemp4_FA_AD_Value: accessed-variable=VeTMIR_b_OBCMTemp4_FA_AD.Value
              IN_VeTMIR_b_OnBrdChrg_ClntTmpIn_FA_Value: accessed-variable=VeTMIR_b_OnBrdChrg_ClntTmpIn_FA.Value
              IN_VeTMIR_b_PsvPmpClnt_TmpIn_FA_Value: accessed-variable=VeTMIR_b_PsvPmpClnt_TmpIn_FA.Value
              IN_VeTMIR_b_TCU_Load_Index_FA_Value: accessed-variable=VeTMIR_b_TCU_Load_Index_FA.Value
              IN_VeTMIR_e_ECM_LTP_FanAftRunRq_Value: accessed-variable=VeTMIR_e_ECM_LTP_FanAftRunRq.Value
              IN_VeTMIR_y_OBCMTemp1_Dbg_Value: accessed-variable=VeTMIR_y_OBCMTemp1_Dbg.Value
              IN_VeTMIR_y_OBCMTemp2_Dbg_Value: accessed-variable=VeTMIR_y_OBCMTemp2_Dbg.Value
              IN_VeTPCR_I_RacePrepCurrentLim_Value: accessed-variable=VeTPCR_I_RacePrepCurrentLim.Value, variation-point={short-label=vpIN_VeTPCR_I_RacePrepCurrentLim_Value, sw-syscond=1}
              IN_VeTPCR_b_CabPrecDny_BattCond_Value: accessed-variable=VeTPCR_b_CabPrecDny_BattCond.Value
              IN_VeTPCR_b_HtrOrEAC_FltRawPrst_Value: accessed-variable=VeTPCR_b_HtrOrEAC_FltRawPrst.Value
              IN_VeTPCR_b_KeyOffCabCond_Value: accessed-variable=VeTPCR_b_KeyOffCabCond.Value
              IN_VeTPCR_b_PeriodWup_Msg2_Value: accessed-variable=VeTPCR_b_PeriodWup_Msg2.Value, variation-point={short-label=vpIN_VeTPCR_b_PeriodWup_Msg2_Value, sw-syscond=1}
              IN_VeTPCR_b_RSA_BatCrit_Msg3_Value: accessed-variable=VeTPCR_b_RSA_BatCrit_Msg3.Value, variation-point={short-label=vpIN_VeTPCR_b_RSA_BatCrit_Msg3_Value, sw-syscond=1}
              IN_VeTPCR_b_RdyForShtDwn_Value: accessed-variable=VeTPCR_b_RdyForShtDwn.Value
              IN_VeTPCR_dT_PerWpCond_BatTmpErr_Value: accessed-variable=VeTPCR_dT_PerWpCond_BatTmpErr.Value
              IN_VeTPCR_dT_PerWpCond_EngTmpErr_Value: accessed-variable=VeTPCR_dT_PerWpCond_EngTmpErr.Value
              IN_VeTPCR_e_CabReqSt_Msgs_Value: accessed-variable=VeTPCR_e_CabReqSt_Msgs.Value
              IN_VeTPCR_e_CabinPreCondReqStat_Value: accessed-variable=VeTPCR_e_CabinPreCondReqStat.Value
              IN_VeTPCR_e_PerWup_BattEngCond_State_Value: accessed-variable=VeTPCR_e_PerWup_BattEngCond_State.Value
              IN_VeTPCR_e_ProactiveCondMode_Value: accessed-variable=VeTPCR_e_ProactiveCondMode.Value
              IN_VeTPCR_e_ProactiveCondStat_Value: accessed-variable=VeTPCR_e_ProactiveCondStat.Value
              IN_VeTPCR_e_RacePrepState_Value: accessed-variable=VeTPCR_e_RacePrepState.Value
              IN_VeTPCR_e_SC_WakeUp_Value: accessed-variable=VeTPCR_e_SC_WakeUp.Value
              IN_VeTPCR_e_ThrmPerWup_State_Value: accessed-variable=VeTPCR_e_ThrmPerWup_State.Value
              IN_VeTPCR_t_BatPerWU_ThrmlCond_Timer_Value: accessed-variable=VeTPCR_t_BatPerWU_ThrmlCond_Timer.Value
              IN_VeTPCR_t_SC_PrecTimer_Value: accessed-variable=VeTPCR_t_SC_PrecTimer.Value
              IN_VeTPDR_P_BattHeater_PwrBdgt_Avail_Value: accessed-variable=VeTPDR_P_BattHeater_PwrBdgt_Avail.Value
              IN_VeTPDR_P_CabinHeater_PwrBdgt_Avail_Value: accessed-variable=VeTPDR_P_CabinHeater_PwrBdgt_Avail.Value
              IN_VeTPDR_P_Rat_EAC_PwrBdgt_Avail_Value: accessed-variable=VeTPDR_P_Rat_EAC_PwrBdgt_Avail.Value
              IN_VeTPDR_P_RearHtr_PwrBdgt_Avail_Value: accessed-variable=VeTPDR_P_RearHtr_PwrBdgt_Avail.Value
              IN_VeTRGR_e_TransDirctnSt_Value: accessed-variable=VeTRGR_e_TransDirctnSt.Value
              IN_VeTRIR_Pct_AirHtrPwrTgt_Value: accessed-variable=VeTRIR_Pct_AirHtrPwrTgt.Value
              IN_VeTRIR_T_HV_BatClntTmpOut_Value: accessed-variable=VeTRIR_T_HV_BatClntTmpOut.Value
              IN_VeTRIR_T_HeatExCool_TmpOut_Value: accessed-variable=VeTRIR_T_HeatExCool_TmpOut.Value
              IN_VeTRIR_T_HtrCorClnt_TmpIn_Value: accessed-variable=VeTRIR_T_HtrCorClnt_TmpIn.Value
              IN_VeTRIR_T_HtrCorClnt_TmpOut_Value: accessed-variable=VeTRIR_T_HtrCorClnt_TmpOut.Value
              IN_VeTRIR_b_AHP_EnblReq_Value: accessed-variable=VeTRIR_b_AHP_EnblReq.Value
              IN_VeTRIR_b_AirHtrPwrTgt_FA_Value: accessed-variable=VeTRIR_b_AirHtrPwrTgt_FA.Value
              IN_VeTRIR_b_ClimateInfo_FA_Value: accessed-variable=VeTRIR_b_ClimateInfo_FA.Value
              IN_VeTRIR_b_HtrCorClnt_TmpIn_FA_Value: accessed-variable=VeTRIR_b_HtrCorClnt_TmpIn_FA.Value
              IN_VeTRIR_b_HtrCorClnt_TmpOut_FA_Value: accessed-variable=VeTRIR_b_HtrCorClnt_TmpOut_FA.Value
              IN_VeTRIR_e_ClimateInfo_Value: accessed-variable=VeTRIR_e_ClimateInfo.Value
              IN_VeTRIR_e_HVACECOModeSts_Value: accessed-variable=VeTRIR_e_HVACECOModeSts.Value
              IN_VeUBTR_T_EstUndrhoodTemp_Value: accessed-variable=VeUBTR_T_EstUndrhoodTemp.Value
              IN_VeVTLR_e_DschrgSysSts_Value: accessed-variable=VeVTLR_e_DschrgSysSts.Value
          data-send-points:
            158 x access:
              OUT_VeTHMR_T_ECH_ClntTempTgt_Value: accessed-variable=VeTHMR_T_ECH_ClntTempTgt.Value
              OUT_VeTHMR_P_ECH_HtrPwrTgt_Value: accessed-variable=VeTHMR_P_ECH_HtrPwrTgt.Value
              OUT_VeTHMR_y_Htr_Oprtn_State_Value: accessed-variable=VeTHMR_y_Htr_Oprtn_State.Value
              OUT_VeTHMR_T_Htr2ClntTempTgt_Value: accessed-variable=VeTHMR_T_Htr2ClntTempTgt.Value
              OUT_VeTHMR_P_Htr2PwrTgt_Value: accessed-variable=VeTHMR_P_Htr2PwrTgt.Value
              OUT_VeTHMR_T_Htr3ClntTempTgt_Value: accessed-variable=VeTHMR_T_Htr3ClntTempTgt.Value
              OUT_VeTHMR_P_Htr3PwrTgt_Value: accessed-variable=VeTHMR_P_Htr3PwrTgt.Value
              OUT_VeTHMR_T_Htr4ClntTempTgt_Value: accessed-variable=VeTHMR_T_Htr4ClntTempTgt.Value
              OUT_VeTHMR_P_Htr4PwrTgt_Value: accessed-variable=VeTHMR_P_Htr4PwrTgt.Value
              OUT_VeTHMR_y_Htr_Slctn_State_Value: accessed-variable=VeTHMR_y_Htr_Slctn_State.Value
              OUT_VeTHMR_e_VehThermSt_Value: accessed-variable=VeTHMR_e_VehThermSt.Value
              OUT_VeTHMR_T_MinBattAllow_Value: accessed-variable=VeTHMR_T_MinBattAllow.Value
              OUT_VeTHMR_T_MaxBattAllow_Value: accessed-variable=VeTHMR_T_MaxBattAllow.Value
              OUT_VeTHMR_T_MaxBattAllowPsv_Value: accessed-variable=VeTHMR_T_MaxBattAllowPsv.Value
              OUT_VeTHMR_T_MinBattAllowPsv_Value: accessed-variable=VeTHMR_T_MinBattAllowPsv.Value
              OUT_VeTHMR_T_BattClntMinTgt_Value: accessed-variable=VeTHMR_T_BattClntMinTgt.Value
              OUT_VeTHMR_b_CabReq_NotAllow_Value: accessed-variable=VeTHMR_b_CabReq_NotAllow.Value
              OUT_VeTHMR_b_CabAllowed_Value: accessed-variable=VeTHMR_b_CabAllowed.Value
              OUT_VeTHMR_dV_LT_ActvPmpFlow_Value: accessed-variable=VeTHMR_dV_LT_ActvPmpFlow.Value
              OUT_VeTHMR_dV_LT_PsvPmpFlow_Value: accessed-variable=VeTHMR_dV_LT_PsvPmpFlow.Value
              OUT_VeTHMR_dV_HT_AuxPmpFlow_Value: accessed-variable=VeTHMR_dV_HT_AuxPmpFlow.Value
              OUT_VeTHMR_e_ClntPmpState_Value: accessed-variable=VeTHMR_e_ClntPmpState.Value
              OUT_VeTHMR_b_LTPsvPmp_ClntWarmUp_Value: accessed-variable=VeTHMR_b_LTPsvPmp_ClntWarmUp.Value
              OUT_VeTHMR_b_LTActvPmp_ClntWarmUp_Value: accessed-variable=VeTHMR_b_LTActvPmp_ClntWarmUp.Value
              OUT_VeTHMR_b_HTAuxPmp_ClntWarmUp_Value: accessed-variable=VeTHMR_b_HTAuxPmp_ClntWarmUp.Value
              OUT_VeTHMR_dV_LT_PsvPmp2Flow_Value: accessed-variable=VeTHMR_dV_LT_PsvPmp2Flow.Value
              OUT_VeTHMR_b_LTPsvPmp2_ClntWarmUp_Value: accessed-variable=VeTHMR_b_LTPsvPmp2_ClntWarmUp.Value
              OUT_VeTHMR_y_ClntPump_Slctd_State_Value: accessed-variable=VeTHMR_y_ClntPump_Slctd_State.Value
              OUT_VeTHMR_y_ClntPump_Oprtng_State_Value: accessed-variable=VeTHMR_y_ClntPump_Oprtng_State.Value
              OUT_VeTHMR_dV_LTR_Flw_Tgt_Value: accessed-variable=VeTHMR_dV_LTR_Flw_Tgt.Value
              OUT_VeTHMR_y_PumpEnbl_Value: accessed-variable=VeTHMR_y_PumpEnbl.Value
              OUT_VeTHMR_b_CabPrecond_Value: accessed-variable=VeTHMR_b_CabPrecond.Value
              OUT_VeTHMR_b_PerWup_Value: accessed-variable=VeTHMR_b_PerWup.Value
              OUT_VeTHMR_Pct_ClntProp3WyVlv_Cmd_Value: accessed-variable=VeTHMR_Pct_ClntProp3WyVlv_Cmd.Value
              OUT_VeTHMR_e_ClntNProp3WyVlv_State_Value: accessed-variable=VeTHMR_e_ClntNProp3WyVlv_State.Value
              OUT_VeTHMR_e_ClntProp3WyVlv_State_Value: accessed-variable=VeTHMR_e_ClntProp3WyVlv_State.Value
              OUT_VeTHMR_b_HTCV_LearnEnb_Value: accessed-variable=VeTHMR_b_HTCV_LearnEnb.Value
              OUT_VeTHMR_e_RefShtoffVlv_State_Value: accessed-variable=VeTHMR_e_RefShtoffVlv_State.Value
              OUT_VeTHMR_Pct_LINPrpVlv_Cmd_Value: accessed-variable=VeTHMR_Pct_LINPrpVlv_Cmd.Value
              OUT_VeTHMR_b_LINPrpVlv_CalibReq_Value: accessed-variable=VeTHMR_b_LINPrpVlv_CalibReq.Value
              OUT_VeTHMR_b_LINPrpVlv_SvReq_Value: accessed-variable=VeTHMR_b_LINPrpVlv_SvReq.Value
              OUT_VeTHMR_P_EDU_Heat_Cabin_Available_Value: accessed-variable=VeTHMR_P_EDU_Heat_Cabin_Available.Value
              OUT_VeTHMR_P_EDU_Heat_Battery_Available_Value: accessed-variable=VeTHMR_P_EDU_Heat_Battery_Available.Value
              OUT_VeTHMR_Pct_LTL_Vlv_Cmd_Value: accessed-variable=VeTHMR_Pct_LTL_Vlv_Cmd.Value
              OUT_VeTHMR_n_LTLPECP1MBC_Value: accessed-variable=VeTHMR_n_LTLPECP1MBC.Value
              OUT_VeTHMR_n_LTLPECP2MBC_Value: accessed-variable=VeTHMR_n_LTLPECP2MBC.Value
              OUT_VeTHMR_Pct_AirFlowReq_Value: accessed-variable=VeTHMR_Pct_AirFlowReq.Value
              OUT_VeTHMR_e_RadFan_State_Value: accessed-variable=VeTHMR_e_RadFan_State.Value
              OUT_VeTHMR_b_AGS_State_Value: accessed-variable=VeTHMR_b_AGS_State.Value
              OUT_VeTHMR_e_EmrgcyFanRq_Lvl_Value: accessed-variable=VeTHMR_e_EmrgcyFanRq_Lvl.Value
              OUT_VeTHMR_Pct_HCP_AGS_Req_Value: accessed-variable=VeTHMR_Pct_HCP_AGS_Req.Value
              OUT_VeTHMR_Pct_AGS_PosReq_Value: accessed-variable=VeTHMR_Pct_AGS_PosReq.Value
              OUT_VeTHMR_Pct_AGS2_PosReq_Value: accessed-variable=VeTHMR_Pct_AGS2_PosReq.Value
              OUT_VeTHMR_dT_CellOverTemp_Value: accessed-variable=VeTHMR_dT_CellOverTemp.Value
              OUT_VeTHMR_b_BattCondPlugin_Rq_Value: accessed-variable=VeTHMR_b_BattCondPlugin_Rq.Value
              OUT_VeTHMR_b_RmtStrtAbort_StrtVhclRq_Value: accessed-variable=VeTHMR_b_RmtStrtAbort_StrtVhclRq.Value
              OUT_VeTHMR_e_EngOrBattPwrDschg_State_Value: accessed-variable=VeTHMR_e_EngOrBattPwrDschg_State.Value
              OUT_VeTHMR_P_PwrBdgt_PwrLimitAvail_Value: accessed-variable=VeTHMR_P_PwrBdgt_PwrLimitAvail.Value
              OUT_VeTHMR_P_Rat_EAC_PwrBdgt_Avail_Value: accessed-variable=VeTHMR_P_Rat_EAC_PwrBdgt_Avail.Value
              OUT_VeTHMR_b_BattAllowed_Value: accessed-variable=VeTHMR_b_BattAllowed.Value
              OUT_VeTHMR_b_LTAP_ExpctdOff_Value: accessed-variable=VeTHMR_b_LTAP_ExpctdOff.Value
              OUT_VeTHMR_r_BattCabPriority_Ratio_Value: accessed-variable=VeTHMR_r_BattCabPriority_Ratio.Value
              OUT_VeTHMR_b_DrvDrAjar_Value: accessed-variable=VeTHMR_b_DrvDrAjar.Value
              OUT_VeTHMR_e_HCP_LTP_FanAftRun_Rq_Value: accessed-variable=VeTHMR_e_HCP_LTP_FanAftRun_Rq.Value
              OUT_VeTHMR_b_RdyForShtDwn_Value: accessed-variable=VeTHMR_b_RdyForShtDwn.Value
              OUT_VeTHMR_e_ThrmSysShtDwnFlt_Value: accessed-variable=VeTHMR_e_ThrmSysShtDwnFlt.Value
              OUT_VeTHMR_b_HV_BatTempCrit_Cond_Value: accessed-variable=VeTHMR_b_HV_BatTempCrit_Cond.Value
              OUT_VeTHMR_b_HVAC_HeatReq_Value: accessed-variable=VeTHMR_b_HVAC_HeatReq.Value
              OUT_VeTHMR_b_ThermSystEng_Req_Value: accessed-variable=VeTHMR_b_ThermSystEng_Req.Value
              OUT_VeTHMR_b_VhclStatus_Value: accessed-variable=VeTHMR_b_VhclStatus.Value
              OUT_VeTHMR_t_BatPerWU_ThrmlCond_Timer_Value: accessed-variable=VeTHMR_t_BatPerWU_ThrmlCond_Timer.Value
              OUT_VeTHMR_b_HVAC_turnedOff_Value: accessed-variable=VeTHMR_b_HVAC_turnedOff.Value
              OUT_VeTHMR_b_StartVhcl_ToMaintain12Vlt_Value: accessed-variable=VeTHMR_b_StartVhcl_ToMaintain12Vlt.Value
              OUT_VeTHMR_b_LeaveKeyIn_RUN_Value: accessed-variable=VeTHMR_b_LeaveKeyIn_RUN.Value
              OUT_VeTHMR_e_HV_Bat_CltLvlLo_Value: accessed-variable=VeTHMR_e_HV_Bat_CltLvlLo.Value
              OUT_VeTHMR_b_HtrCorClnt_Tmp_InFA_Value: accessed-variable=VeTHMR_b_HtrCorClnt_Tmp_InFA.Value
              OUT_VeTHMR_b_HCP_LTP_FanAftRun_Rq_Value: accessed-variable=VeTHMR_b_HCP_LTP_FanAftRun_Rq.Value
              OUT_VeTHMR_b_BattOVFailure_Value: accessed-variable=VeTHMR_b_BattOVFailure.Value
              OUT_VeTHMR_b_AftrRunFanRqst_Value: accessed-variable=VeTHMR_b_AftrRunFanRqst.Value
              OUT_VeTHMR_b_DisblFunc_Msg_10_Value: accessed-variable=VeTHMR_b_DisblFunc_Msg_10.Value
              OUT_VeTHMR_e_HVAC_PerfModeFlg_Value: accessed-variable=VeTHMR_e_HVAC_PerfModeFlg.Value
              OUT_VeTHMR_b_ThermalHybAltMode_Rq_Value: accessed-variable=VeTHMR_b_ThermalHybAltMode_Rq.Value
              OUT_VeTHMR_b_KeyXstnOFF_Value: accessed-variable=VeTHMR_b_KeyXstnOFF.Value
              OUT_VeTHMR_n_BTLPumpMBCReq_Value: accessed-variable=VeTHMR_n_BTLPumpMBCReq.Value
              OUT_VeTHMR_e_BatThrmlSt_Value: accessed-variable=VeTHMR_e_BatThrmlSt.Value
              OUT_VeTHMR_T_HtrCorClnt_TmpIn_Value: accessed-variable=VeTHMR_T_HtrCorClnt_TmpIn.Value
              OUT_VeTHMR_b_isCharging_Value: accessed-variable=VeTHMR_b_isCharging.Value
              OUT_VeTHMR_e_CabinPreCondReqStat_Value: accessed-variable=VeTHMR_e_CabinPreCondReqStat.Value
              OUT_VeTHMR_e_AC_CompState_Value: accessed-variable=VeTHMR_e_AC_CompState.Value
              OUT_VeTHMR_b_ActRemCompDecision_Value: accessed-variable=VeTHMR_b_ActRemCompDecision.Value
              OUT_VeTHMR_e_Eng_Htr_HTSOV_Stat_Value: accessed-variable=VeTHMR_e_Eng_Htr_HTSOV_Stat.Value
              OUT_VeTHMR_e_PPCTIS_OT_Value: accessed-variable=VeTHMR_e_PPCTIS_OT.Value
              OUT_VeTHMR_t_SC_PrecTimer_Value: accessed-variable=VeTHMR_t_SC_PrecTimer.Value
              OUT_VeTHMR_e_SC_WkUp_Value: accessed-variable=VeTHMR_e_SC_WkUp.Value
              OUT_VeTHMR_e_CabPrecondReqSt_Value: accessed-variable=VeTHMR_e_CabPrecondReqSt.Value
              OUT_VeTHMR_b_CabPrecDny_BattCond_Value: accessed-variable=VeTHMR_b_CabPrecDny_BattCond.Value
              OUT_VeTHMR_e_CabinPreCondReqMsg_Value: accessed-variable=VeTHMR_e_CabinPreCondReqMsg.Value
              OUT_VeTHMR_b_SC_WkUpFlg_Value: accessed-variable=VeTHMR_b_SC_WkUpFlg.Value
              OUT_VeTHMR_b_PerWup_EngtoCond_Value: accessed-variable=VeTHMR_b_PerWup_EngtoCond.Value
              OUT_VeTHMR_P_PerWup_EngHeatNeed_Value: accessed-variable=VeTHMR_P_PerWup_EngHeatNeed.Value
              OUT_VeTHMR_P_EnginePwr_Available_Value: accessed-variable=VeTHMR_P_EnginePwr_Available.Value
              OUT_VeTHMR_Pct_HTL_BypsVlv_Cmd_Value: accessed-variable=VeTHMR_Pct_HTL_BypsVlv_Cmd.Value
              OUT_VeTHMR_n_HTLPumpMBCReq_Value: accessed-variable=VeTHMR_n_HTLPumpMBCReq.Value
              OUT_VeTHMR_T_AHPInletTempArb_Value: accessed-variable=VeTHMR_T_AHPInletTempArb.Value
              OUT_VeTHMR_P_WCondCabHeat_Avail_Value: accessed-variable=VeTHMR_P_WCondCabHeat_Avail.Value
              OUT_VeTHMR_P_CabHeatPwrNeed_Value: accessed-variable=VeTHMR_P_CabHeatPwrNeed.Value
              OUT_VeTHMR_b_FCHeatAllwd_Value: accessed-variable=VeTHMR_b_FCHeatAllwd.Value
              OUT_VeTHMR_Pct_BSG_LTR_PmpFlwRq_Value: accessed-variable=VeTHMR_Pct_BSG_LTR_PmpFlwRq.Value
              OUT_VeTHMR_dV_MGU_ClntPumpFlw_Value: accessed-variable=VeTHMR_dV_MGU_ClntPumpFlw.Value
              OUT_VeTHMR_n_EngSpdInc_Req_Value: accessed-variable=VeTHMR_n_EngSpdInc_Req.Value
              OUT_VeTHMR_b_LatcdImpct_Value: accessed-variable=VeTHMR_b_LatcdImpct.Value
              OUT_VeTHMR_b_BattSharedHeaterAllowed_Value: accessed-variable=VeTHMR_b_BattSharedHeaterAllowed.Value
              OUT_VeTHMR_e_CabThermalMode_Value: accessed-variable=VeTHMR_e_CabThermalMode.Value
              OUT_VeTHMR_e_CabHeatThermalState_Value: accessed-variable=VeTHMR_e_CabHeatThermalState.Value
              OUT_VeTHMR_e_CabCoolThermalState_Value: accessed-variable=VeTHMR_e_CabCoolThermalState.Value
              OUT_VeTHMR_e_LTCLRadVlvState_Value: accessed-variable=VeTHMR_e_LTCLRadVlvState.Value
              OUT_VeTHMR_e_LTCLThrmlMode_Value: accessed-variable=VeTHMR_e_LTCLThrmlMode.Value
              OUT_VeTHMR_T_PPCTIS_Arb_Value: accessed-variable=VeTHMR_T_PPCTIS_Arb.Value
              OUT_VeTHMR_b_DeiceActv_Value: accessed-variable=VeTHMR_b_DeiceActv.Value
              OUT_VeTHMR_e_CabHeatThermalMode_Value: accessed-variable=VeTHMR_e_CabHeatThermalMode.Value
              OUT_VeTHMR_i_ModeIndex_Value: accessed-variable=VeTHMR_i_ModeIndex.Value
              OUT_VeTHMR_b_FC_CondAllwd_Value: accessed-variable=VeTHMR_b_FC_CondAllwd.Value
              OUT_VeTHMR_e_FCThrmlState_Value: accessed-variable=VeTHMR_e_FCThrmlState.Value
              OUT_VeTHMR_dV_MtrA_CoolFlwCmd_Value: accessed-variable=VeTHMR_dV_MtrA_CoolFlwCmd.Value
              OUT_VeTHMR_dV_MtrB_CoolFlwCmd_Value: accessed-variable=VeTHMR_dV_MtrB_CoolFlwCmd.Value
              OUT_VeTHMR_b_HV_BatRdyLocal_True_Value: accessed-variable=VeTHMR_b_HV_BatRdyLocal_True.Value
              OUT_VeTHMR_b_HVBR_UsgEnb_Value: accessed-variable=VeTHMR_b_HVBR_UsgEnb.Value
              OUT_VeTHMR_b_RS_N_Or_NrmlPerWp_Value: accessed-variable=VeTHMR_b_RS_N_Or_NrmlPerWp.Value
              OUT_VeTHMR_e_HTCL_Heat_Distrib_Value: accessed-variable=VeTHMR_e_HTCL_Heat_Distrib.Value
              OUT_VeTHMR_b_HTCV_RAEnbl_BattTmpHi_Value: accessed-variable=VeTHMR_b_HTCV_RAEnbl_BattTmpHi.Value
              OUT_VeTHMR_dV_FCL_ClntFlowTgt_Value: accessed-variable=VeTHMR_dV_FCL_ClntFlowTgt.Value, variation-point={short-label=vpOUT_VeTHMR_dV_FCL_ClntFlowTgt_Value, sw-syscond=1}
              OUT_VeTHMR_Pct_FC_Vlv_Cmd_Value: accessed-variable=VeTHMR_Pct_FC_Vlv_Cmd.Value, variation-point={short-label=vpOUT_VeTHMR_Pct_FC_Vlv_Cmd_Value, sw-syscond=1}
              OUT_VeTHMR_e_EOP_A_EmrgCoolState_Value: accessed-variable=VeTHMR_e_EOP_A_EmrgCoolState.Value
              OUT_VeTHMR_e_EOP_B_EmrgCoolState_Value: accessed-variable=VeTHMR_e_EOP_B_EmrgCoolState.Value
              OUT_VeTHMR_r_HvHrnMtrAPowerLimit_Value: accessed-variable=VeTHMR_r_HvHrnMtrAPowerLimit.Value
              OUT_VeTHMR_b_HvHrnMtrAPowerLimit_Value: accessed-variable=VeTHMR_b_HvHrnMtrAPowerLimit.Value
              OUT_VeTHMR_r_HvHrnMtrBPowerLimit_Value: accessed-variable=VeTHMR_r_HvHrnMtrBPowerLimit.Value
              OUT_VeTHMR_b_HvHrnMtrBPowerLimit_Value: accessed-variable=VeTHMR_b_HvHrnMtrBPowerLimit.Value
              OUT_VeTHMR_r_HvHrnMtrCPowerLimit_Value: accessed-variable=VeTHMR_r_HvHrnMtrCPowerLimit.Value
              OUT_VeTHMR_b_HvHrnMtrCPowerLimit_Value: accessed-variable=VeTHMR_b_HvHrnMtrCPowerLimit.Value
              OUT_VeTHMR_dV_Branch_{1..3}_Flw_Value: accessed-variable=VeTHMR_dV_Branch_{1..3}_Flw.Value
              OUT_VeTHMR_b_AAD_RetrctReq_Value: accessed-variable=VeTHMR_b_AAD_RetrctReq.Value
              OUT_VeTHMR_b_FEDMHeatEstm_SNAflag_Value: accessed-variable=VeTHMR_b_FEDMHeatEstm_SNAflag.Value
              OUT_VeTHMR_b_REDMHeatEstm_SNAflag_Value: accessed-variable=VeTHMR_b_REDMHeatEstm_SNAflag.Value
              OUT_VeTHMR_T_LTCLTgt_BattActvPsvHeating_Value: accessed-variable=VeTHMR_T_LTCLTgt_BattActvPsvHeating.Value
              OUT_VeTHMR_I_ChargeCurrentLim_Value: accessed-variable=VeTHMR_I_ChargeCurrentLim.Value
              OUT_VeTHMR_Pct_HtrCoreBypssVlv_Value: accessed-variable=VeTHMR_Pct_HtrCoreBypssVlv.Value
              OUT_VeTHMR_Pct_FCCP_Req_Value: accessed-variable=VeTHMR_Pct_FCCP_Req.Value
              OUT_VeTHMR_Pct_FCHTRRadFanReq_Value: accessed-variable=VeTHMR_Pct_FCHTRRadFanReq.Value
              OUT_VeTHMR_P_FCPSThrmlPwr_MaxAllwd_Value: accessed-variable=VeTHMR_P_FCPSThrmlPwr_MaxAllwd.Value
              OUT_VeTHMR_Pct_LTRSolitaryAGS_PosReq_Value: accessed-variable=VeTHMR_Pct_LTRSolitaryAGS_PosReq.Value
              OUT_VeTHMR_Pct_HTRSolitaryAGS_PosReq_Value: accessed-variable=VeTHMR_Pct_HTRSolitaryAGS_PosReq.Value
              OUT_VeTHMR_Pct_BTRSolitaryAGS_PosReq_Value: accessed-variable=VeTHMR_Pct_BTRSolitaryAGS_PosReq.Value
              OUT_VeTHMR_Pct_LTR_AirFlowReq_Value: accessed-variable=VeTHMR_Pct_LTR_AirFlowReq.Value
              OUT_VeTHMR_Pct_HTR_AirFlowReq_Value: accessed-variable=VeTHMR_Pct_HTR_AirFlowReq.Value
              OUT_VeTHMR_Pct_BTR_AirFlowReq_Value: accessed-variable=VeTHMR_Pct_BTR_AirFlowReq.Value
          parameter access CALPRM_KeTHMR_b_TurtleMd_SelDial_KeTHMR_b_TurtleMd_SelDial: accessed-parameter=KeTHMR_b_TurtleMd_SelDial.KeTHMR_b_TurtleMd_SelDial
          parameter access CALPRM_KeTHMR_e_TurtleMd_Dial_KeTHMR_e_TurtleMd_Dial: accessed-parameter=KeTHMR_e_TurtleMd_Dial.KeTHMR_e_TurtleMd_Dial
          read-local-variables:
            4 x access:
              RV_BattCntctrOpenPndg_AD_write_IRV: accessed-variable=BattCntctrOpenPndg_AD_write_IRV
              RV_OutAirTemp_EstV_AftDial_write_IRV: accessed-variable=OutAirTemp_EstV_AftDial_write_IRV
              RV_OutAirTemp_Est_AftDial_write_IRV: accessed-variable=OutAirTemp_Est_AftDial_write_IRV
              RV_PropSysActv_THMR_AftDial_write_IRV: accessed-variable=PropSysActv_THMR_AftDial_write_IRV
        THMR_PwrOff
          data-send-points:
            access OUT_NeTMIR_e_HCP_LTP_FanAftRun_Rq_NeTMIR_e_HCP_LTP_FanAftRun_Rq: accessed-variable=NeTMIR_e_HCP_LTP_FanAftRun_Rq.NeTMIR_e_HCP_LTP_FanAftRun_Rq
            access OUT_NeTHMR_t_PumpRunTmr_NeTHMR_t_PumpRunTmr: accessed-variable=NeTHMR_t_PumpRunTmr.NeTHMR_t_PumpRunTmr
            access OUT_NeTHMR_t_PumpStrtTimeT1_NeTHMR_t_PumpStrtTimeT1: accessed-variable=NeTHMR_t_PumpStrtTimeT1.NeTHMR_t_PumpStrtTimeT1
      25 x variation point proxy, all with category=CONDITION:
        Variant_THMR_FUNC_RU_ActiveAirDam: condition-access=0
        Variant_THMR_FUNC_RU_BattHtr_Pwr_RA_En: condition-access=0
        Variant_THMR_FUNC_RU_BattRadiator_Equip: condition-access=0
        Variant_THMR_FUNC_RU_DsblPSAChk_BattAllwd_MHEV: condition-access=1
        Variant_THMR_FUNC_RU_DsblPmpFrBatt: condition-access=1
        Variant_THMR_FUNC_RU_ECM_Absent: condition-access=1
        Variant_THMR_FUNC_RU_EnblBattCabPriority: condition-access=1
        Variant_THMR_FUNC_RU_EnblCabPrecSPR_VehThrmlSt: condition-access=1
        Variant_THMR_FUNC_RU_EnblMtrAPI: condition-access=0
        Variant_THMR_FUNC_RU_EnblMtrBPI: condition-access=0
        Variant_THMR_FUNC_RU_EnblMtrCPI: condition-access=0
        Variant_THMR_FUNC_RU_EnblRA_BattCoolingFlt_PsvCool: condition-access=1
        Variant_THMR_FUNC_RU_Enbl_TrtlMd: condition-access=1
        Variant_THMR_FUNC_RU_EngOnChk_BattAllwd_MHEV: condition-access=1
        Variant_THMR_FUNC_RU_FCS_Absent: condition-access=1
        Variant_THMR_FUNC_RU_FCS_Absent0: condition-access=0
        Variant_THMR_FUNC_RU_FlashingFlagDsblMsg10: condition-access=0
        Variant_THMR_FUNC_RU_MBCHTLLTL_EnblCodeGen0: condition-access=0
        Variant_THMR_FUNC_RU_MBCHTLLTL_EnblCodeGen1: condition-access=1
        Variant_THMR_FUNC_RU_OvrdPmpReq: condition-access=1
        Variant_THMR_FUNC_RU_P1MotorReqDsbl: condition-access=0
        Variant_THMR_FUNC_RU_PerWup_EngToCond_En: condition-access=0
        Variant_THMR_FUNC_RU_Program_Selctd: condition-access=1
        Variant_THMR_FUNC_RU_RacePrepCrrntLim: condition-access=1
        Variant_THMR_FUNC_RU_ShrdBattCab_Heater: condition-access=1
